VERSION ""

NS_ :

BS_:

BU_: TestTool_HS BCP_HS ECM_HS TCM_HS CGM_HS BCM_HS EBCM_OBD_HS ACCM_HS EBCM_HS TCCM_HS SAS_HS ICCM_OBD_HS ICCM_HS EPS_HS EPB_HS HMIM_HS ONSTAR_HS

BO_ 565 Performan_Mode_Cust_Setings_1_HS: 5 EBCM_HS
 SG_ PerfMdMainMenuType : 2|3@0+ (1,0) [0|7] ""  BCM_HS
 SG_ PSPMCA_PsngStPrfMd6Avl : 24|1@0+ (1,0) [0|1] ""  BCM_HS
 SG_ PSPMCA_PsngStPrfMd5Avl : 25|1@0+ (1,0) [0|1] ""  BCM_HS
 SG_ PSPMCA_PsngStPrfMd4Avl : 26|1@0+ (1,0) [0|1] ""  BCM_HS
 SG_ PSPMCA_PsngStPrfMd3Avl : 27|1@0+ (1,0) [0|1] ""  BCM_HS
 SG_ PSPMCA_PsngStPrfMd2Avl : 28|1@0+ (1,0) [0|1] ""  BCM_HS
 SG_ PSPMCA_PsngStPrfMd1Avl : 29|1@0+ (1,0) [0|1] ""  BCM_HS
 SG_ DSPMCA_DrvStyPrfMd7Avl : 32|1@0+ (1,0) [0|1] ""  BCM_HS
 SG_ DSPMCA_DrvStyPrfMd6Avl : 33|1@0+ (1,0) [0|1] ""  BCM_HS
 SG_ DSPMCA_DrvStyPrfMd5Avl : 34|1@0+ (1,0) [0|1] ""  BCM_HS
 SG_ DSPMCA_DrvStyPrfMd4Avl : 35|1@0+ (1,0) [0|1] ""  BCM_HS
 SG_ DSPMCA_DrvStyPrfMd3Avl : 36|1@0+ (1,0) [0|1] ""  BCM_HS
 SG_ DSPMCA_DrvStyPrfMd2Avl : 37|1@0+ (1,0) [0|1] ""  BCM_HS
 SG_ DSPMCA_DrvStyPrfMd1Avl : 38|1@0+ (1,0) [0|1] ""  BCM_HS
 SG_ DSPMCA_DrvrStPrfMd6Avl : 16|1@0+ (1,0) [0|1] ""  BCM_HS
 SG_ DSPMCA_DrvrStPrfMd5Avl : 17|1@0+ (1,0) [0|1] ""  BCM_HS
 SG_ DSPMCA_DrvrStPrfMd4Avl : 18|1@0+ (1,0) [0|1] ""  BCM_HS
 SG_ DSPMCA_DrvrStPrfMd3Avl : 19|1@0+ (1,0) [0|1] ""  BCM_HS
 SG_ DSPMCA_DrvrStPrfMd2Avl : 20|1@0+ (1,0) [0|1] ""  BCM_HS
 SG_ DSPMCA_DrvrStPrfMd1Avl : 21|1@0+ (1,0) [0|1] ""  BCM_HS
 SG_ ACCPMCA_ACCPrfMd6Avl : 8|1@0+ (1,0) [0|1] ""  BCM_HS
 SG_ ACCPMCA_ACCPrfMd5Avl : 9|1@0+ (1,0) [0|1] ""  BCM_HS
 SG_ ACCPMCA_ACCPrfMd4Avl : 10|1@0+ (1,0) [0|1] ""  BCM_HS
 SG_ ACCPMCA_ACCPrfMd3Avl : 11|1@0+ (1,0) [0|1] ""  BCM_HS
 SG_ ACCPMCA_ACCPrfMd2Avl : 12|1@0+ (1,0) [0|1] ""  BCM_HS
 SG_ ACCPMCA_ACCPrfMd1Avl : 13|1@0+ (1,0) [0|1] ""  BCM_HS

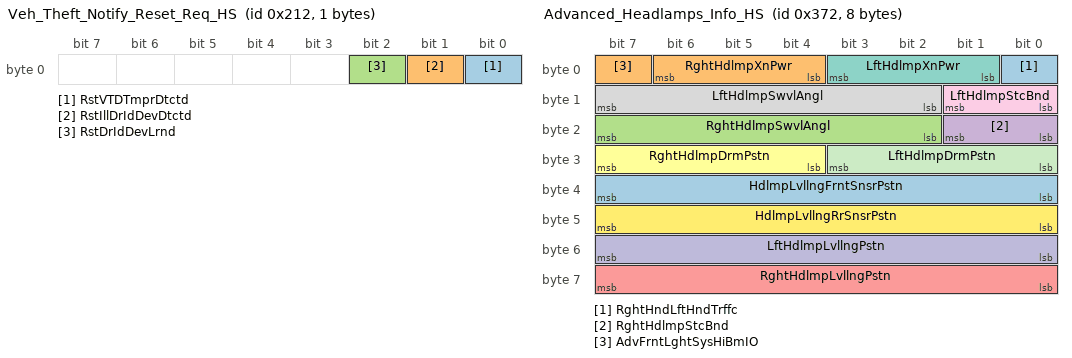
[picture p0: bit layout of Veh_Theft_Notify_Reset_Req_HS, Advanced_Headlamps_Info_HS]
BO_ 530 Veh_Theft_Notify_Reset_Req_HS: 1 CGM_HS
 SG_ RstVTDTmprDtctd : 0|1@0+ (1,0) [0|1] ""  BCM_HS
 SG_ RstIllDrIdDevDtctd : 1|1@0+ (1,0) [0|1] ""  BCM_HS
 SG_ RstDrIdDevLrnd : 2|1@0+ (1,0) [0|1] ""  BCM_HS

BO_ 368 Environment_Id_Resp_5_HS: 3 ONSTAR_HS
 SG_ EnvIdRspSt5 : 17|2@0+ (1,0) [0|3] ""  BCM_HS
 SG_ EnvIdRsp5 : 7|16@0+ (1,0) [0|65535] ""  BCM_HS

BO_ 882 Advanced_Headlamps_Info_HS: 8 CGM_HS
 SG_ RghtHndLftHndTrffc : 0|1@0+ (1,0) [0|1] "" Vector__XXX
 SG_ RghtHdlmpXnPwr : 6|3@0+ (1,32) [32|39] "Watt" Vector__XXX
 SG_ RghtHdlmpSwvlAngl : 23|6@0- (0.5,0) [-16|15.5] "deg" Vector__XXX
 SG_ RghtHdlmpStcBnd : 17|2@0+ (25,25) [25|100] "%" Vector__XXX
 SG_ RghtHdlmpLvllngPstn : 63|8@0- (0.05,0) [-6.4|6.35] "%" Vector__XXX
 SG_ RghtHdlmpDrmPstn : 31|4@0+ (1,1) [1|16] "" Vector__XXX
 SG_ LftHdlmpXnPwr : 3|3@0+ (1,32) [32|39] "Watt" Vector__XXX
 SG_ LftHdlmpSwvlAngl : 15|6@0- (0.5,0) [-16|15.5] "deg" Vector__XXX
 SG_ LftHdlmpStcBnd : 9|2@0+ (25,25) [25|100] "%" Vector__XXX
 SG_ LftHdlmpLvllngPstn : 55|8@0- (0.05,0) [-6.4|6.35] "%" Vector__XXX
 SG_ LftHdlmpDrmPstn : 27|4@0+ (1,1) [1|16] "" Vector__XXX
 SG_ HdlmpLvllngRrSnsrPstn : 47|8@0- (1,0) [-128|127] "mm" Vector__XXX
 SG_ HdlmpLvllngFrntSnsrPstn : 39|8@0- (1,0) [-128|127] "mm" Vector__XXX
 SG_ AdvFrntLghtSysHiBmIO : 7|1@0+ (1,0) [0|1] ""  BCM_HS

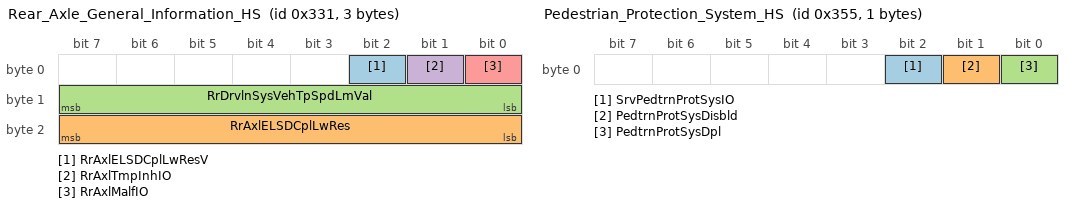
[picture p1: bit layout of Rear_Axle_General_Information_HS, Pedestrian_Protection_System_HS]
BO_ 817 Rear_Axle_General_Information_HS: 3 ICCM_HS
 SG_ RrAxlELSDCplLwResV : 2|1@0+ (1,0) [0|1] ""  BCM_HS
 SG_ RrAxlELSDCplLwRes : 23|8@0+ (10,0) [0|2550] "Nm"  BCM_HS
 SG_ RrDrvlnSysVehTpSpdLmVal : 15|8@0+ (2,0) [0|510] "km/h"  BCM_HS
 SG_ RrAxlTmpInhIO : 1|1@0+ (1,0) [0|1] ""  BCM_HS
 SG_ RrAxlMalfIO : 0|1@0+ (1,0) [0|1] ""  EBCM_OBD_HS,EBCM_HS,BCM_HS

BO_ 853 Pedestrian_Protection_System_HS: 1 CGM_HS
 SG_ SrvPedtrnProtSysIO : 2|1@0+ (1,0) [0|1] ""  BCM_HS
 SG_ PedtrnProtSysDisbld : 1|1@0+ (1,0) [0|1] ""  BCM_HS
 SG_ PedtrnProtSysDpl : 0|1@0+ (1,0) [0|1] ""  BCM_HS

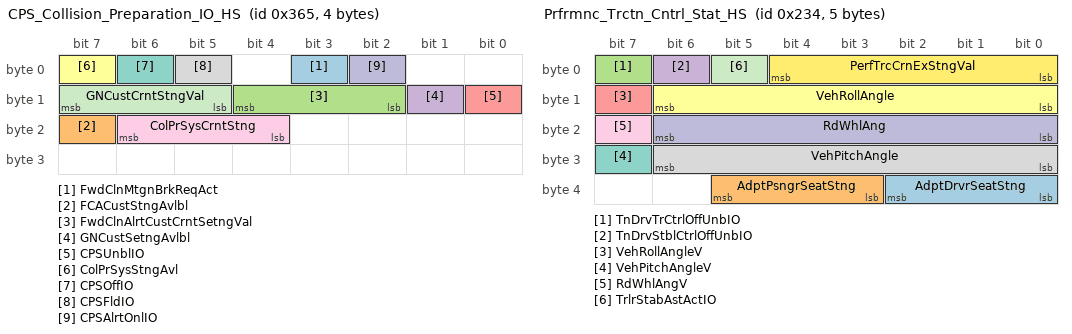
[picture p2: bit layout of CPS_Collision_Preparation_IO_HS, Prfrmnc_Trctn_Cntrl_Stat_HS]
BO_ 869 CPS_Collision_Preparation_IO_HS: 4 CGM_HS
 SG_ FwdClnMtgnBrkReqAct : 3|1@0+ (1,0) [0|1] ""  BCM_HS
 SG_ FCACustStngAvlbl : 23|1@0+ (1,0) [0|1] ""  BCM_HS
 SG_ FwdClnAlrtCustCrntSetngVal : 12|3@0+ (1,0) [0|7] ""  BCM_HS
 SG_ GNCustSetngAvlbl : 9|1@0+ (1,0) [0|1] ""  BCM_HS
 SG_ CPSUnblIO : 8|1@0+ (1,0) [0|1] ""  BCM_HS
 SG_ ColPrSysStngAvl : 7|1@0+ (1,0) [0|1] ""  BCM_HS
 SG_ CPSOffIO : 6|1@0+ (1,0) [0|1] ""  BCM_HS
 SG_ CPSFldIO : 5|1@0+ (1,0) [0|1] ""  BCM_HS
 SG_ ColPrSysCrntStng : 22|3@0+ (1,0) [0|7] ""  BCM_HS
 SG_ CPSAlrtOnlIO : 2|1@0+ (1,0) [0|1] ""  BCM_HS
 SG_ GNCustCrntStngVal : 15|3@0+ (1,0) [0|7] ""  BCM_HS

BO_ 564 Prfrmnc_Trctn_Cntrl_Stat_HS: 5 EBCM_HS
 SG_ AdptDrvrSeatStng : 34|3@0+ (1,0) [0|7] ""  CGM_HS,BCM_HS
 SG_ AdptPsngrSeatStng : 37|3@0+ (1,0) [0|7] ""  CGM_HS,BCM_HS
 SG_ TnDrvTrCtrlOffUnbIO : 7|1@0+ (1,0) [0|1] ""  CGM_HS,BCM_HS
 SG_ TnDrvStblCtrlOffUnbIO : 6|1@0+ (1,0) [0|1] ""  CGM_HS,BCM_HS
 SG_ VehRollAngleV : 15|1@0+ (1,0) [0|1] ""  CGM_HS,BCM_HS
 SG_ VehRollAngle : 14|7@0+ (0.703125,-45) [-45|44.296875] "deg"  CGM_HS,BCM_HS
 SG_ VehPitchAngleV : 31|1@0+ (1,0) [0|1] ""  CGM_HS,BCM_HS
 SG_ VehPitchAngle : 30|7@0+ (0.703125,-45) [-45|44.296875] "deg"  CGM_HS,BCM_HS
 SG_ RdWhlAngV : 23|1@0+ (1,0) [0|1] ""  CGM_HS,BCM_HS
 SG_ RdWhlAng : 22|7@0+ (0.703125,-45) [-45|44.296875] "deg"  CGM_HS,BCM_HS
 SG_ TrlrStabAstActIO : 5|1@0+ (1,0) [0|1] ""  CGM_HS,BCM_HS
 SG_ PerfTrcCrnExStngVal : 4|5@0+ (1,0) [0|31] ""  CGM_HS,BCM_HS

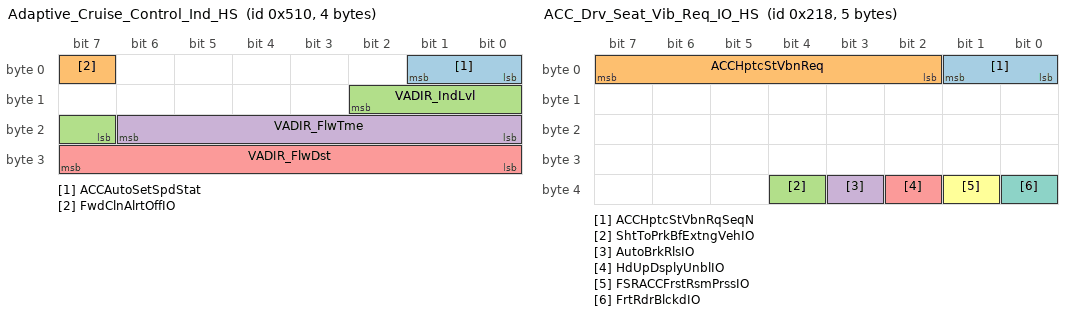
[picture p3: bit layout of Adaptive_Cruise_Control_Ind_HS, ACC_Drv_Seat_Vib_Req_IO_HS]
BO_ 1296 Adaptive_Cruise_Control_Ind_HS: 4 CGM_HS
 SG_ ACCAutoSetSpdStat : 1|2@0+ (1,0) [0|3] ""  BCM_HS
 SG_ FwdClnAlrtOffIO : 7|1@0+ (1,0) [0|1] ""  BCM_HS
 SG_ VADIR_IndLvl : 10|4@0+ (1,0) [0|15] ""  BCM_HS
 SG_ VADIR_FlwTme : 22|7@0+ (0.1,0) [0|12.7] "s"  BCM_HS
 SG_ VADIR_FlwDst : 31|8@0+ (1,0) [0|255] "m"  BCM_HS

BO_ 536 ACC_Drv_Seat_Vib_Req_IO_HS: 5 CGM_HS
 SG_ ACCHptcStVbnRqSeqN : 1|2@0+ (1,0) [0|3] ""  BCM_HS
 SG_ ACCHptcStVbnReq : 7|6@0+ (1,0) [0|63] ""  BCM_HS
 SG_ ShtToPrkBfExtngVehIO : 36|1@0+ (1,0) [0|1] ""  BCM_HS
 SG_ AutoBrkRlsIO : 35|1@0+ (1,0) [0|1] ""  BCM_HS
 SG_ HdUpDsplyUnblIO : 34|1@0+ (1,0) [0|1] ""  BCM_HS
 SG_ FSRACCFrstRsmPrssIO : 33|1@0+ (1,0) [0|1] ""  BCM_HS
 SG_ FrtRdrBlckdIO : 32|1@0+ (1,0) [0|1] ""  BCM_HS

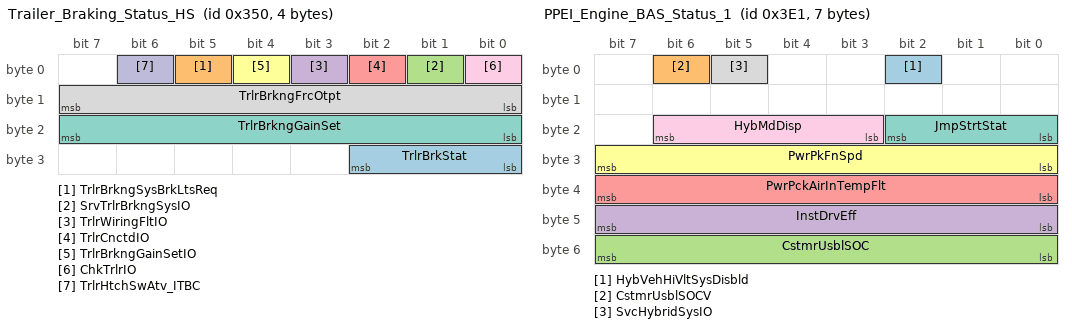
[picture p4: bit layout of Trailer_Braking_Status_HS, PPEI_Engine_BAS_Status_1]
BO_ 848 Trailer_Braking_Status_HS: 4 ICCM_HS
 SG_ TrlrBrkStat : 26|3@0+ (1,0) [0|7] ""  CGM_HS,EBCM_OBD_HS,EBCM_HS
 SG_ TrlrBrkngSysBrkLtsReq : 5|1@0+ (1,0) [0|1] ""  CGM_HS,BCM_HS
 SG_ SrvTrlrBrkngSysIO : 1|1@0+ (1,0) [0|1] ""  CGM_HS,BCM_HS
 SG_ TrlrWiringFltIO : 3|1@0+ (1,0) [0|1] ""  CGM_HS,BCM_HS
 SG_ TrlrCnctdIO : 2|1@0+ (1,0) [0|1] ""  CGM_HS,BCM_HS
 SG_ TrlrBrkngGainSetIO : 4|1@0+ (1,0) [0|1] ""  CGM_HS,BCM_HS
 SG_ TrlrBrkngGainSet : 23|8@0+ (0.392157,0) [0|100.000035] "%"  CGM_HS,EBCM_OBD_HS,EBCM_HS,BCM_HS
 SG_ TrlrBrkngFrcOtpt : 15|8@0+ (0.392157,0) [0|100.000035] "%"  CGM_HS,EBCM_OBD_HS,EBCM_HS,BCM_HS
 SG_ ChkTrlrIO : 0|1@0+ (1,0) [0|1] ""  CGM_HS,BCM_HS
 SG_ TrlrHtchSwAtv_ITBC : 6|1@0+ (1,0) [0|1] ""  CGM_HS,BCM_HS

BO_ 993 PPEI_Engine_BAS_Status_1: 7 BCP_HS
 SG_ HybVehHiVltSysDisbld : 2|1@0+ (1,0) [0|1] ""  CGM_HS,ONSTAR_HS
 SG_ CstmrUsblSOCV : 6|1@0+ (1,0) [0|1] ""  CGM_HS,BCM_HS
 SG_ CstmrUsblSOC : 55|8@0+ (0.39216,0) [0|100.0008] "%"  CGM_HS,BCM_HS
 SG_ InstDrvEff : 47|8@0- (0.78125,0) [-100|99.21875] "%"  CGM_HS,BCM_HS
 SG_ PwrPckAirInTempFlt : 39|8@0+ (1,-40) [-40|215] "deg C"  CGM_HS,BCM_HS
 SG_ PwrPkFnSpd : 31|8@0+ (0.392157,0) [0|100.000035] "%"  CGM_HS,BCM_HS
 SG_ JmpStrtStat : 18|3@0+ (1,0) [0|7] ""  CGM_HS,BCM_HS
 SG_ SvcHybridSysIO : 5|1@0+ (1,0) [0|1] ""  CGM_HS,BCM_HS
 SG_ HybMdDisp : 22|4@0+ (1,0) [0|15] ""  CGM_HS,BCM_HS

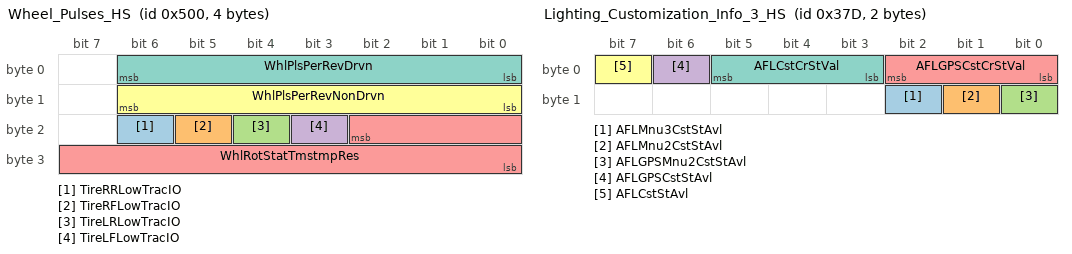
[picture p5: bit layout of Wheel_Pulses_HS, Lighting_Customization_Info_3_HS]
BO_ 1280 Wheel_Pulses_HS: 4 EBCM_HS
 SG_ TireRRLowTracIO : 22|1@0+ (1,0) [0|1] ""  CGM_HS,BCM_HS
 SG_ TireRFLowTracIO : 21|1@0+ (1,0) [0|1] ""  CGM_HS,BCM_HS
 SG_ TireLRLowTracIO : 20|1@0+ (1,0) [0|1] ""  CGM_HS,BCM_HS
 SG_ TireLFLowTracIO : 19|1@0+ (1,0) [0|1] ""  CGM_HS,BCM_HS
 SG_ WhlRotStatTmstmpRes : 18|11@0+ (0.002,0) [0|4.094] "uSec"  CGM_HS,ICCM_OBD_HS,HMIM_HS,EPS_HS,ICCM_HS,EPB_HS,TCCM_HS,BCM_HS
 SG_ WhlPlsPerRevNonDrvn : 14|7@0+ (1,0) [0|127] ""  CGM_HS,ICCM_OBD_HS,HMIM_HS,ONSTAR_HS,EPS_HS,ICCM_HS,EPB_HS,TCCM_HS,BCM_HS
 SG_ WhlPlsPerRevDrvn : 6|7@0+ (1,0) [0|127] ""  CGM_HS,ICCM_OBD_HS,HMIM_HS,ONSTAR_HS,EPS_HS,ICCM_HS,EPB_HS,TCCM_HS,BCM_HS

BO_ 562 Driving_Mode_Control_HS: 8 EBCM_HS
 SG_ DrvlneMntsPerfMdRq : 50|3@0+ (1,0) [0|7] ""  CGM_HS,ICCM_OBD_HS,ICCM_HS
 SG_ RideCntrlPerfMdRq : 18|3@0+ (1,0) [0|7] ""  CGM_HS
 SG_ StgSysPerfMdRq : 29|3@0+ (1,0) [0|7] ""  CGM_HS,EPS_HS
 SG_ DiffPerfMdRq : 26|3@0+ (1,0) [0|7] ""  CGM_HS,ICCM_OBD_HS,ICCM_HS
 SG_ ExhstPerfMdRq : 5|3@0+ (1,0) [0|7] ""  CGM_HS,ICCM_OBD_HS,ICCM_HS
 SG_ DrvMdCntrlState : 39|8@0+ (1,0) [0|255] ""  CGM_HS,EPS_HS
 SG_ AWDPerfMdRq : 2|3@0+ (1,0) [0|7] ""  CGM_HS,TCCM_HS
 SG_ DispPerfMdCsCrStVal : 58|3@0+ (1,0) [0|7] ""  CGM_HS,BCM_HS
 SG_ SndEnhcmtPerfMdRq : 13|3@0+ (1,0) [0|7] ""  CGM_HS,BCM_HS
 SG_ DsplyPerfMdRq : 10|3@0+ (1,0) [0|7] ""  CGM_HS,BCM_HS
 SG_ HillDscntCntlSysStat : 55|3@0+ (1,0) [0|7] ""  CGM_HS,BCM_HS
 SG_ SusCustStngAvlbl : 23|1@0+ (1,0) [0|1] ""  CGM_HS,ONSTAR_HS,BCM_HS
 SG_ SusCustCurrStngVal : 45|3@0+ (1,0) [0|7] ""  CGM_HS,ONSTAR_HS,BCM_HS
 SG_ StrCustStngAvlbl : 7|1@0+ (1,0) [0|1] ""  CGM_HS,ONSTAR_HS,BCM_HS
 SG_ StrCustCurrStngVal : 42|3@0+ (1,0) [0|7] ""  CGM_HS,ONSTAR_HS,BCM_HS
 SG_ DrvlnCustStngAvlbl : 6|1@0+ (1,0) [0|1] ""  CGM_HS,ONSTAR_HS,BCM_HS
 SG_ DrvlnCustCurrStngVal : 22|3@0+ (1,0) [0|7] ""  CGM_HS,ONSTAR_HS,BCM_HS
 SG_ SndPerfMdCsStAvl : 63|1@0+ (1,0) [0|1] ""  CGM_HS,BCM_HS
 SG_ SndPerfMdCsCrStVal : 62|3@0+ (1,0) [0|7] ""  CGM_HS,BCM_HS
 SG_ DispPerfMdCsStAvl : 59|1@0+ (1,0) [0|1] ""  CGM_HS,BCM_HS

BO_ 893 Lighting_Customization_Info_3_HS: 2 CGM_HS
 SG_ AFLMnu3CstStAvl : 10|1@0+ (1,0) [0|1] ""  BCM_HS
 SG_ AFLMnu2CstStAvl : 9|1@0+ (1,0) [0|1] ""  BCM_HS
 SG_ AFLGPSMnu2CstStAvl : 8|1@0+ (1,0) [0|1] ""  BCM_HS
 SG_ AFLGPSCstStAvl : 6|1@0+ (1,0) [0|1] ""  BCM_HS
 SG_ AFLGPSCstCrStVal : 2|3@0+ (1,0) [0|7] ""  BCM_HS
 SG_ AFLCstStAvl : 7|1@0+ (1,0) [0|1] ""  BCM_HS
 SG_ AFLCstCrStVal : 5|3@0+ (1,0) [0|7] ""  BCM_HS

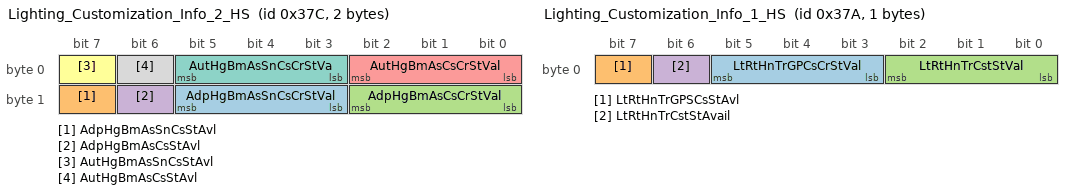
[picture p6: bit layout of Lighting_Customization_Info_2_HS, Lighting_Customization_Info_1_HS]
BO_ 892 Lighting_Customization_Info_2_HS: 2 CGM_HS
 SG_ AdpHgBmAsSnCsCrStVal : 13|3@0+ (1,0) [0|7] ""  BCM_HS
 SG_ AdpHgBmAsSnCsStAvl : 15|1@0+ (1,0) [0|1] ""  BCM_HS
 SG_ AdpHgBmAsCsCrStVal : 10|3@0+ (1,0) [0|7] ""  BCM_HS
 SG_ AdpHgBmAsCsStAvl : 14|1@0+ (1,0) [0|1] ""  BCM_HS
 SG_ AutHgBmAsCsCrStVal : 2|3@0+ (1,0) [0|7] ""  BCM_HS
 SG_ AutHgBmAsSnCsStAvl : 7|1@0+ (1,0) [0|1] ""  BCM_HS
 SG_ AutHgBmAsSnCsCrStVa : 5|3@0+ (1,0) [0|7] ""  BCM_HS
 SG_ AutHgBmAsCsStAvl : 6|1@0+ (1,0) [0|1] ""  BCM_HS

BO_ 386 Environment_Id_Resp_4_HS: 8 EBCM_HS
 SG_ AHAct : 31|1@0+ (1,0) [0|1] ""  CGM_HS,BCM_HS
 SG_ AHEnbld : 30|1@0+ (1,0) [0|1] ""  CGM_HS,BCM_HS
 SG_ ShfToPrkBfExtngIO : 29|1@0+ (1,0) [0|1] ""  CGM_HS,BCM_HS
 SG_ AHServcIO : 28|1@0+ (1,0) [0|1] ""  CGM_HS,BCM_HS
 SG_ AHAppBrkPedlIO : 27|1@0+ (1,0) [0|1] ""  CGM_HS,BCM_HS
 SG_ AHDisbldStbltIO : 26|1@0+ (1,0) [0|1] ""  CGM_HS,BCM_HS
 SG_ AHDisbldDrOpnIO : 25|1@0+ (1,0) [0|1] ""  CGM_HS,BCM_HS
 SG_ PMVSS_Disps : 58|3@0+ (1,0) [0|7] ""  CGM_HS,BCM_HS
 SG_ PMVSS_Exhst : 61|3@0+ (1,0) [0|7] ""  CGM_HS,BCM_HS
 SG_ PMVSS_PsngrSeat : 48|3@0+ (1,0) [0|7] ""  CGM_HS,BCM_HS
 SG_ PMVSS_DrvrSeat : 51|3@0+ (1,0) [0|7] ""  CGM_HS,BCM_HS
 SG_ PMVSS_AdptCrsCnt : 54|3@0+ (1,0) [0|7] ""  CGM_HS,BCM_HS
 SG_ PMVSS_Drvln : 41|3@0+ (1,0) [0|7] ""  CGM_HS,BCM_HS
 SG_ PMVSS_Susp : 44|3@0+ (1,0) [0|7] ""  CGM_HS,BCM_HS
 SG_ PMVSS_Strng : 47|3@0+ (1,0) [0|7] ""  CGM_HS,BCM_HS
 SG_ PMVSS_Trans : 34|3@0+ (1,0) [0|7] ""  CGM_HS,BCM_HS
 SG_ PMVSS_Eng : 37|3@0+ (1,0) [0|7] ""  CGM_HS,BCM_HS
 SG_ PMVSS_Snd : 24|3@0+ (1,0) [0|7] ""  CGM_HS,BCM_HS
 SG_ EnvIdRsp4 : 7|16@0+ (1,0) [0|65535] ""  CGM_HS,BCM_HS
 SG_ EnvIdRspSt4 : 17|2@0+ (1,0) [0|3] ""  CGM_HS,BCM_HS
 SG_ AdptCruzCtrlStg : 20|3@0+ (1,0) [0|7] ""  CGM_HS

BO_ 532 Brake_Pedal_Driver_Status_HS: 6 EBCM_HS
 SG_ RedntVSEActARC : 38|2@0+ (1,0) [0|3] ""  CGM_HS,ICCM_OBD_HS,EPS_HS,ICCM_HS
 SG_ RedntVSEAct : 39|1@0+ (1,0) [0|1] ""  CGM_HS,ICCM_OBD_HS,EPS_HS,ICCM_HS
 SG_ AutoBrkngActARC : 22|2@0+ (1,0) [0|3] ""  CGM_HS,ICCM_OBD_HS,ICCM_HS
 SG_ VehHldDrvrDsblActvFlg : 36|1@0+ (1,0) [0|1] ""  CGM_HS,EPB_HS
 SG_ ABSAutnmsBrkReqPVal : 41|2@0+ (1,0) [0|3] ""  CGM_HS,EPB_HS
 SG_ AutoBrkngAvlbl : 17|1@0+ (1,0) [0|1] ""  CGM_HS,EPS_HS,EPB_HS
 SG_ ABSAutnmsBrkReqARC : 35|2@0+ (1,0) [0|3] ""  CGM_HS,EPB_HS
 SG_ ABSAutnmsBrkReq : 33|1@0+ (1,0) [0|1] ""  CGM_HS,EPB_HS
 SG_ ABSActvProtPVal : 43|2@0+ (1,0) [0|3] ""  CGM_HS,ICCM_OBD_HS,EPS_HS,ICCM_HS
 SG_ ABSActvProtARC : 45|2@0+ (1,0) [0|3] ""  CGM_HS,ICCM_OBD_HS,EPS_HS,ICCM_HS
 SG_ ABSActvProt : 46|1@0+ (1,0) [0|1] ""  CGM_HS,ICCM_OBD_HS,EPS_HS,ICCM_HS
 SG_ HilRlbkCtrlActIO : 19|1@0+ (1,0) [0|1] ""  CGM_HS,BCM_HS
 SG_ HlStrAssActIO : 20|1@0+ (1,0) [0|1] ""  CGM_HS,BCM_HS
 SG_ BrkSysAutBrkFld : 5|1@0+ (1,0) [0|1] ""  CGM_HS,EPB_HS,BCM_HS
 SG_ IntBrkAssPreFilReq : 4|1@0+ (1,0) [0|1] "N/A"  CGM_HS,BCM_HS
 SG_ BrkSysMalFuncIndOn : 3|1@0+ (1,0) [0|1] ""  CGM_HS,BCM_HS
 SG_ BPDAPS_BkPDrvApPV : 8|1@0+ (1,0) [0|1] ""  CGM_HS,ICCM_OBD_HS,ICCM_HS,EPB_HS,BCM_HS
 SG_ BPDAPS_BkPDrvApP : 0|8@0+ (75,0) [0|19125] "kPa"  CGM_HS,ICCM_OBD_HS,ICCM_HS,EPB_HS,BCM_HS
 SG_ BrkFldLvlLwV : 7|1@0+ (1,0) [0|1] ""  CGM_HS,BCM_HS
 SG_ BrkFldLvlLw : 6|1@0+ (1,0) [0|1] ""  CGM_HS,BCM_HS
 SG_ BrkPdDrvAPrsStaPVal : 16|9@0+ (1,0) [0|511] ""  CGM_HS,ICCM_OBD_HS,ICCM_HS,EPB_HS
 SG_ BrkPdDrvAppPrsAlRC : 2|2@0+ (1,0) [0|3] ""  CGM_HS,ICCM_OBD_HS,ICCM_HS,EPB_HS
 SG_ AutoBrkngAct : 18|1@0+ (1,0) [0|1] ""  CGM_HS,ICCM_OBD_HS,ICCM_HS,EPB_HS

BO_ 890 Lighting_Customization_Info_1_HS: 1 CGM_HS
 SG_ LtRtHnTrGPCsCrStVal : 5|3@0+ (1,0) [0|7] ""  BCM_HS
 SG_ LtRtHnTrGPSCsStAvl : 7|1@0+ (1,0) [0|1] ""  BCM_HS
 SG_ LtRtHnTrCstStVal : 2|3@0+ (1,0) [0|7] ""  BCM_HS
 SG_ LtRtHnTrCstStAvail : 6|1@0+ (1,0) [0|1] ""  BCM_HS

BO_ 328 Power_Steering_Information_HS: 1 EBCM_HS
 SG_ StrngAsstRdcdIO : 1|1@0+ (1,0) [0|1] ""  BCM_HS
 SG_ PwrStrIO : 0|1@0+ (1,0) [0|1] ""  EPB_HS,BCM_HS

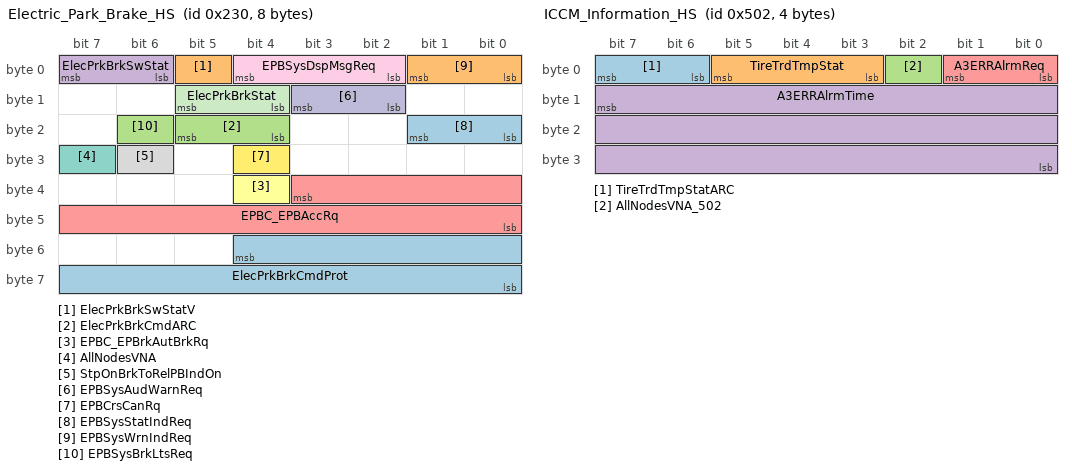
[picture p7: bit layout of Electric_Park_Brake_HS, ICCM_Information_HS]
BO_ 560 Electric_Park_Brake_HS: 8 EBCM_HS
 SG_ ElecPrkBrkCmdProt : 52|13@0+ (1,0) [0|8191] ""  CGM_HS,EBCM_OBD_HS,EBCM_HS
 SG_ ElecPrkBrkSwStatV : 5|1@0+ (1,0) [0|1] ""  CGM_HS,EBCM_OBD_HS,EBCM_HS
 SG_ ElecPrkBrkCmdARC : 21|2@0+ (1,0) [0|3] ""  CGM_HS,EBCM_OBD_HS,EBCM_HS
 SG_ ElecPrkBrkSwStat : 7|2@0+ (1,0) [0|3] ""  CGM_HS,EBCM_OBD_HS,EBCM_HS
 SG_ EPBC_EPBAccRq : 35|12@0- (0.01,0) [-20.48|20.47] "m/s^2"  CGM_HS,EBCM_OBD_HS,EBCM_HS
 SG_ EPBC_EPBrkAutBrkRq : 36|1@0+ (1,0) [0|1] ""  CGM_HS,EBCM_OBD_HS,EBCM_HS
 SG_ AllNodesVNA : 31|1@0+ (1,0) [0|1] ""  CGM_HS,BCM_HS
 SG_ StpOnBrkToRelPBIndOn : 30|1@0+ (1,0) [0|1] ""  CGM_HS,BCM_HS
 SG_ EPBSysDspMsgReq : 4|3@0+ (1,0) [0|7] ""  CGM_HS,BCM_HS
 SG_ EPBSysAudWarnReq : 11|2@0+ (1,0) [0|3] ""  CGM_HS,BCM_HS
 SG_ ElecPrkBrkStat : 13|2@0+ (1,0) [0|3] ""  CGM_HS,ICCM_OBD_HS,EBCM_OBD_HS,ICCM_HS,EBCM_HS,BCM_HS
 SG_ EPBCrsCanRq : 28|1@0+ (1,0) [0|1] ""  CGM_HS,EBCM_OBD_HS,EBCM_HS,BCM_HS
 SG_ EPBSysStatIndReq : 17|2@0+ (1,0) [0|3] ""  CGM_HS,BCM_HS
 SG_ EPBSysWrnIndReq : 1|2@0+ (1,0) [0|3] ""  CGM_HS,BCM_HS
 SG_ EPBSysBrkLtsReq : 22|1@0+ (1,0) [0|1] ""  CGM_HS,BCM_HS

BO_ 1282 ICCM_Information_HS: 4 ICCM_HS
 SG_ TireTrdTmpStatARC : 7|2@0+ (1,0) [0|3] ""  EBCM_OBD_HS,EBCM_HS
 SG_ TireTrdTmpStat : 5|3@0+ (1,0) [0|7] ""  EBCM_OBD_HS,EBCM_HS,BCM_HS
 SG_ AllNodesVNA_502 : 2|1@0+ (1,0) [0|1] ""  BCM_HS
 SG_ A3ERRAlrmTime : 15|24@0+ (1,0) [0|16777215] "min"  BCM_HS
 SG_ A3ERRAlrmReq : 1|2@0+ (1,0) [0|3] ""  BCM_HS

BO_ 2033 PCU_Req_to_SDM_HS: 8 TestTool_HS
 SG_ PCUInfo : 7|64@0+ (1,0) [0|1.84467440737096E+019] ""  BCM_HS

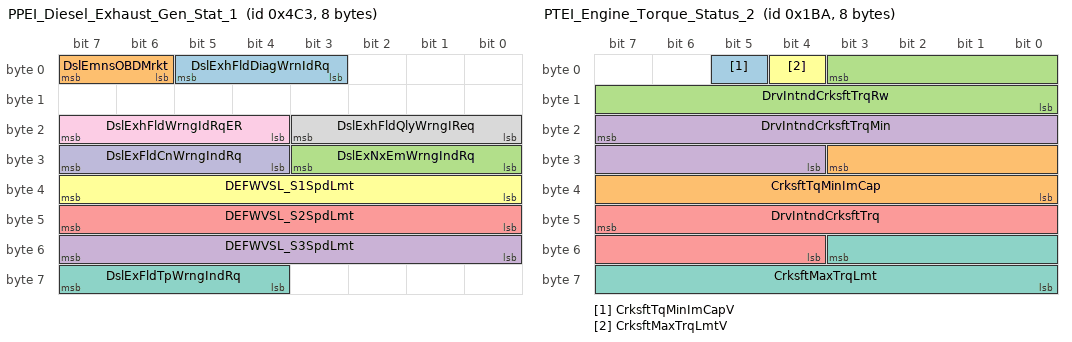
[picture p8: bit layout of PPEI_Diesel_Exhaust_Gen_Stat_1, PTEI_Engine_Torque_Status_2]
BO_ 1219 PPEI_Diesel_Exhaust_Gen_Stat_1: 8 ECM_HS
 SG_ DslExhFldDiagWrnIdRq : 5|3@0+ (1,0) [0|7] ""  CGM_HS,BCM_HS
 SG_ DslEmnsOBDMrkt : 7|2@0+ (1,0) [0|3] ""  CGM_HS,BCM_HS
 SG_ DslExNxEmWrngIndRq : 27|4@0+ (1,0) [0|15] ""  CGM_HS,BCM_HS
 SG_ DEFWVSL_S3SpdLmt : 55|8@0+ (1,0) [0|255] "km / h"  CGM_HS,BCM_HS
 SG_ DEFWVSL_S2SpdLmt : 47|8@0+ (1,0) [0|255] "km / h"  CGM_HS,BCM_HS
 SG_ DEFWVSL_S1SpdLmt : 39|8@0+ (1,0) [0|255] "km / h"  CGM_HS,BCM_HS
 SG_ DslExFldTpWrngIndRq : 63|4@0+ (1,0) [0|15] ""  CGM_HS,BCM_HS
 SG_ DslExhFldQlyWrngIReq : 19|4@0+ (1,0) [0|15] ""  CGM_HS,BCM_HS
 SG_ DslExhFldWrngIdRqER : 23|4@0+ (1,0) [0|15] ""  CGM_HS,ONSTAR_HS,BCM_HS
 SG_ DslExFldCnWrngIndRq : 31|4@0+ (1,0) [0|15] ""  CGM_HS,BCM_HS

BO_ 442 PTEI_Engine_Torque_Status_2: 8 ECM_HS
 SG_ CrksftTqMinImCapV : 5|1@0+ (1,0) [0|1] ""  TCM_HS
 SG_ CrksftTqMinImCap : 27|12@0+ (0.5,-848) [-848|1199.5] "Nm"  TCM_HS
 SG_ DrvIntndCrksftTrqRw : 3|12@0+ (0.5,-848) [-848|1199.5] "Nm"  TCM_HS
 SG_ DrvIntndCrksftTrqMin : 23|12@0+ (0.5,-848) [-848|1199.5] "Nm"  TCM_HS
 SG_ DrvIntndCrksftTrq : 47|12@0+ (0.5,-848) [-848|1199.5] "Nm"  TCM_HS
 SG_ CrksftMaxTrqLmtV : 4|1@0+ (1,0) [0|1] ""  TCM_HS
 SG_ CrksftMaxTrqLmt : 51|12@0+ (0.5,-848) [-848|1199.5] "Nm"  TCM_HS

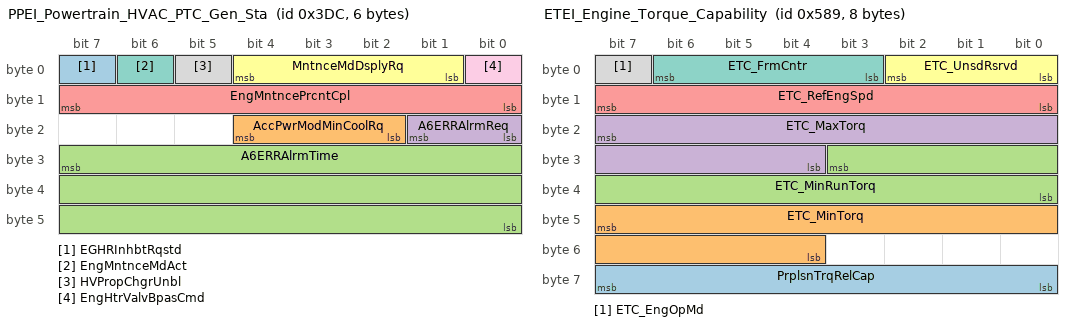
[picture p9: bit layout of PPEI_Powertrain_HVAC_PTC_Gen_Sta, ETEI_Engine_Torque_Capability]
BO_ 988 PPEI_Powertrain_HVAC_PTC_Gen_Sta: 6 ECM_HS
 SG_ EGHRInhbtRqstd : 7|1@0+ (1,0) [0|1] "" Vector__XXX
 SG_ AccPwrModMinCoolRq : 20|3@0+ (1,0) [0|7] "" Vector__XXX
 SG_ A6ERRAlrmTime : 31|24@0+ (1,0) [0|16777215] "min" Vector__XXX
 SG_ A6ERRAlrmReq : 17|2@0+ (1,0) [0|3] "" Vector__XXX
 SG_ EngMntncePrcntCpl : 15|8@0+ (0.392157,0) [0|100.000035] "%" Vector__XXX
 SG_ MntnceMdDsplyRq : 4|4@0+ (1,0) [0|15] "" Vector__XXX
 SG_ EngMntnceMdAct : 6|1@0+ (1,0) [0|1] "" Vector__XXX
 SG_ HVPropChgrUnbl : 5|1@0+ (1,0) [0|1] "" Vector__XXX
 SG_ EngHtrValvBpasCmd : 0|1@0+ (1,0) [0|1] "" Vector__XXX

BO_ 500 PPEI_Drv_Pref_Mode_Switch_Status: 6 ECM_HS
 SG_ EnhDrvMdSwChUseAct : 40|1@0+ (1,0) [0|1] ""  CGM_HS,EBCM_OBD_HS,EBCM_HS
 SG_ EnhDrvSelMdSwStat : 42|2@0+ (1,0) [0|3] ""  CGM_HS,EBCM_OBD_HS,EBCM_HS
 SG_ DrvSelMd8Stat : 17|1@0+ (1,0) [0|1] ""  CGM_HS,EBCM_OBD_HS,EBCM_HS,BCM_HS
 SG_ DrvSelMd8ReqDnd : 16|1@0+ (1,0) [0|1] ""  CGM_HS,BCM_HS
 SG_ DrvSelMd7Stat : 19|1@0+ (1,0) [0|1] ""  CGM_HS,EBCM_OBD_HS,EBCM_HS,BCM_HS
 SG_ DrvSelMd7ReqDnd : 18|1@0+ (1,0) [0|1] ""  CGM_HS,BCM_HS
 SG_ DrvSelMd6Stat : 21|1@0+ (1,0) [0|1] ""  CGM_HS,EBCM_OBD_HS,EBCM_HS,BCM_HS
 SG_ DrvSelMd6ReqDnd : 20|1@0+ (1,0) [0|1] ""  CGM_HS,BCM_HS
 SG_ DrvSelMd5Stat : 23|1@0+ (1,0) [0|1] ""  CGM_HS,EBCM_OBD_HS,EBCM_HS,BCM_HS
 SG_ DrvSelMd5ReqDnd : 22|1@0+ (1,0) [0|1] ""  CGM_HS,BCM_HS
 SG_ DrvSelMd4Stat : 9|1@0+ (1,0) [0|1] ""  CGM_HS,EBCM_OBD_HS,EBCM_HS,BCM_HS
 SG_ DrvSelMd4ReqDnd : 8|1@0+ (1,0) [0|1] ""  CGM_HS,BCM_HS
 SG_ DrvSelMd3Stat : 11|1@0+ (1,0) [0|1] ""  CGM_HS,EBCM_OBD_HS,EBCM_HS,BCM_HS
 SG_ DrvSelMd3ReqDnd : 10|1@0+ (1,0) [0|1] ""  CGM_HS,BCM_HS
 SG_ DrvSelMd2Stat : 13|1@0+ (1,0) [0|1] ""  CGM_HS,EBCM_OBD_HS,EBCM_HS,BCM_HS
 SG_ DrvSelMd2ReqDnd : 12|1@0+ (1,0) [0|1] ""  CGM_HS,BCM_HS
 SG_ DSMSS_DrvSelMd0Pn : 47|1@0+ (1,0) [0|1] ""  CGM_HS,EBCM_OBD_HS,EBCM_HS,BCM_HS
 SG_ DSMSS_DrvSelMd8Pn : 32|1@0+ (1,0) [0|1] ""  CGM_HS,EBCM_OBD_HS,EBCM_HS,BCM_HS
 SG_ DSMSS_DrvSelMd7Pn : 33|1@0+ (1,0) [0|1] ""  CGM_HS,EBCM_OBD_HS,EBCM_HS,BCM_HS
 SG_ DSMSS_DrvSelMd6Pn : 34|1@0+ (1,0) [0|1] ""  CGM_HS,EBCM_OBD_HS,EBCM_HS,BCM_HS
 SG_ DSMSS_DrvSelMd5Pn : 35|1@0+ (1,0) [0|1] ""  CGM_HS,EBCM_OBD_HS,EBCM_HS,BCM_HS
 SG_ DSMSS_DrvSelMd4Pn : 36|1@0+ (1,0) [0|1] ""  CGM_HS,EBCM_OBD_HS,EBCM_HS,BCM_HS
 SG_ DSMSS_DrvSelMd3Pn : 37|1@0+ (1,0) [0|1] ""  CGM_HS,EBCM_OBD_HS,EBCM_HS,BCM_HS
 SG_ DSMSS_DrvSelMd2Pn : 38|1@0+ (1,0) [0|1] ""  CGM_HS,EBCM_OBD_HS,EBCM_HS,BCM_HS
 SG_ DSMSS_DrvSelMd1Pn : 39|1@0+ (1,0) [0|1] ""  CGM_HS,EBCM_OBD_HS,EBCM_HS,BCM_HS
 SG_ DSMSS_DrvSelMd8Un : 24|1@0+ (1,0) [0|1] ""  CGM_HS,EBCM_OBD_HS,EBCM_HS,BCM_HS
 SG_ DSMSS_DrvSelMd7Un : 25|1@0+ (1,0) [0|1] ""  CGM_HS,EBCM_OBD_HS,EBCM_HS,BCM_HS
 SG_ DSMSS_DrvSelMd6Un : 26|1@0+ (1,0) [0|1] ""  CGM_HS,EBCM_OBD_HS,EBCM_HS,BCM_HS
 SG_ DSMSS_DrvSelMd5Un : 27|1@0+ (1,0) [0|1] ""  CGM_HS,EBCM_OBD_HS,EBCM_HS,BCM_HS
 SG_ DSMSS_DrvSelMd4Un : 28|1@0+ (1,0) [0|1] ""  CGM_HS,EBCM_OBD_HS,EBCM_HS,BCM_HS
 SG_ DSMSS_DrvSelMd3Un : 29|1@0+ (1,0) [0|1] ""  CGM_HS,EBCM_OBD_HS,EBCM_HS,BCM_HS
 SG_ DSMSS_DrvSelMd2Un : 30|1@0+ (1,0) [0|1] ""  CGM_HS,EBCM_OBD_HS,EBCM_HS,BCM_HS
 SG_ DSMSS_DrvSelMd1Un : 31|1@0+ (1,0) [0|1] ""  CGM_HS,EBCM_OBD_HS,EBCM_HS,BCM_HS
 SG_ DrvSelMd1ReqDnd : 14|1@0+ (1,0) [0|1] ""  CGM_HS,BCM_HS
 SG_ DrvSelMd1Stat : 15|1@0+ (1,0) [0|1] ""  CGM_HS,EBCM_OBD_HS,EBCM_HS,BCM_HS

BO_ 1417 ETEI_Engine_Torque_Capability: 8 ECM_HS
 SG_ PrplsnTrqRelCap : 63|8@0+ (0.5,0) [0|127.5] "%"  TCM_HS
 SG_ ETC_MinTorq : 47|12@0+ (0.5,-848) [-848|1199.5] "Nm"  BCP_HS,TCM_HS
 SG_ ETC_MinRunTorq : 27|12@0+ (0.5,-848) [-848|1199.5] "Nm"  BCP_HS,TCM_HS
 SG_ ETC_MaxTorq : 23|12@0+ (0.5,-848) [-848|1199.5] "Nm"  BCP_HS,TCM_HS
 SG_ ETC_RefEngSpd : 15|8@0+ (32,0) [0|8160] "rpm"  BCP_HS,TCM_HS
 SG_ ETC_UnsdRsrvd : 2|3@0+ (1,0) [0|7] ""  BCP_HS,TCM_HS
 SG_ ETC_FrmCntr : 6|4@0+ (1,0) [0|15] ""  BCP_HS,TCM_HS
 SG_ ETC_EngOpMd : 7|1@0+ (1,0) [0|1] ""  BCP_HS,TCM_HS

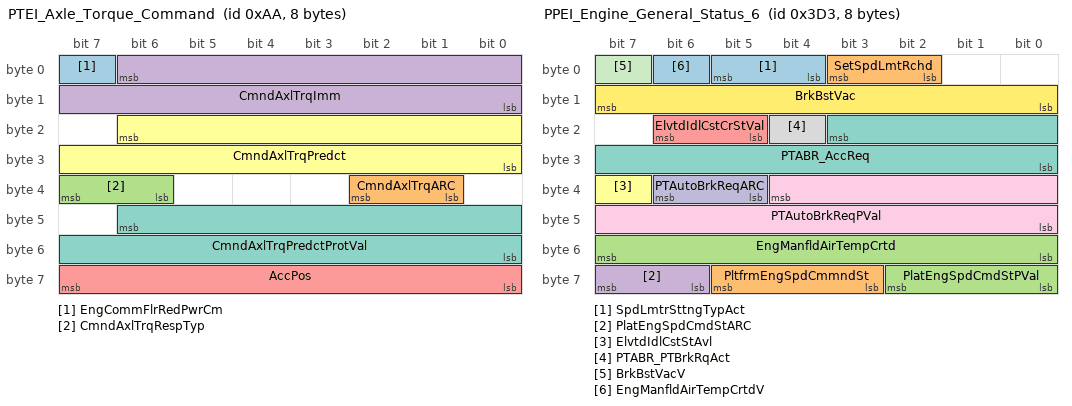
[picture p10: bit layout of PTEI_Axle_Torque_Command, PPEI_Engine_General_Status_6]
BO_ 170 PTEI_Axle_Torque_Command: 8 ECM_HS
 SG_ EngCommFlrRedPwrCm : 7|1@0+ (1,0) [0|1] "" Vector__XXX
 SG_ CmndAxlTrqARC : 34|2@0+ (1,0) [0|3] ""  EBCM_OBD_HS,EBCM_HS
 SG_ CmndAxlTrqRespTyp : 39|2@0+ (1,0) [0|3] "" Vector__XXX
 SG_ CmndAxlTrqImm : 6|15@0+ (2,-22534) [-22534|43000] "Nm" Vector__XXX
 SG_ AccPos : 63|8@0+ (0.392157,0) [0|100.000035] "%"  TCM_HS
 SG_ CmndAxlTrqPredct : 22|15@0+ (2,-22534) [-22534|43000] "Nm"  EBCM_OBD_HS,EBCM_HS
 SG_ CmndAxlTrqPredctProtVal : 46|15@0+ (1,0) [0|32767] ""  EBCM_OBD_HS,EBCM_HS

BO_ 979 PPEI_Engine_General_Status_6: 8 ECM_HS
 SG_ SpdLmtrSttngTypAct : 5|2@0+ (1,0) [0|3] ""  BCM_HS
 SG_ SetSpdLmtRchd : 3|2@0+ (1,0) [0|3] ""  BCM_HS
 SG_ PlatEngSpdCmdStPVal : 58|3@0+ (1,0) [0|7] "" Vector__XXX
 SG_ PlatEngSpdCmdStARC : 63|2@0+ (1,0) [0|3] "" Vector__XXX
 SG_ ElvtdIdlCstCrStVal : 22|2@0+ (1,0) [0|3] ""  BCM_HS
 SG_ ElvtdIdlCstStAvl : 39|1@0+ (1,0) [0|1] ""  BCM_HS
 SG_ PTABR_AccReq : 19|12@0- (0.01,0) [-20.48|20.47] "m/s^2"  EBCM_OBD_HS,EBCM_HS
 SG_ PTABR_PTBrkRqAct : 20|1@0+ (1,0) [0|1] ""  EBCM_OBD_HS,EBCM_HS
 SG_ PTAutoBrkReqPVal : 36|13@0+ (1,0) [0|8191] ""  EBCM_OBD_HS,EBCM_HS
 SG_ PTAutoBrkReqARC : 38|2@0+ (1,0) [0|3] ""  EBCM_OBD_HS,EBCM_HS
 SG_ BrkBstVacV : 7|1@0+ (1,0) [0|1] ""  EBCM_OBD_HS,EBCM_HS
 SG_ BrkBstVac : 15|8@0+ (0.5,0) [0|127.5] "kPa"  EBCM_OBD_HS,EBCM_HS
 SG_ EngManfldAirTempCrtdV : 6|1@0+ (1,0) [0|1] ""  BCM_HS
 SG_ PltfrmEngSpdCmmndSt : 61|3@0+ (1,0) [0|7] "" Vector__XXX
 SG_ EngManfldAirTempCrtd : 55|8@0+ (1,-40) [-40|215] "deg C"  BCM_HS

BO_ 647 PTEI_Transfer_Case_Supplemental: 5 ECM_HS
 SG_ CrnksftTqModRspMxCapV : 28|1@0+ (1,0) [0|1] ""  TCM_HS
 SG_ CrnksftTqModRspMxCap : 27|12@0+ (0.5,-848) [-848|1199.5] "Nm"  TCM_HS
 SG_ EngDetPndTrnCsRngShfV : 21|1@0+ (1,0) [0|1] ""  TCM_HS
 SG_ EngDetPndTrnCsRngShf : 20|2@0+ (1,0) [0|3] ""  TCM_HS
 SG_ CrpCstCrvCmd : 18|3@0+ (1,0) [0|7] ""  TCM_HS
 SG_ DrvMntnMdCmnd : 11|1@0+ (1,0) [0|1] "" Vector__XXX
 SG_ DrvHldMdCmnd : 12|1@0+ (1,0) [0|1] "" Vector__XXX
 SG_ DrPTGrdBrkDsbMdCmd : 22|1@0+ (1,0) [0|1] ""  TCM_HS
 SG_ DrvWntrMdCmd : 13|1@0+ (1,0) [0|1] ""  TCM_HS
 SG_ DrvTwHaulMdCmd : 14|1@0+ (1,0) [0|1] ""  TCM_HS
 SG_ DrvSprtMdCmd : 15|1@0+ (1,0) [0|1] ""  TCM_HS
 SG_ DrvEconMdCmd : 5|1@0+ (1,0) [0|1] ""  TCM_HS
 SG_ EngCntrlDtrmdTrfCRngV : 10|1@0+ (1,0) [0|1] ""  ICCM_OBD_HS,ICCM_HS,TCM_HS
 SG_ EngCntrlDtrmdTrfCRng : 9|2@0+ (1,0) [0|3] ""  ICCM_OBD_HS,ICCM_HS,TCM_HS
 SG_ EngCtrlUtldTrnCRgPVal : 1|2@0+ (1,0) [0|3] ""  EBCM_OBD_HS,EBCM_HS
 SG_ EngCntrlUtldTrnCsRng : 3|2@0+ (1,0) [0|3] ""  EBCM_OBD_HS,BCP_HS,EBCM_HS
 SG_ EngCntrlUtldTrnCsRgIn : 4|1@0+ (1,0) [0|1] ""  EBCM_OBD_HS,EBCM_HS
 SG_ EngCtrlUtldTrnCRgARC : 7|2@0+ (1,0) [0|3] ""  EBCM_OBD_HS,EBCM_HS

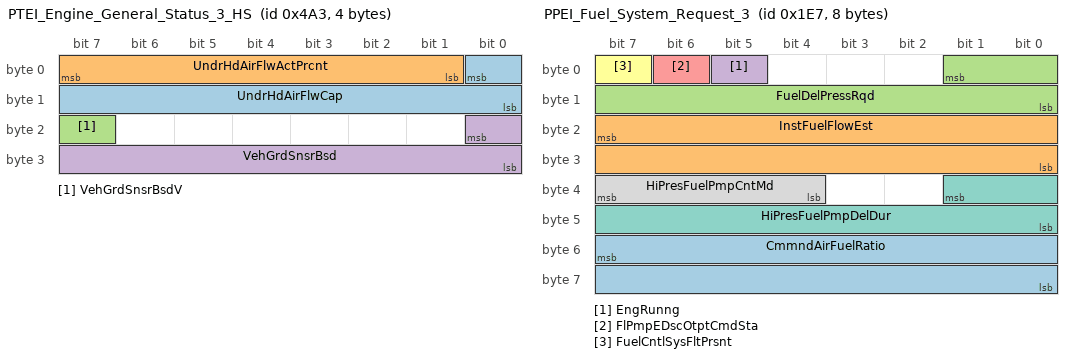
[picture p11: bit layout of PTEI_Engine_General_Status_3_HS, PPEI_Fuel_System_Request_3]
BO_ 1187 PTEI_Engine_General_Status_3_HS: 4 ECM_HS
 SG_ UndrHdAirFlwCap : 0|9@0+ (2,0) [0|1022] "m^3/min"  TCM_HS
 SG_ UndrHdAirFlwActPrcnt : 7|7@0+ (0.787402,0) [0|100.000054] "%"  TCM_HS
 SG_ VehGrdSnsrBsdV : 23|1@0+ (1,0) [0|1] ""  TCM_HS
 SG_ VehGrdSnsrBsd : 16|9@0- (0.1945,0) [-49.792|49.5975] "%"  TCM_HS

BO_ 487 PPEI_Fuel_System_Request_3: 8 ECM_HS
 SG_ CmmndAirFuelRatio : 55|16@0+ (0.000488281,0) [0|31.999495335] ""  ICCM_OBD_HS,ICCM_HS
 SG_ InstFuelFlowEst : 23|16@0+ (0.000976562,0) [0|63.99899067] "grams/s"  ICCM_OBD_HS,ICCM_HS
 SG_ FuelDelPressRqd : 1|10@0+ (1,0) [0|1023] "kPa"  ICCM_OBD_HS,ICCM_HS
 SG_ EngRunng : 5|1@0+ (1,0) [0|1] ""  ICCM_OBD_HS,ICCM_HS
 SG_ FlPmpEDscOtptCmdSta : 6|1@0+ (1,0) [0|1] ""  ICCM_OBD_HS,ICCM_HS
 SG_ FuelCntlSysFltPrsnt : 7|1@0+ (1,0) [0|1] ""  ICCM_OBD_HS,ICCM_HS
 SG_ HiPresFuelPmpDelDur : 33|10@0+ (1,0) [0|1023] "deg"  ICCM_OBD_HS,ICCM_HS
 SG_ HiPresFuelPmpCntMd : 39|4@0+ (1,0) [0|15] ""  ICCM_OBD_HS,ICCM_HS

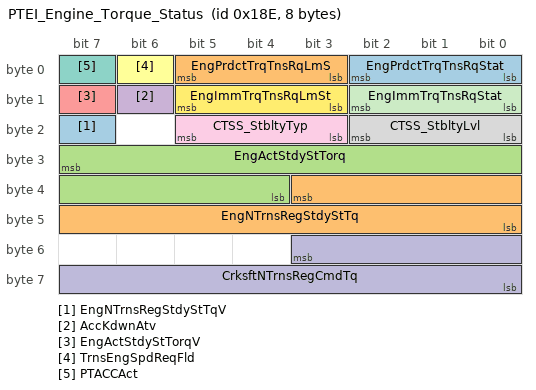
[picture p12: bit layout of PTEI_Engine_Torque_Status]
BO_ 398 PTEI_Engine_Torque_Status: 8 ECM_HS
 SG_ EngNTrnsRegStdyStTqV : 23|1@0+ (1,0) [0|1] ""  TCM_HS
 SG_ EngNTrnsRegStdyStTq : 35|12@0+ (0.5,-848) [-848|1199.5] "Nm"  TCM_HS
 SG_ EngActStdyStTorq : 31|12@0+ (0.5,-848) [-848|1199.5] "Nm"  TCCM_HS,TCM_HS
 SG_ AccKdwnAtv : 14|1@0+ (1,0) [0|1] ""  TCCM_HS,TCM_HS
 SG_ EngActStdyStTorqV : 15|1@0+ (1,0) [0|1] ""  TCCM_HS,TCM_HS
 SG_ TrnsEngSpdReqFld : 6|1@0+ (1,0) [0|1] ""  TCCM_HS,TCM_HS
 SG_ PTACCAct : 7|1@0+ (1,0) [0|1] ""  TCM_HS
 SG_ CTSS_StbltyLvl : 18|3@0+ (1,0) [0|7] ""  TCM_HS
 SG_ CTSS_StbltyTyp : 21|3@0+ (1,0) [0|7] ""  TCM_HS
 SG_ CrksftNTrnsRegCmdTq : 51|12@0+ (0.5,-848) [-848|1199.5] "Nm"  TCM_HS
 SG_ EngImmTrqTnsRqStat : 10|3@0+ (1,0) [0|7] ""  TCM_HS
 SG_ EngImmTrqTnsRqLmSt : 13|3@0+ (1,0) [0|7] ""  TCM_HS
 SG_ EngPrdctTrqTnsRqStat : 2|3@0+ (1,0) [0|7] ""  TCM_HS
 SG_ EngPrdctTrqTnsRqLmS : 5|3@0+ (1,0) [0|7] ""  TCM_HS

BO_TX_BU_ 565 : EBCM_OBD_HS,EBCM_HS;
BO_TX_BU_ 368 : CGM_HS,ONSTAR_HS;
BO_TX_BU_ 817 : ICCM_OBD_HS,ICCM_HS;
BO_TX_BU_ 564 : EBCM_OBD_HS,EBCM_HS;
BO_TX_BU_ 848 : ICCM_OBD_HS,ICCM_HS;
BO_TX_BU_ 1280 : EBCM_OBD_HS,EBCM_HS;
BO_TX_BU_ 562 : EBCM_OBD_HS,EBCM_HS;
BO_TX_BU_ 386 : EBCM_OBD_HS,EBCM_HS;
BO_TX_BU_ 532 : EBCM_OBD_HS,EBCM_HS;
BO_TX_BU_ 328 : EBCM_OBD_HS,EPS_HS,EBCM_HS;
BO_TX_BU_ 560 : EBCM_OBD_HS,EPB_HS,EBCM_HS;
BO_TX_BU_ 1282 : ICCM_OBD_HS,ICCM_HS;
CM_ BO_ 869 "Note that the ACC and EBCM algorithm will transmit this message at a 50 ms periodic rate and the ECU033 algorithm will transmit this message at a 40 ms periodic rate";
CM_ SG_ 532 BrkSysAutBrkFld "BrakeSystemAutomaticBrakingFailed";
CM_ SG_ 532 IntBrkAssPreFilReq "IntelligentBrakeAssistPreFillRequest";
CM_ BO_ 1282 "ALC will not (and cannot) be present on vehicles where the ICCM will transmit HS $502. Currently, this is only envisioned for high-performance vehicles.";
CM_ SG_ 979 BrkBstVac "0 kPA represents the sensor reading atmospheric pressure";
CM_ SG_ 398 EngNTrnsRegStdyStTqV "ETEI 3.1";
CM_ SG_ 398 EngNTrnsRegStdyStTq "ETEI 3.1";
CM_ SG_ 398 EngActStdyStTorq "ETEI 3.1";
CM_ SG_ 398 EngActStdyStTorqV "ETEI 3.1";
BA_DEF_ SG_  "VNSigSLHSSharedDiagnostic" ENUM  "No","Yes";
BA_DEF_ SG_  "VNSigSLHS_VNReq" ENUM  "No","Yes";
BA_DEF_ SG_  "GenSigSendOnInit" ENUM  "Not Initialized","Application","Handler";
BA_DEF_ SG_  "GenSigSendType" ENUM  "not used","not used","not used","not used","not used","not used","not used","NoSigSendType","not used","not used","OnAnyChange","OnChangeIfActive","OnDelta";
BA_DEF_ SG_  "GenSigDeltaValue" INT 0 0;
BA_DEF_ SG_  "VNSigAllNodes" ENUM  "No","Yes";
BA_DEF_ SG_  "SignalType" STRING ;
BA_DEF_ SG_  "PacketOrder" INT 0 65535;
BA_DEF_ SG_  "SignalLongName" STRING ;
BA_DEF_ SG_  "GenSigStartValue" INT 0 65535;
BA_DEF_ SG_  "TxSignalSendOnInit" ENUM  "Not Initialized","Application","Handler";
BA_DEF_ BO_  "GenMsgILSupport" ENUM  "No","Yes";
BA_DEF_ BO_  "AppGenMsgCycleTime" INT 0 0;
BA_DEF_ BO_  "TpApplType" STRING ;
BA_DEF_ BO_  "Prio" INT 0 7;
BA_DEF_ BO_  "MessageSubnet" ENUM  "LS","MS","HS","CE","PE","HV","FO","S1","HE","LE","HE2","vector_leerstring";
BA_DEF_ BO_  "DiagState" ENUM  "No","Yes";
BA_DEF_ BO_  "GenMsgIlSupport" ENUM  "No","Yes";
BA_DEF_ BO_  "GenMsgStartDelayTime" INT 0 100000;
BA_DEF_ BO_  "GenMsgDelayTime" INT 0 100000;
BA_DEF_ BO_  "GenMsgCycleTime" INT 0 100000;
BA_DEF_ BO_  "GenMsgSendType" ENUM  "cyclicX","spontanX","cyclicIfActiveX","spontanWithDelay","cyclicAndSpontanX","cyclicAndSpontanWithDelay","spontanWithRepitition","cyclicIfActiveAndSpontanWD";
BA_DEF_ BO_  "DiagResponse" ENUM  "No","Yes";
BA_DEF_ BO_  "DiagRequest" ENUM  "No","Yes";
BA_DEF_ BO_  "NmMessage" ENUM  "No","Yes";
BA_DEF_REL_ BU_SG_REL_  "GenSigSuprvResp" ENUM  "None","Notify App","Substitute Default";
BA_DEF_REL_ BU_SG_REL_  "GenSigSuprvRespSubValue" INT 0 65535;
BA_DEF_REL_ BU_SG_REL_  "GenSigRxStartValue" STRING ;
BA_DEF_REL_ BU_SG_REL_  "GenSigVDAFailResp" ENUM  "No","Yes";
BA_DEF_REL_ BU_SG_REL_  "GenSigVDAFailComment" STRING ;
BA_DEF_REL_ BU_SG_REL_  "GenSigVBitRespComment" STRING ;
BA_DEF_REL_ BU_SG_REL_  "GenSigVBitResp" ENUM  "No","Yes";
BA_DEF_REL_ BU_SG_REL_  "GenSigSuprvRespComment" STRING ;
BA_DEF_REL_ BU_SG_REL_  "GenSigTimeoutMsg" HEX 0 268435455;
BA_DEF_REL_ BU_SG_REL_  "GenSigTimeoutTime" INT 0 5000;
BA_DEF_DEF_  "VNSigSLHSSharedDiagnostic" "No";
BA_DEF_DEF_  "VNSigSLHS_VNReq" "No";
BA_DEF_DEF_  "GenSigSendOnInit" "Not Initialized";
BA_DEF_DEF_  "GenSigSendType" "NoSigSendType";
BA_DEF_DEF_  "GenSigDeltaValue" 0;
BA_DEF_DEF_  "VNSigAllNodes" "No";
BA_DEF_DEF_  "SignalType" "";
BA_DEF_DEF_  "PacketOrder" 0;
BA_DEF_DEF_  "SignalLongName" "";
BA_DEF_DEF_  "GenSigStartValue" 0;
BA_DEF_DEF_  "TxSignalSendOnInit" "Not Initialized";
BA_DEF_DEF_  "GenMsgILSupport" "Yes";
BA_DEF_DEF_  "AppGenMsgCycleTime" 0;
BA_DEF_DEF_  "TpApplType" "";
BA_DEF_DEF_  "Prio" 0;
BA_DEF_DEF_  "MessageSubnet" "LS";
BA_DEF_DEF_  "DiagState" "No";
BA_DEF_DEF_  "GenMsgIlSupport" "Yes";
BA_DEF_DEF_  "GenMsgStartDelayTime" 0;
BA_DEF_DEF_  "GenMsgDelayTime" 0;
BA_DEF_DEF_  "GenMsgCycleTime" 0;
BA_DEF_DEF_  "GenMsgSendType" "spontanX";
BA_DEF_DEF_  "DiagResponse" "No";
BA_DEF_DEF_  "DiagRequest" "No";
BA_DEF_DEF_  "NmMessage" "No";
BA_DEF_DEF_REL_ "GenSigSuprvResp" "None";
BA_DEF_DEF_REL_ "GenSigSuprvRespSubValue" 0;
BA_DEF_DEF_REL_ "GenSigRxStartValue" "";
BA_DEF_DEF_REL_ "GenSigVDAFailResp" "No";
BA_DEF_DEF_REL_ "GenSigVDAFailComment" "";
BA_DEF_DEF_REL_ "GenSigVBitRespComment" "";
BA_DEF_DEF_REL_ "GenSigVBitResp" "No";
BA_DEF_DEF_REL_ "GenSigSuprvRespComment" "";
BA_DEF_DEF_REL_ "GenSigTimeoutMsg" 0;
BA_DEF_DEF_REL_ "GenSigTimeoutTime" 0;
BA_ "MessageSubnet" BO_ 565 2;
BA_ "GenMsgCycleTime" BO_ 565 2000;
BA_ "GenMsgSendType" BO_ 565 0;
BA_ "MessageSubnet" BO_ 530 2;
BA_ "GenMsgCycleTime" BO_ 530 1000;
BA_ "GenMsgSendType" BO_ 530 0;
BA_ "MessageSubnet" BO_ 368 2;
BA_ "GenMsgCycleTime" BO_ 368 100;
BA_ "GenMsgSendType" BO_ 368 0;
BA_ "MessageSubnet" BO_ 882 2;
BA_ "GenMsgCycleTime" BO_ 882 40;
BA_ "GenMsgSendType" BO_ 882 0;
BA_ "MessageSubnet" BO_ 817 2;
BA_ "GenMsgCycleTime" BO_ 817 100;
BA_ "GenMsgSendType" BO_ 817 0;
BA_ "MessageSubnet" BO_ 853 2;
BA_ "GenMsgCycleTime" BO_ 853 100;
BA_ "GenMsgSendType" BO_ 853 0;
BA_ "AppGenMsgCycleTime" BO_ 869 40;
BA_ "MessageSubnet" BO_ 869 2;
BA_ "MessageSubnet" BO_ 564 2;
BA_ "GenMsgCycleTime" BO_ 564 100;
BA_ "GenMsgSendType" BO_ 564 0;
BA_ "MessageSubnet" BO_ 1296 2;
BA_ "GenMsgCycleTime" BO_ 1296 100;
BA_ "GenMsgSendType" BO_ 1296 0;
BA_ "MessageSubnet" BO_ 536 2;
BA_ "GenMsgCycleTime" BO_ 536 200;
BA_ "GenMsgSendType" BO_ 536 0;
BA_ "MessageSubnet" BO_ 848 2;
BA_ "GenMsgCycleTime" BO_ 848 50;
BA_ "GenMsgSendType" BO_ 848 0;
BA_ "MessageSubnet" BO_ 993 2;
BA_ "GenMsgCycleTime" BO_ 993 100;
BA_ "GenMsgSendType" BO_ 993 0;
BA_ "MessageSubnet" BO_ 1280 2;
BA_ "GenMsgCycleTime" BO_ 1280 1000;
BA_ "GenMsgSendType" BO_ 1280 0;
BA_ "MessageSubnet" BO_ 562 2;
BA_ "GenMsgCycleTime" BO_ 562 50;
BA_ "GenMsgSendType" BO_ 562 0;
BA_ "MessageSubnet" BO_ 893 2;
BA_ "GenMsgCycleTime" BO_ 893 100;
BA_ "GenMsgSendType" BO_ 893 0;
BA_ "MessageSubnet" BO_ 892 2;
BA_ "GenMsgCycleTime" BO_ 892 100;
BA_ "GenMsgSendType" BO_ 892 0;
BA_ "MessageSubnet" BO_ 386 2;
BA_ "GenMsgCycleTime" BO_ 386 100;
BA_ "GenMsgSendType" BO_ 386 0;
BA_ "MessageSubnet" BO_ 532 2;
BA_ "GenMsgCycleTime" BO_ 532 50;
BA_ "GenMsgSendType" BO_ 532 0;
BA_ "MessageSubnet" BO_ 890 2;
BA_ "GenMsgCycleTime" BO_ 890 100;
BA_ "GenMsgSendType" BO_ 890 0;
BA_ "MessageSubnet" BO_ 328 2;
BA_ "GenMsgDelayTime" BO_ 328 100;
BA_ "GenMsgCycleTime" BO_ 328 1000;
BA_ "GenMsgSendType" BO_ 328 0;
BA_ "MessageSubnet" BO_ 560 2;
BA_ "GenMsgCycleTime" BO_ 560 50;
BA_ "GenMsgSendType" BO_ 560 0;
BA_ "MessageSubnet" BO_ 1282 2;
BA_ "GenMsgCycleTime" BO_ 1282 500;
BA_ "GenMsgSendType" BO_ 1282 0;
BA_ "MessageSubnet" BO_ 2033 2;
BA_ "MessageSubnet" BO_ 1219 2;
BA_ "GenMsgCycleTime" BO_ 1219 1000;
BA_ "GenMsgSendType" BO_ 1219 0;
BA_ "MessageSubnet" BO_ 442 2;
BA_ "GenMsgCycleTime" BO_ 442 25;
BA_ "GenMsgSendType" BO_ 442 0;
BA_ "MessageSubnet" BO_ 988 2;
BA_ "GenMsgCycleTime" BO_ 988 100;
BA_ "GenMsgSendType" BO_ 988 0;
BA_ "MessageSubnet" BO_ 500 2;
BA_ "GenMsgCycleTime" BO_ 500 25;
BA_ "GenMsgSendType" BO_ 500 0;
BA_ "MessageSubnet" BO_ 1417 2;
BA_ "GenMsgCycleTime" BO_ 1417 500;
BA_ "GenMsgSendType" BO_ 1417 0;
BA_ "MessageSubnet" BO_ 170 2;
BA_ "GenMsgCycleTime" BO_ 170 12;
BA_ "GenMsgSendType" BO_ 170 0;
BA_ "MessageSubnet" BO_ 979 2;
BA_ "GenMsgCycleTime" BO_ 979 100;
BA_ "GenMsgSendType" BO_ 979 0;
BA_ "MessageSubnet" BO_ 647 2;
BA_ "GenMsgCycleTime" BO_ 647 25;
BA_ "GenMsgSendType" BO_ 647 0;
BA_ "MessageSubnet" BO_ 1187 2;
BA_ "GenMsgCycleTime" BO_ 1187 1000;
BA_ "GenMsgSendType" BO_ 1187 0;
BA_ "MessageSubnet" BO_ 487 2;
BA_ "GenMsgCycleTime" BO_ 487 12;
BA_ "GenMsgSendType" BO_ 487 0;
BA_ "MessageSubnet" BO_ 398 2;
BA_ "GenMsgCycleTime" BO_ 398 12;
BA_ "GenMsgSendType" BO_ 398 0;
BA_ "GenSigSendOnInit" SG_ 565 PerfMdMainMenuType 2;
BA_ "GenSigSendType" SG_ 565 PerfMdMainMenuType 10;
BA_ "VNSigAllNodes" SG_ 565 PerfMdMainMenuType 1;
BA_ "SignalType" SG_ 565 PerfMdMainMenuType "ENM";
BA_ "SignalLongName" SG_ 565 PerfMdMainMenuType "Performance Mode Main Menu Type";
BA_ "VNSigAllNodes" SG_ 565 PSPMCA_PsngStPrfMd6Avl 1;
BA_ "SignalType" SG_ 565 PSPMCA_PsngStPrfMd6Avl "BLN";
BA_ "PacketOrder" SG_ 565 PSPMCA_PsngStPrfMd6Avl 6;
BA_ "SignalLongName" SG_ 565 PSPMCA_PsngStPrfMd6Avl "Passenger Seat Performance Mode Customization Available : Passenger Seat Performance Mode 6 Available";
BA_ "VNSigAllNodes" SG_ 565 PSPMCA_PsngStPrfMd5Avl 1;
BA_ "SignalType" SG_ 565 PSPMCA_PsngStPrfMd5Avl "BLN";
BA_ "PacketOrder" SG_ 565 PSPMCA_PsngStPrfMd5Avl 5;
BA_ "SignalLongName" SG_ 565 PSPMCA_PsngStPrfMd5Avl "Passenger Seat Performance Mode Customization Available : Passenger Seat Performance Mode 5 Available";
BA_ "VNSigAllNodes" SG_ 565 PSPMCA_PsngStPrfMd4Avl 1;
BA_ "SignalType" SG_ 565 PSPMCA_PsngStPrfMd4Avl "BLN";
BA_ "PacketOrder" SG_ 565 PSPMCA_PsngStPrfMd4Avl 4;
BA_ "SignalLongName" SG_ 565 PSPMCA_PsngStPrfMd4Avl "Passenger Seat Performance Mode Customization Available : Passenger Seat Performance Mode 4 Available";
BA_ "VNSigAllNodes" SG_ 565 PSPMCA_PsngStPrfMd3Avl 1;
BA_ "SignalType" SG_ 565 PSPMCA_PsngStPrfMd3Avl "BLN";
BA_ "PacketOrder" SG_ 565 PSPMCA_PsngStPrfMd3Avl 3;
BA_ "SignalLongName" SG_ 565 PSPMCA_PsngStPrfMd3Avl "Passenger Seat Performance Mode Customization Available : Passenger Seat Performance Mode 3 Available";
BA_ "VNSigAllNodes" SG_ 565 PSPMCA_PsngStPrfMd2Avl 1;
BA_ "SignalType" SG_ 565 PSPMCA_PsngStPrfMd2Avl "BLN";
BA_ "PacketOrder" SG_ 565 PSPMCA_PsngStPrfMd2Avl 2;
BA_ "SignalLongName" SG_ 565 PSPMCA_PsngStPrfMd2Avl "Passenger Seat Performance Mode Customization Available : Passenger Seat Performance Mode 2 Available";
BA_ "VNSigAllNodes" SG_ 565 PSPMCA_PsngStPrfMd1Avl 1;
BA_ "SignalType" SG_ 565 PSPMCA_PsngStPrfMd1Avl "BLN";
BA_ "PacketOrder" SG_ 565 PSPMCA_PsngStPrfMd1Avl 1;
BA_ "SignalLongName" SG_ 565 PSPMCA_PsngStPrfMd1Avl "Passenger Seat Performance Mode Customization Available : Passenger Seat Performance Mode 1 Available";
BA_ "VNSigAllNodes" SG_ 565 DSPMCA_DrvStyPrfMd7Avl 1;
BA_ "SignalType" SG_ 565 DSPMCA_DrvStyPrfMd7Avl "BLN";
BA_ "PacketOrder" SG_ 565 DSPMCA_DrvStyPrfMd7Avl 7;
BA_ "SignalLongName" SG_ 565 DSPMCA_DrvStyPrfMd7Avl "Driving Style Performance Mode Customization Available : Driving Style Performance Mode 7 Available";
BA_ "VNSigAllNodes" SG_ 565 DSPMCA_DrvStyPrfMd6Avl 1;
BA_ "SignalType" SG_ 565 DSPMCA_DrvStyPrfMd6Avl "BLN";
BA_ "PacketOrder" SG_ 565 DSPMCA_DrvStyPrfMd6Avl 6;
BA_ "SignalLongName" SG_ 565 DSPMCA_DrvStyPrfMd6Avl "Driving Style Performance Mode Customization Available : Driving Style Performance Mode 6 Available";
BA_ "VNSigAllNodes" SG_ 565 DSPMCA_DrvStyPrfMd5Avl 1;
BA_ "SignalType" SG_ 565 DSPMCA_DrvStyPrfMd5Avl "BLN";
BA_ "PacketOrder" SG_ 565 DSPMCA_DrvStyPrfMd5Avl 5;
BA_ "SignalLongName" SG_ 565 DSPMCA_DrvStyPrfMd5Avl "Driving Style Performance Mode Customization Available : Driving Style Performance Mode 5 Available";
BA_ "VNSigAllNodes" SG_ 565 DSPMCA_DrvStyPrfMd4Avl 1;
BA_ "SignalType" SG_ 565 DSPMCA_DrvStyPrfMd4Avl "BLN";
BA_ "PacketOrder" SG_ 565 DSPMCA_DrvStyPrfMd4Avl 4;
BA_ "SignalLongName" SG_ 565 DSPMCA_DrvStyPrfMd4Avl "Driving Style Performance Mode Customization Available : Driving Style Performance Mode 4 Available";
BA_ "VNSigAllNodes" SG_ 565 DSPMCA_DrvStyPrfMd3Avl 1;
BA_ "SignalType" SG_ 565 DSPMCA_DrvStyPrfMd3Avl "BLN";
BA_ "PacketOrder" SG_ 565 DSPMCA_DrvStyPrfMd3Avl 3;
BA_ "SignalLongName" SG_ 565 DSPMCA_DrvStyPrfMd3Avl "Driving Style Performance Mode Customization Available : Driving Style Performance Mode 3 Available";
BA_ "VNSigAllNodes" SG_ 565 DSPMCA_DrvStyPrfMd2Avl 1;
BA_ "SignalType" SG_ 565 DSPMCA_DrvStyPrfMd2Avl "BLN";
BA_ "PacketOrder" SG_ 565 DSPMCA_DrvStyPrfMd2Avl 2;
BA_ "SignalLongName" SG_ 565 DSPMCA_DrvStyPrfMd2Avl "Driving Style Performance Mode Customization Available : Driving Style Performance Mode 2 Available";
BA_ "VNSigAllNodes" SG_ 565 DSPMCA_DrvStyPrfMd1Avl 1;
BA_ "SignalType" SG_ 565 DSPMCA_DrvStyPrfMd1Avl "BLN";
BA_ "PacketOrder" SG_ 565 DSPMCA_DrvStyPrfMd1Avl 1;
BA_ "SignalLongName" SG_ 565 DSPMCA_DrvStyPrfMd1Avl "Driving Style Performance Mode Customization Available : Driving Style Performance Mode 1 Available";
BA_ "VNSigAllNodes" SG_ 565 DSPMCA_DrvrStPrfMd6Avl 1;
BA_ "SignalType" SG_ 565 DSPMCA_DrvrStPrfMd6Avl "BLN";
BA_ "PacketOrder" SG_ 565 DSPMCA_DrvrStPrfMd6Avl 6;
BA_ "SignalLongName" SG_ 565 DSPMCA_DrvrStPrfMd6Avl "Driver Seat Performance Mode Customization Available : Driver Seat Performance Mode 6 Available";
BA_ "VNSigAllNodes" SG_ 565 DSPMCA_DrvrStPrfMd5Avl 1;
BA_ "SignalType" SG_ 565 DSPMCA_DrvrStPrfMd5Avl "BLN";
BA_ "PacketOrder" SG_ 565 DSPMCA_DrvrStPrfMd5Avl 5;
BA_ "SignalLongName" SG_ 565 DSPMCA_DrvrStPrfMd5Avl "Driver Seat Performance Mode Customization Available : Driver Seat Performance Mode 5 Available";
BA_ "VNSigAllNodes" SG_ 565 DSPMCA_DrvrStPrfMd4Avl 1;
BA_ "SignalType" SG_ 565 DSPMCA_DrvrStPrfMd4Avl "BLN";
BA_ "PacketOrder" SG_ 565 DSPMCA_DrvrStPrfMd4Avl 4;
BA_ "SignalLongName" SG_ 565 DSPMCA_DrvrStPrfMd4Avl "Driver Seat Performance Mode Customization Available : Driver Seat Performance Mode 4 Available";
BA_ "VNSigAllNodes" SG_ 565 DSPMCA_DrvrStPrfMd3Avl 1;
BA_ "SignalType" SG_ 565 DSPMCA_DrvrStPrfMd3Avl "BLN";
BA_ "PacketOrder" SG_ 565 DSPMCA_DrvrStPrfMd3Avl 3;
BA_ "SignalLongName" SG_ 565 DSPMCA_DrvrStPrfMd3Avl "Driver Seat Performance Mode Customization Available : Driver Seat Performance Mode 3 Available";
BA_ "VNSigAllNodes" SG_ 565 DSPMCA_DrvrStPrfMd2Avl 1;
BA_ "SignalType" SG_ 565 DSPMCA_DrvrStPrfMd2Avl "BLN";
BA_ "PacketOrder" SG_ 565 DSPMCA_DrvrStPrfMd2Avl 2;
BA_ "SignalLongName" SG_ 565 DSPMCA_DrvrStPrfMd2Avl "Driver Seat Performance Mode Customization Available : Driver Seat Performance Mode 2 Available";
BA_ "VNSigAllNodes" SG_ 565 DSPMCA_DrvrStPrfMd1Avl 1;
BA_ "SignalType" SG_ 565 DSPMCA_DrvrStPrfMd1Avl "BLN";
BA_ "PacketOrder" SG_ 565 DSPMCA_DrvrStPrfMd1Avl 1;
BA_ "SignalLongName" SG_ 565 DSPMCA_DrvrStPrfMd1Avl "Driver Seat Performance Mode Customization Available : Driver Seat Performance Mode 1 Available";
BA_ "VNSigAllNodes" SG_ 565 ACCPMCA_ACCPrfMd6Avl 1;
BA_ "SignalType" SG_ 565 ACCPMCA_ACCPrfMd6Avl "BLN";
BA_ "PacketOrder" SG_ 565 ACCPMCA_ACCPrfMd6Avl 6;
BA_ "SignalLongName" SG_ 565 ACCPMCA_ACCPrfMd6Avl "Adaptive Cruise Control Performance Mode Customization Available : Adaptive Cruise Control Performance Mode 6 Available";
BA_ "VNSigAllNodes" SG_ 565 ACCPMCA_ACCPrfMd5Avl 1;
BA_ "SignalType" SG_ 565 ACCPMCA_ACCPrfMd5Avl "BLN";
BA_ "PacketOrder" SG_ 565 ACCPMCA_ACCPrfMd5Avl 5;
BA_ "SignalLongName" SG_ 565 ACCPMCA_ACCPrfMd5Avl "Adaptive Cruise Control Performance Mode Customization Available : Adaptive Cruise Control Performance Mode 5 Available";
BA_ "VNSigAllNodes" SG_ 565 ACCPMCA_ACCPrfMd4Avl 1;
BA_ "SignalType" SG_ 565 ACCPMCA_ACCPrfMd4Avl "BLN";
BA_ "PacketOrder" SG_ 565 ACCPMCA_ACCPrfMd4Avl 4;
BA_ "SignalLongName" SG_ 565 ACCPMCA_ACCPrfMd4Avl "Adaptive Cruise Control Performance Mode Customization Available : Adaptive Cruise Control Performance Mode 4 Available";
BA_ "VNSigAllNodes" SG_ 565 ACCPMCA_ACCPrfMd3Avl 1;
BA_ "SignalType" SG_ 565 ACCPMCA_ACCPrfMd3Avl "BLN";
BA_ "PacketOrder" SG_ 565 ACCPMCA_ACCPrfMd3Avl 3;
BA_ "SignalLongName" SG_ 565 ACCPMCA_ACCPrfMd3Avl "Adaptive Cruise Control Performance Mode Customization Available : Adaptive Cruise Control Performance Mode 3 Available";
BA_ "VNSigAllNodes" SG_ 565 ACCPMCA_ACCPrfMd2Avl 1;
BA_ "SignalType" SG_ 565 ACCPMCA_ACCPrfMd2Avl "BLN";
BA_ "PacketOrder" SG_ 565 ACCPMCA_ACCPrfMd2Avl 2;
BA_ "SignalLongName" SG_ 565 ACCPMCA_ACCPrfMd2Avl "Adaptive Cruise Control Performance Mode Customization Available : Adaptive Cruise Control Performance Mode 2 Available";
BA_ "VNSigAllNodes" SG_ 565 ACCPMCA_ACCPrfMd1Avl 1;
BA_ "SignalType" SG_ 565 ACCPMCA_ACCPrfMd1Avl "BLN";
BA_ "PacketOrder" SG_ 565 ACCPMCA_ACCPrfMd1Avl 1;
BA_ "SignalLongName" SG_ 565 ACCPMCA_ACCPrfMd1Avl "Adaptive Cruise Control Performance Mode Customization Available : Adaptive Cruise Control Performance Mode 1 Available";
BA_ "GenSigSendType" SG_ 530 RstVTDTmprDtctd 10;
BA_ "VNSigAllNodes" SG_ 530 RstVTDTmprDtctd 1;
BA_ "SignalType" SG_ 530 RstVTDTmprDtctd "ENM";
BA_ "SignalLongName" SG_ 530 RstVTDTmprDtctd "Reset Vehicle Theft Deterrent Tamper Detected";
BA_ "GenSigSendType" SG_ 530 RstIllDrIdDevDtctd 10;
BA_ "VNSigAllNodes" SG_ 530 RstIllDrIdDevDtctd 1;
BA_ "SignalType" SG_ 530 RstIllDrIdDevDtctd "ENM";
BA_ "SignalLongName" SG_ 530 RstIllDrIdDevDtctd "Reset Illegitimate Driver Identification Device Detected";
BA_ "GenSigSendType" SG_ 530 RstDrIdDevLrnd 10;
BA_ "VNSigAllNodes" SG_ 530 RstDrIdDevLrnd 1;
BA_ "SignalType" SG_ 530 RstDrIdDevLrnd "ENM";
BA_ "SignalLongName" SG_ 530 RstDrIdDevLrnd "Reset Driver Identification Device Learned";
BA_ "VNSigAllNodes" SG_ 368 EnvIdRspSt5 1;
BA_ "SignalType" SG_ 368 EnvIdRspSt5 "ENM";
BA_ "SignalLongName" SG_ 368 EnvIdRspSt5 "Environment Identification Response Status 5";
BA_ "VNSigAllNodes" SG_ 368 EnvIdRsp5 1;
BA_ "SignalType" SG_ 368 EnvIdRsp5 "UNM";
BA_ "SignalLongName" SG_ 368 EnvIdRsp5 "Environment Identification Response 5";
BA_ "VNSigAllNodes" SG_ 882 RghtHndLftHndTrffc 1;
BA_ "SignalType" SG_ 882 RghtHndLftHndTrffc "ENM";
BA_ "SignalLongName" SG_ 882 RghtHndLftHndTrffc "Righthand Lefthand Traffic";
BA_ "VNSigAllNodes" SG_ 882 RghtHdlmpXnPwr 1;
BA_ "SignalType" SG_ 882 RghtHdlmpXnPwr "UNM";
BA_ "SignalLongName" SG_ 882 RghtHdlmpXnPwr "Right Headlamp Xenon Power";
BA_ "VNSigAllNodes" SG_ 882 RghtHdlmpSwvlAngl 1;
BA_ "SignalType" SG_ 882 RghtHdlmpSwvlAngl "SNM";
BA_ "SignalLongName" SG_ 882 RghtHdlmpSwvlAngl "Right Headlamp Swivel Angle";
BA_ "VNSigAllNodes" SG_ 882 RghtHdlmpStcBnd 1;
BA_ "SignalType" SG_ 882 RghtHdlmpStcBnd "UNM";
BA_ "SignalLongName" SG_ 882 RghtHdlmpStcBnd "Right Headlamp Static Bend";
BA_ "VNSigAllNodes" SG_ 882 RghtHdlmpLvllngPstn 1;
BA_ "SignalType" SG_ 882 RghtHdlmpLvllngPstn "SNM";
BA_ "SignalLongName" SG_ 882 RghtHdlmpLvllngPstn "Right Headlamp Levelling Position";
BA_ "VNSigAllNodes" SG_ 882 RghtHdlmpDrmPstn 1;
BA_ "SignalType" SG_ 882 RghtHdlmpDrmPstn "UNM";
BA_ "SignalLongName" SG_ 882 RghtHdlmpDrmPstn "Right Headlamp Drum Position";
BA_ "VNSigAllNodes" SG_ 882 LftHdlmpXnPwr 1;
BA_ "SignalType" SG_ 882 LftHdlmpXnPwr "UNM";
BA_ "SignalLongName" SG_ 882 LftHdlmpXnPwr "Left Headlamp Xenon Power";
BA_ "VNSigAllNodes" SG_ 882 LftHdlmpSwvlAngl 1;
BA_ "SignalType" SG_ 882 LftHdlmpSwvlAngl "SNM";
BA_ "SignalLongName" SG_ 882 LftHdlmpSwvlAngl "Left Headlamp Swivel Angle";
BA_ "VNSigAllNodes" SG_ 882 LftHdlmpStcBnd 1;
BA_ "SignalType" SG_ 882 LftHdlmpStcBnd "UNM";
BA_ "SignalLongName" SG_ 882 LftHdlmpStcBnd "Left Headlamp Static Bend";
BA_ "VNSigAllNodes" SG_ 882 LftHdlmpLvllngPstn 1;
BA_ "SignalType" SG_ 882 LftHdlmpLvllngPstn "SNM";
BA_ "SignalLongName" SG_ 882 LftHdlmpLvllngPstn "Left Headlamp Levelling Position";
BA_ "VNSigAllNodes" SG_ 882 LftHdlmpDrmPstn 1;
BA_ "SignalType" SG_ 882 LftHdlmpDrmPstn "UNM";
BA_ "SignalLongName" SG_ 882 LftHdlmpDrmPstn "Left Headlamp Drum Position";
BA_ "VNSigAllNodes" SG_ 882 HdlmpLvllngRrSnsrPstn 1;
BA_ "SignalType" SG_ 882 HdlmpLvllngRrSnsrPstn "SNM";
BA_ "SignalLongName" SG_ 882 HdlmpLvllngRrSnsrPstn "Headlamp Levelling Rear Sensor Position";
BA_ "VNSigAllNodes" SG_ 882 HdlmpLvllngFrntSnsrPstn 1;
BA_ "SignalType" SG_ 882 HdlmpLvllngFrntSnsrPstn "SNM";
BA_ "SignalLongName" SG_ 882 HdlmpLvllngFrntSnsrPstn "Headlamp Levelling Front Sensor Position";
BA_ "VNSigAllNodes" SG_ 882 AdvFrntLghtSysHiBmIO 1;
BA_ "SignalType" SG_ 882 AdvFrntLghtSysHiBmIO "BLN";
BA_ "SignalLongName" SG_ 882 AdvFrntLghtSysHiBmIO "Advanced Front Lighting System High Beam Indication On";
BA_ "VNSigAllNodes" SG_ 817 RrAxlELSDCplLwResV 1;
BA_ "SignalType" SG_ 817 RrAxlELSDCplLwResV "ENM";
BA_ "SignalLongName" SG_ 817 RrAxlELSDCplLwResV "Rear Axle Electronic Limited Slip Differential Coupling Low Resolution Validity";
BA_ "VNSigAllNodes" SG_ 817 RrAxlELSDCplLwRes 1;
BA_ "SignalType" SG_ 817 RrAxlELSDCplLwRes "UNM";
BA_ "SignalLongName" SG_ 817 RrAxlELSDCplLwRes "Rear Axle Electronic Limited Slip Differential Coupling Low Resolution";
BA_ "VNSigAllNodes" SG_ 817 RrDrvlnSysVehTpSpdLmVal 1;
BA_ "SignalType" SG_ 817 RrDrvlnSysVehTpSpdLmVal "UNM";
BA_ "SignalLongName" SG_ 817 RrDrvlnSysVehTpSpdLmVal "Rear Driveline System Vehicle Top Speed Limit Value";
BA_ "VNSigAllNodes" SG_ 817 RrAxlTmpInhIO 1;
BA_ "SignalType" SG_ 817 RrAxlTmpInhIO "BLN";
BA_ "SignalLongName" SG_ 817 RrAxlTmpInhIO "Rear Axle Temporary Inhibit Indication On";
BA_ "VNSigAllNodes" SG_ 817 RrAxlMalfIO 1;
BA_ "SignalType" SG_ 817 RrAxlMalfIO "BLN";
BA_ "SignalLongName" SG_ 817 RrAxlMalfIO "Rear Axle Malfunction Indication On";
BA_ "VNSigAllNodes" SG_ 853 SrvPedtrnProtSysIO 1;
BA_ "SignalType" SG_ 853 SrvPedtrnProtSysIO "BLN";
BA_ "SignalLongName" SG_ 853 SrvPedtrnProtSysIO "Service Pedestrian Protection System Indication On";
BA_ "VNSigAllNodes" SG_ 853 PedtrnProtSysDisbld 1;
BA_ "SignalType" SG_ 853 PedtrnProtSysDisbld "BLN";
BA_ "SignalLongName" SG_ 853 PedtrnProtSysDisbld "Pedestrian Protection System Disabled";
BA_ "VNSigAllNodes" SG_ 853 PedtrnProtSysDpl 1;
BA_ "SignalType" SG_ 853 PedtrnProtSysDpl "BLN";
BA_ "SignalLongName" SG_ 853 PedtrnProtSysDpl "Pedestrian Protection System Deployed";
BA_ "GenSigSendType" SG_ 869 FwdClnMtgnBrkReqAct 10;
BA_ "VNSigAllNodes" SG_ 869 FwdClnMtgnBrkReqAct 1;
BA_ "SignalType" SG_ 869 FwdClnMtgnBrkReqAct "BLN";
BA_ "SignalLongName" SG_ 869 FwdClnMtgnBrkReqAct "Forward Collision Mitigation Braking Request Active";
BA_ "GenSigSendOnInit" SG_ 869 FCACustStngAvlbl 2;
BA_ "GenSigSendType" SG_ 869 FCACustStngAvlbl 10;
BA_ "VNSigAllNodes" SG_ 869 FCACustStngAvlbl 1;
BA_ "SignalType" SG_ 869 FCACustStngAvlbl "BLN";
BA_ "SignalLongName" SG_ 869 FCACustStngAvlbl "Forward Collision Alert Customization Setting Available";
BA_ "GenSigSendOnInit" SG_ 869 FwdClnAlrtCustCrntSetngVal 2;
BA_ "GenSigSendType" SG_ 869 FwdClnAlrtCustCrntSetngVal 10;
BA_ "VNSigAllNodes" SG_ 869 FwdClnAlrtCustCrntSetngVal 1;
BA_ "SignalType" SG_ 869 FwdClnAlrtCustCrntSetngVal "ENM";
BA_ "SignalLongName" SG_ 869 FwdClnAlrtCustCrntSetngVal "Forward Collision Alert Customization Current Setting Value";
BA_ "VNSigAllNodes" SG_ 869 GNCustSetngAvlbl 1;
BA_ "SignalType" SG_ 869 GNCustSetngAvlbl "BLN";
BA_ "SignalLongName" SG_ 869 GNCustSetngAvlbl "Go Notifier Customization Setting Available";
BA_ "VNSigAllNodes" SG_ 869 CPSUnblIO 1;
BA_ "SignalType" SG_ 869 CPSUnblIO "BLN";
BA_ "SignalLongName" SG_ 869 CPSUnblIO "Collision Preparation System Unavailable Indication On";
BA_ "VNSigAllNodes" SG_ 869 ColPrSysStngAvl 1;
BA_ "SignalType" SG_ 869 ColPrSysStngAvl "BLN";
BA_ "SignalLongName" SG_ 869 ColPrSysStngAvl "Collision Preparation System Setting Available";
BA_ "VNSigAllNodes" SG_ 869 CPSOffIO 1;
BA_ "SignalType" SG_ 869 CPSOffIO "BLN";
BA_ "SignalLongName" SG_ 869 CPSOffIO "Collision Preparation System Off Indication On";
BA_ "VNSigAllNodes" SG_ 869 CPSFldIO 1;
BA_ "SignalType" SG_ 869 CPSFldIO "BLN";
BA_ "SignalLongName" SG_ 869 CPSFldIO "Collision Preparation System Failed Indication On";
BA_ "VNSigAllNodes" SG_ 869 ColPrSysCrntStng 1;
BA_ "SignalType" SG_ 869 ColPrSysCrntStng "ENM";
BA_ "SignalLongName" SG_ 869 ColPrSysCrntStng "Collision Preparation System Current Setting Value";
BA_ "VNSigAllNodes" SG_ 869 CPSAlrtOnlIO 1;
BA_ "SignalType" SG_ 869 CPSAlrtOnlIO "BLN";
BA_ "SignalLongName" SG_ 869 CPSAlrtOnlIO "Collision Preparation System Alert Only Indication On";
BA_ "VNSigAllNodes" SG_ 869 GNCustCrntStngVal 1;
BA_ "SignalType" SG_ 869 GNCustCrntStngVal "ENM";
BA_ "SignalLongName" SG_ 869 GNCustCrntStngVal "Go Notifier Customization Current Setting Value";
BA_ "VNSigAllNodes" SG_ 564 AdptDrvrSeatStng 1;
BA_ "SignalType" SG_ 564 AdptDrvrSeatStng "ENM";
BA_ "SignalLongName" SG_ 564 AdptDrvrSeatStng "Adaptive Driver Seat Setting";
BA_ "VNSigAllNodes" SG_ 564 AdptPsngrSeatStng 1;
BA_ "SignalType" SG_ 564 AdptPsngrSeatStng "ENM";
BA_ "SignalLongName" SG_ 564 AdptPsngrSeatStng "Adaptive Passenger Seat Setting";
BA_ "GenSigSendType" SG_ 564 TnDrvTrCtrlOffUnbIO 10;
BA_ "VNSigAllNodes" SG_ 564 TnDrvTrCtrlOffUnbIO 1;
BA_ "SignalType" SG_ 564 TnDrvTrCtrlOffUnbIO "BLN";
BA_ "SignalLongName" SG_ 564 TnDrvTrCtrlOffUnbIO "Teen Driver Traction Control Off Unavailable Indication On";
BA_ "GenSigSendType" SG_ 564 TnDrvStblCtrlOffUnbIO 10;
BA_ "VNSigAllNodes" SG_ 564 TnDrvStblCtrlOffUnbIO 1;
BA_ "SignalType" SG_ 564 TnDrvStblCtrlOffUnbIO "BLN";
BA_ "SignalLongName" SG_ 564 TnDrvStblCtrlOffUnbIO "Teen Driver Stability Control Off Unavailable Indication On";
BA_ "VNSigAllNodes" SG_ 564 VehRollAngleV 1;
BA_ "SignalType" SG_ 564 VehRollAngleV "ENM";
BA_ "SignalLongName" SG_ 564 VehRollAngleV "Vehicle Roll Angle Validity";
BA_ "VNSigAllNodes" SG_ 564 VehRollAngle 1;
BA_ "SignalType" SG_ 564 VehRollAngle "UNM";
BA_ "SignalLongName" SG_ 564 VehRollAngle "Vehicle Roll Angle";
BA_ "VNSigAllNodes" SG_ 564 VehPitchAngleV 1;
BA_ "SignalType" SG_ 564 VehPitchAngleV "ENM";
BA_ "SignalLongName" SG_ 564 VehPitchAngleV "Vehicle Pitch Angle Validity";
BA_ "VNSigAllNodes" SG_ 564 VehPitchAngle 1;
BA_ "SignalType" SG_ 564 VehPitchAngle "UNM";
BA_ "SignalLongName" SG_ 564 VehPitchAngle "Vehicle Pitch Angle";
BA_ "VNSigAllNodes" SG_ 564 RdWhlAngV 1;
BA_ "SignalType" SG_ 564 RdWhlAngV "ENM";
BA_ "SignalLongName" SG_ 564 RdWhlAngV "Road Wheel Angle Validity";
BA_ "VNSigAllNodes" SG_ 564 RdWhlAng 1;
BA_ "SignalType" SG_ 564 RdWhlAng "UNM";
BA_ "SignalLongName" SG_ 564 RdWhlAng "Road Wheel Angle";
BA_ "VNSigAllNodes" SG_ 564 TrlrStabAstActIO 1;
BA_ "SignalType" SG_ 564 TrlrStabAstActIO "BLN";
BA_ "SignalLongName" SG_ 564 TrlrStabAstActIO "Trailer Stability Assist Active Indication On";
BA_ "VNSigAllNodes" SG_ 564 PerfTrcCrnExStngVal 1;
BA_ "SignalType" SG_ 564 PerfTrcCrnExStngVal "ENM";
BA_ "SignalLongName" SG_ 564 PerfTrcCrnExStngVal "Performance Traction Corner Exit Setting Value";
BA_ "VNSigAllNodes" SG_ 1296 ACCAutoSetSpdStat 1;
BA_ "SignalType" SG_ 1296 ACCAutoSetSpdStat "ENM";
BA_ "SignalLongName" SG_ 1296 ACCAutoSetSpdStat "Adaptive Cruise Control Auto Set Speed Status";
BA_ "VNSigAllNodes" SG_ 1296 FwdClnAlrtOffIO 1;
BA_ "SignalType" SG_ 1296 FwdClnAlrtOffIO "BLN";
BA_ "SignalLongName" SG_ 1296 FwdClnAlrtOffIO "Forward Collision Alert Off Indication On";
BA_ "GenSigSendOnInit" SG_ 1296 VADIR_IndLvl 1;
BA_ "GenSigSendType" SG_ 1296 VADIR_IndLvl 10;
BA_ "VNSigAllNodes" SG_ 1296 VADIR_IndLvl 1;
BA_ "SignalType" SG_ 1296 VADIR_IndLvl "ENM";
BA_ "PacketOrder" SG_ 1296 VADIR_IndLvl 1;
BA_ "SignalLongName" SG_ 1296 VADIR_IndLvl "Vehicle Ahead Distance Indication Request : Indication Level";
BA_ "GenSigSendOnInit" SG_ 1296 VADIR_FlwTme 1;
BA_ "GenSigSendType" SG_ 1296 VADIR_FlwTme 12;
BA_ "GenSigDeltaValue" SG_ 1296 VADIR_FlwTme 1;
BA_ "VNSigAllNodes" SG_ 1296 VADIR_FlwTme 1;
BA_ "SignalType" SG_ 1296 VADIR_FlwTme "UNM";
BA_ "PacketOrder" SG_ 1296 VADIR_FlwTme 2;
BA_ "SignalLongName" SG_ 1296 VADIR_FlwTme "Vehicle Ahead Distance Indication Request : Following Time";
BA_ "GenSigSendOnInit" SG_ 1296 VADIR_FlwDst 1;
BA_ "GenSigSendType" SG_ 1296 VADIR_FlwDst 12;
BA_ "GenSigDeltaValue" SG_ 1296 VADIR_FlwDst 1;
BA_ "VNSigAllNodes" SG_ 1296 VADIR_FlwDst 1;
BA_ "SignalType" SG_ 1296 VADIR_FlwDst "UNM";
BA_ "PacketOrder" SG_ 1296 VADIR_FlwDst 3;
BA_ "SignalLongName" SG_ 1296 VADIR_FlwDst "Vehicle Ahead Distance Indication Request : Following Distance";
BA_ "VNSigAllNodes" SG_ 536 ACCHptcStVbnRqSeqN 1;
BA_ "SignalType" SG_ 536 ACCHptcStVbnRqSeqN "UNM";
BA_ "SignalLongName" SG_ 536 ACCHptcStVbnRqSeqN "Adaptive Cruise Control Haptic Seat Vibration Request Sequence Number";
BA_ "VNSigAllNodes" SG_ 536 ACCHptcStVbnReq 1;
BA_ "SignalType" SG_ 536 ACCHptcStVbnReq "UNM";
BA_ "SignalLongName" SG_ 536 ACCHptcStVbnReq "Adaptive Cruise Control Haptic Seat Vibration Request";
BA_ "GenSigSendType" SG_ 536 ShtToPrkBfExtngVehIO 10;
BA_ "VNSigAllNodes" SG_ 536 ShtToPrkBfExtngVehIO 1;
BA_ "SignalType" SG_ 536 ShtToPrkBfExtngVehIO "BLN";
BA_ "SignalLongName" SG_ 536 ShtToPrkBfExtngVehIO "Shift to Park Before Exiting Vehicle Indication On";
BA_ "GenSigSendType" SG_ 536 AutoBrkRlsIO 10;
BA_ "VNSigAllNodes" SG_ 536 AutoBrkRlsIO 1;
BA_ "SignalType" SG_ 536 AutoBrkRlsIO "BLN";
BA_ "SignalLongName" SG_ 536 AutoBrkRlsIO "Autonomous Brake state0800 Indication On";
BA_ "GenSigSendType" SG_ 536 HdUpDsplyUnblIO 10;
BA_ "VNSigAllNodes" SG_ 536 HdUpDsplyUnblIO 1;
BA_ "SignalType" SG_ 536 HdUpDsplyUnblIO "BLN";
BA_ "SignalLongName" SG_ 536 HdUpDsplyUnblIO "Head Up Display Unavailable Indication On";
BA_ "GenSigSendType" SG_ 536 FSRACCFrstRsmPrssIO 10;
BA_ "VNSigAllNodes" SG_ 536 FSRACCFrstRsmPrssIO 1;
BA_ "SignalType" SG_ 536 FSRACCFrstRsmPrssIO "BLN";
BA_ "SignalLongName" SG_ 536 FSRACCFrstRsmPrssIO "Full Speed Range Adaptive Cruise Control First Resume Press Indication On";
BA_ "GenSigSendType" SG_ 536 FrtRdrBlckdIO 10;
BA_ "VNSigAllNodes" SG_ 536 FrtRdrBlckdIO 1;
BA_ "SignalType" SG_ 536 FrtRdrBlckdIO "BLN";
BA_ "SignalLongName" SG_ 536 FrtRdrBlckdIO "Front Radar Blocked Indication On";
BA_ "VNSigAllNodes" SG_ 848 TrlrBrkStat 1;
BA_ "SignalType" SG_ 848 TrlrBrkStat "ENM";
BA_ "SignalLongName" SG_ 848 TrlrBrkStat "Trailer Brake Status";
BA_ "VNSigAllNodes" SG_ 848 TrlrBrkngSysBrkLtsReq 1;
BA_ "SignalType" SG_ 848 TrlrBrkngSysBrkLtsReq "BLN";
BA_ "SignalLongName" SG_ 848 TrlrBrkngSysBrkLtsReq "Trailer Braking System Brake Lights Requested";
BA_ "VNSigAllNodes" SG_ 848 SrvTrlrBrkngSysIO 1;
BA_ "SignalType" SG_ 848 SrvTrlrBrkngSysIO "BLN";
BA_ "SignalLongName" SG_ 848 SrvTrlrBrkngSysIO "ServiceTrailer Braking System Indication On";
BA_ "VNSigAllNodes" SG_ 848 TrlrWiringFltIO 1;
BA_ "SignalType" SG_ 848 TrlrWiringFltIO "BLN";
BA_ "SignalLongName" SG_ 848 TrlrWiringFltIO "Trailer Wiring Fault Indication On";
BA_ "VNSigAllNodes" SG_ 848 TrlrCnctdIO 1;
BA_ "SignalType" SG_ 848 TrlrCnctdIO "BLN";
BA_ "SignalLongName" SG_ 848 TrlrCnctdIO "Trailer Connected Indication On";
BA_ "VNSigAllNodes" SG_ 848 TrlrBrkngGainSetIO 1;
BA_ "SignalType" SG_ 848 TrlrBrkngGainSetIO "BLN";
BA_ "SignalLongName" SG_ 848 TrlrBrkngGainSetIO "Trailer Braking Gain Setting Indication On";
BA_ "VNSigAllNodes" SG_ 848 TrlrBrkngGainSet 1;
BA_ "SignalType" SG_ 848 TrlrBrkngGainSet "UNM";
BA_ "SignalLongName" SG_ 848 TrlrBrkngGainSet "Trailer Braking Gain Setting";
BA_ "VNSigAllNodes" SG_ 848 TrlrBrkngFrcOtpt 1;
BA_ "SignalType" SG_ 848 TrlrBrkngFrcOtpt "UNM";
BA_ "SignalLongName" SG_ 848 TrlrBrkngFrcOtpt "Trailer Braking Force Output";
BA_ "VNSigAllNodes" SG_ 848 ChkTrlrIO 1;
BA_ "SignalType" SG_ 848 ChkTrlrIO "BLN";
BA_ "SignalLongName" SG_ 848 ChkTrlrIO "Check Trailer Indication On";
BA_ "VNSigAllNodes" SG_ 848 TrlrHtchSwAtv_ITBC 1;
BA_ "SignalType" SG_ 848 TrlrHtchSwAtv_ITBC "BLN";
BA_ "SignalLongName" SG_ 848 TrlrHtchSwAtv_ITBC "Trailer Hitch Switch Active ITBC";
BA_ "VNSigAllNodes" SG_ 993 HybVehHiVltSysDisbld 1;
BA_ "SignalType" SG_ 993 HybVehHiVltSysDisbld "BLN";
BA_ "SignalLongName" SG_ 993 HybVehHiVltSysDisbld "Hybrid Vehicle High Voltage System Disabled";
BA_ "GenSigSendOnInit" SG_ 993 CstmrUsblSOCV 1;
BA_ "GenSigSendType" SG_ 993 CstmrUsblSOCV 10;
BA_ "VNSigAllNodes" SG_ 993 CstmrUsblSOCV 1;
BA_ "SignalType" SG_ 993 CstmrUsblSOCV "ENM";
BA_ "SignalLongName" SG_ 993 CstmrUsblSOCV "Customer Usable State of Charge Validity";
BA_ "GenSigSendOnInit" SG_ 993 CstmrUsblSOC 1;
BA_ "GenSigSendType" SG_ 993 CstmrUsblSOC 12;
BA_ "GenSigDeltaValue" SG_ 993 CstmrUsblSOC 1;
BA_ "VNSigAllNodes" SG_ 993 CstmrUsblSOC 1;
BA_ "SignalType" SG_ 993 CstmrUsblSOC "UNM";
BA_ "SignalLongName" SG_ 993 CstmrUsblSOC "Customer Usable State of Charge";
BA_ "GenSigSendOnInit" SG_ 993 InstDrvEff 1;
BA_ "GenSigSendType" SG_ 993 InstDrvEff 12;
BA_ "GenSigDeltaValue" SG_ 993 InstDrvEff 1;
BA_ "VNSigAllNodes" SG_ 993 InstDrvEff 1;
BA_ "SignalType" SG_ 993 InstDrvEff "SNM";
BA_ "SignalLongName" SG_ 993 InstDrvEff "Instantaneous Drive Efficiency";
BA_ "VNSigAllNodes" SG_ 993 PwrPckAirInTempFlt 1;
BA_ "SignalType" SG_ 993 PwrPckAirInTempFlt "UNM";
BA_ "SignalLongName" SG_ 993 PwrPckAirInTempFlt "Power Pack Air Inlet Temperature Filtered";
BA_ "VNSigAllNodes" SG_ 993 PwrPkFnSpd 1;
BA_ "SignalType" SG_ 993 PwrPkFnSpd "UNM";
BA_ "SignalLongName" SG_ 993 PwrPkFnSpd "Power Pack Fan Speed";
BA_ "GenSigSendOnInit" SG_ 993 JmpStrtStat 1;
BA_ "GenSigSendType" SG_ 993 JmpStrtStat 10;
BA_ "VNSigAllNodes" SG_ 993 JmpStrtStat 1;
BA_ "SignalType" SG_ 993 JmpStrtStat "ENM";
BA_ "SignalLongName" SG_ 993 JmpStrtStat "Jump Start Status";
BA_ "GenSigSendOnInit" SG_ 993 SvcHybridSysIO 1;
BA_ "GenSigSendType" SG_ 993 SvcHybridSysIO 10;
BA_ "VNSigAllNodes" SG_ 993 SvcHybridSysIO 1;
BA_ "SignalType" SG_ 993 SvcHybridSysIO "BLN";
BA_ "SignalLongName" SG_ 993 SvcHybridSysIO "Service Hybrid System Indication On";
BA_ "GenSigSendOnInit" SG_ 993 HybMdDisp 1;
BA_ "GenSigSendType" SG_ 993 HybMdDisp 10;
BA_ "VNSigAllNodes" SG_ 993 HybMdDisp 1;
BA_ "SignalType" SG_ 993 HybMdDisp "ENM";
BA_ "SignalLongName" SG_ 993 HybMdDisp "Hybrid Mode Display";
BA_ "GenSigSendType" SG_ 1280 TireRRLowTracIO 10;
BA_ "VNSigAllNodes" SG_ 1280 TireRRLowTracIO 1;
BA_ "SignalType" SG_ 1280 TireRRLowTracIO "BLN";
BA_ "SignalLongName" SG_ 1280 TireRRLowTracIO "Tire Right Rear Low Traction Indication On";
BA_ "GenSigSendType" SG_ 1280 TireRFLowTracIO 10;
BA_ "VNSigAllNodes" SG_ 1280 TireRFLowTracIO 1;
BA_ "SignalType" SG_ 1280 TireRFLowTracIO "BLN";
BA_ "SignalLongName" SG_ 1280 TireRFLowTracIO "Tire Right Front Low Traction Indication On";
BA_ "GenSigSendType" SG_ 1280 TireLRLowTracIO 10;
BA_ "VNSigAllNodes" SG_ 1280 TireLRLowTracIO 1;
BA_ "SignalType" SG_ 1280 TireLRLowTracIO "BLN";
BA_ "SignalLongName" SG_ 1280 TireLRLowTracIO "Tire Left Rear Low Traction Indication On";
BA_ "GenSigSendType" SG_ 1280 TireLFLowTracIO 10;
BA_ "VNSigAllNodes" SG_ 1280 TireLFLowTracIO 1;
BA_ "SignalType" SG_ 1280 TireLFLowTracIO "BLN";
BA_ "SignalLongName" SG_ 1280 TireLFLowTracIO "Tire Left Front Low Traction Indication On";
BA_ "VNSigAllNodes" SG_ 1280 WhlRotStatTmstmpRes 1;
BA_ "SignalType" SG_ 1280 WhlRotStatTmstmpRes "UNM";
BA_ "SignalLongName" SG_ 1280 WhlRotStatTmstmpRes "Wheel Rotational Status Timestamp Resolution";
BA_ "VNSigAllNodes" SG_ 1280 WhlPlsPerRevNonDrvn 1;
BA_ "SignalType" SG_ 1280 WhlPlsPerRevNonDrvn "UNM";
BA_ "SignalLongName" SG_ 1280 WhlPlsPerRevNonDrvn "Wheel Pulses Per Revolution Non Driven";
BA_ "VNSigAllNodes" SG_ 1280 WhlPlsPerRevDrvn 1;
BA_ "SignalType" SG_ 1280 WhlPlsPerRevDrvn "UNM";
BA_ "SignalLongName" SG_ 1280 WhlPlsPerRevDrvn "Wheel Pulses Per Revolution Driven";
BA_ "VNSigAllNodes" SG_ 562 DrvlneMntsPerfMdRq 1;
BA_ "SignalType" SG_ 562 DrvlneMntsPerfMdRq "ENM";
BA_ "SignalLongName" SG_ 562 DrvlneMntsPerfMdRq "Driveline Mounts Performance Mode Request";
BA_ "VNSigAllNodes" SG_ 562 RideCntrlPerfMdRq 1;
BA_ "SignalType" SG_ 562 RideCntrlPerfMdRq "ENM";
BA_ "SignalLongName" SG_ 562 RideCntrlPerfMdRq "Ride Control Performance Mode Request";
BA_ "VNSigAllNodes" SG_ 562 StgSysPerfMdRq 1;
BA_ "SignalType" SG_ 562 StgSysPerfMdRq "ENM";
BA_ "SignalLongName" SG_ 562 StgSysPerfMdRq "Steering System Performance Mode Request";
BA_ "VNSigAllNodes" SG_ 562 DiffPerfMdRq 1;
BA_ "SignalType" SG_ 562 DiffPerfMdRq "ENM";
BA_ "SignalLongName" SG_ 562 DiffPerfMdRq "Differential Performance Mode Request";
BA_ "VNSigAllNodes" SG_ 562 ExhstPerfMdRq 1;
BA_ "SignalType" SG_ 562 ExhstPerfMdRq "ENM";
BA_ "SignalLongName" SG_ 562 ExhstPerfMdRq "Exhaust Performance Mode Request";
BA_ "VNSigAllNodes" SG_ 562 DrvMdCntrlState 1;
BA_ "SignalType" SG_ 562 DrvMdCntrlState "UNM";
BA_ "SignalLongName" SG_ 562 DrvMdCntrlState "Driving Mode Control State";
BA_ "VNSigAllNodes" SG_ 562 AWDPerfMdRq 1;
BA_ "SignalType" SG_ 562 AWDPerfMdRq "ENM";
BA_ "SignalLongName" SG_ 562 AWDPerfMdRq "AWD Performance Mode Request";
BA_ "VNSigAllNodes" SG_ 562 DispPerfMdCsCrStVal 1;
BA_ "SignalType" SG_ 562 DispPerfMdCsCrStVal "ENM";
BA_ "SignalLongName" SG_ 562 DispPerfMdCsCrStVal "Display Performance Mode Customization Current Setting Value";
BA_ "VNSigAllNodes" SG_ 562 SndEnhcmtPerfMdRq 1;
BA_ "SignalType" SG_ 562 SndEnhcmtPerfMdRq "ENM";
BA_ "SignalLongName" SG_ 562 SndEnhcmtPerfMdRq "Sound Enhancement Performance Mode Request";
BA_ "GenSigSendType" SG_ 562 DsplyPerfMdRq 10;
BA_ "VNSigAllNodes" SG_ 562 DsplyPerfMdRq 1;
BA_ "SignalType" SG_ 562 DsplyPerfMdRq "ENM";
BA_ "SignalLongName" SG_ 562 DsplyPerfMdRq "Display Performance Mode Request";
BA_ "VNSigAllNodes" SG_ 562 HillDscntCntlSysStat 1;
BA_ "SignalType" SG_ 562 HillDscntCntlSysStat "ENM";
BA_ "SignalLongName" SG_ 562 HillDscntCntlSysStat "Hill Descent Control System Status";
BA_ "VNSigAllNodes" SG_ 562 SusCustStngAvlbl 1;
BA_ "SignalType" SG_ 562 SusCustStngAvlbl "BLN";
BA_ "SignalLongName" SG_ 562 SusCustStngAvlbl "Suspension Customization Setting Available";
BA_ "VNSigAllNodes" SG_ 562 SusCustCurrStngVal 1;
BA_ "SignalType" SG_ 562 SusCustCurrStngVal "ENM";
BA_ "SignalLongName" SG_ 562 SusCustCurrStngVal "Suspension Customization Current Setting Value";
BA_ "VNSigAllNodes" SG_ 562 StrCustStngAvlbl 1;
BA_ "SignalType" SG_ 562 StrCustStngAvlbl "BLN";
BA_ "SignalLongName" SG_ 562 StrCustStngAvlbl "Steering Customization Setting Available";
BA_ "VNSigAllNodes" SG_ 562 StrCustCurrStngVal 1;
BA_ "SignalType" SG_ 562 StrCustCurrStngVal "ENM";
BA_ "SignalLongName" SG_ 562 StrCustCurrStngVal "Steering Customization Current Setting Value";
BA_ "VNSigAllNodes" SG_ 562 DrvlnCustStngAvlbl 1;
BA_ "SignalType" SG_ 562 DrvlnCustStngAvlbl "BLN";
BA_ "SignalLongName" SG_ 562 DrvlnCustStngAvlbl "Driveline Customization Setting Available";
BA_ "VNSigAllNodes" SG_ 562 DrvlnCustCurrStngVal 1;
BA_ "SignalType" SG_ 562 DrvlnCustCurrStngVal "ENM";
BA_ "SignalLongName" SG_ 562 DrvlnCustCurrStngVal "Driveline Customization Current Setting Value";
BA_ "VNSigAllNodes" SG_ 562 SndPerfMdCsStAvl 1;
BA_ "SignalType" SG_ 562 SndPerfMdCsStAvl "BLN";
BA_ "SignalLongName" SG_ 562 SndPerfMdCsStAvl "Sound Performance Mode Customization Setting Available";
BA_ "VNSigAllNodes" SG_ 562 SndPerfMdCsCrStVal 1;
BA_ "SignalType" SG_ 562 SndPerfMdCsCrStVal "ENM";
BA_ "SignalLongName" SG_ 562 SndPerfMdCsCrStVal "Sound Performance Mode Customization Current Setting Value";
BA_ "VNSigAllNodes" SG_ 562 DispPerfMdCsStAvl 1;
BA_ "SignalType" SG_ 562 DispPerfMdCsStAvl "BLN";
BA_ "SignalLongName" SG_ 562 DispPerfMdCsStAvl "Display Performance Mode Customization Setting Available";
BA_ "GenSigSendOnInit" SG_ 893 AFLMnu3CstStAvl 2;
BA_ "GenSigSendType" SG_ 893 AFLMnu3CstStAvl 10;
BA_ "VNSigAllNodes" SG_ 893 AFLMnu3CstStAvl 1;
BA_ "SignalType" SG_ 893 AFLMnu3CstStAvl "BLN";
BA_ "SignalLongName" SG_ 893 AFLMnu3CstStAvl "Adaptive Forward Lighting Menu 3 Customization Setting Available";
BA_ "GenSigSendOnInit" SG_ 893 AFLMnu2CstStAvl 2;
BA_ "GenSigSendType" SG_ 893 AFLMnu2CstStAvl 10;
BA_ "VNSigAllNodes" SG_ 893 AFLMnu2CstStAvl 1;
BA_ "SignalType" SG_ 893 AFLMnu2CstStAvl "BLN";
BA_ "SignalLongName" SG_ 893 AFLMnu2CstStAvl "Adaptive Forward Lighting Menu 2 Customization Setting Available";
BA_ "GenSigSendOnInit" SG_ 893 AFLGPSMnu2CstStAvl 2;
BA_ "GenSigSendType" SG_ 893 AFLGPSMnu2CstStAvl 10;
BA_ "VNSigAllNodes" SG_ 893 AFLGPSMnu2CstStAvl 1;
BA_ "SignalType" SG_ 893 AFLGPSMnu2CstStAvl "BLN";
BA_ "SignalLongName" SG_ 893 AFLGPSMnu2CstStAvl "Adaptive Forward Lighting With GPS Menu 2 Customization Setting Avail";
BA_ "GenSigSendOnInit" SG_ 893 AFLGPSCstStAvl 2;
BA_ "GenSigSendType" SG_ 893 AFLGPSCstStAvl 10;
BA_ "VNSigAllNodes" SG_ 893 AFLGPSCstStAvl 1;
BA_ "SignalType" SG_ 893 AFLGPSCstStAvl "BLN";
BA_ "SignalLongName" SG_ 893 AFLGPSCstStAvl "Adaptive Forward Lighting With GPS Customization Setting Available";
BA_ "GenSigSendOnInit" SG_ 893 AFLGPSCstCrStVal 2;
BA_ "GenSigSendType" SG_ 893 AFLGPSCstCrStVal 10;
BA_ "VNSigAllNodes" SG_ 893 AFLGPSCstCrStVal 1;
BA_ "SignalType" SG_ 893 AFLGPSCstCrStVal "ENM";
BA_ "SignalLongName" SG_ 893 AFLGPSCstCrStVal "Adaptive Forward Lighting With GPS Customization Current Setting Value";
BA_ "GenSigSendOnInit" SG_ 893 AFLCstStAvl 2;
BA_ "GenSigSendType" SG_ 893 AFLCstStAvl 10;
BA_ "VNSigAllNodes" SG_ 893 AFLCstStAvl 1;
BA_ "SignalType" SG_ 893 AFLCstStAvl "BLN";
BA_ "SignalLongName" SG_ 893 AFLCstStAvl "Adaptive Forward Lighting Customization Setting Available";
BA_ "GenSigSendOnInit" SG_ 893 AFLCstCrStVal 2;
BA_ "GenSigSendType" SG_ 893 AFLCstCrStVal 10;
BA_ "VNSigAllNodes" SG_ 893 AFLCstCrStVal 1;
BA_ "SignalType" SG_ 893 AFLCstCrStVal "ENM";
BA_ "SignalLongName" SG_ 893 AFLCstCrStVal "Adaptive Forward Lighting Customization Current Setting Value";
BA_ "GenSigSendOnInit" SG_ 892 AdpHgBmAsSnCsCrStVal 2;
BA_ "GenSigSendType" SG_ 892 AdpHgBmAsSnCsCrStVal 10;
BA_ "VNSigAllNodes" SG_ 892 AdpHgBmAsSnCsCrStVal 1;
BA_ "SignalType" SG_ 892 AdpHgBmAsSnCsCrStVal "ENM";
BA_ "SignalLongName" SG_ 892 AdpHgBmAsSnCsCrStVal "Adaptive High Beam Assist With Sensitivity Customization Current Setting Value";
BA_ "GenSigSendOnInit" SG_ 892 AdpHgBmAsSnCsStAvl 2;
BA_ "GenSigSendType" SG_ 892 AdpHgBmAsSnCsStAvl 10;
BA_ "VNSigAllNodes" SG_ 892 AdpHgBmAsSnCsStAvl 1;
BA_ "SignalType" SG_ 892 AdpHgBmAsSnCsStAvl "BLN";
BA_ "SignalLongName" SG_ 892 AdpHgBmAsSnCsStAvl "Adaptive High Beam Assist With Sensitivity Customization Setting Available";
BA_ "GenSigSendOnInit" SG_ 892 AdpHgBmAsCsCrStVal 2;
BA_ "GenSigSendType" SG_ 892 AdpHgBmAsCsCrStVal 10;
BA_ "VNSigAllNodes" SG_ 892 AdpHgBmAsCsCrStVal 1;
BA_ "SignalType" SG_ 892 AdpHgBmAsCsCrStVal "ENM";
BA_ "SignalLongName" SG_ 892 AdpHgBmAsCsCrStVal "Adaptive High Beam Assist Customization Current Setting Value";
BA_ "GenSigSendOnInit" SG_ 892 AdpHgBmAsCsStAvl 2;
BA_ "GenSigSendType" SG_ 892 AdpHgBmAsCsStAvl 10;
BA_ "VNSigAllNodes" SG_ 892 AdpHgBmAsCsStAvl 1;
BA_ "SignalType" SG_ 892 AdpHgBmAsCsStAvl "BLN";
BA_ "SignalLongName" SG_ 892 AdpHgBmAsCsStAvl "Adaptive High Beam Assist Customization Setting Available";
BA_ "GenSigSendOnInit" SG_ 892 AutHgBmAsCsCrStVal 2;
BA_ "GenSigSendType" SG_ 892 AutHgBmAsCsCrStVal 10;
BA_ "VNSigAllNodes" SG_ 892 AutHgBmAsCsCrStVal 1;
BA_ "SignalType" SG_ 892 AutHgBmAsCsCrStVal "ENM";
BA_ "SignalLongName" SG_ 892 AutHgBmAsCsCrStVal "Auto High Beam Assist Customization Current Setting Value";
BA_ "GenSigSendOnInit" SG_ 892 AutHgBmAsSnCsStAvl 2;
BA_ "GenSigSendType" SG_ 892 AutHgBmAsSnCsStAvl 10;
BA_ "VNSigAllNodes" SG_ 892 AutHgBmAsSnCsStAvl 1;
BA_ "SignalType" SG_ 892 AutHgBmAsSnCsStAvl "BLN";
BA_ "SignalLongName" SG_ 892 AutHgBmAsSnCsStAvl "Auto High Beam Assist With Sensitivity Customization Setting Available";
BA_ "GenSigSendOnInit" SG_ 892 AutHgBmAsSnCsCrStVa 2;
BA_ "GenSigSendType" SG_ 892 AutHgBmAsSnCsCrStVa 10;
BA_ "VNSigAllNodes" SG_ 892 AutHgBmAsSnCsCrStVa 1;
BA_ "SignalType" SG_ 892 AutHgBmAsSnCsCrStVa "ENM";
BA_ "SignalLongName" SG_ 892 AutHgBmAsSnCsCrStVa "Auto High Beam Assist With Sensitivity Customization Current Setting Value";
BA_ "GenSigSendOnInit" SG_ 892 AutHgBmAsCsStAvl 2;
BA_ "GenSigSendType" SG_ 892 AutHgBmAsCsStAvl 10;
BA_ "VNSigAllNodes" SG_ 892 AutHgBmAsCsStAvl 1;
BA_ "SignalType" SG_ 892 AutHgBmAsCsStAvl "BLN";
BA_ "SignalLongName" SG_ 892 AutHgBmAsCsStAvl "Auto High Beam Assist Customization Setting Available";
BA_ "VNSigAllNodes" SG_ 386 AHAct 1;
BA_ "SignalType" SG_ 386 AHAct "BLN";
BA_ "SignalLongName" SG_ 386 AHAct "Auto Hold Active";
BA_ "VNSigAllNodes" SG_ 386 AHEnbld 1;
BA_ "SignalType" SG_ 386 AHEnbld "BLN";
BA_ "SignalLongName" SG_ 386 AHEnbld "Auto Hold Enabled";
BA_ "VNSigAllNodes" SG_ 386 ShfToPrkBfExtngIO 1;
BA_ "SignalType" SG_ 386 ShfToPrkBfExtngIO "BLN";
BA_ "SignalLongName" SG_ 386 ShfToPrkBfExtngIO "Shift To Park Before Exiting Indication On";
BA_ "VNSigAllNodes" SG_ 386 AHServcIO 1;
BA_ "SignalType" SG_ 386 AHServcIO "BLN";
BA_ "SignalLongName" SG_ 386 AHServcIO "Auto Hold Service Indication On";
BA_ "VNSigAllNodes" SG_ 386 AHAppBrkPedlIO 1;
BA_ "SignalType" SG_ 386 AHAppBrkPedlIO "BLN";
BA_ "SignalLongName" SG_ 386 AHAppBrkPedlIO "Auto Hold Apply Brake Pedal Indication On";
BA_ "VNSigAllNodes" SG_ 386 AHDisbldStbltIO 1;
BA_ "SignalType" SG_ 386 AHDisbldStbltIO "BLN";
BA_ "SignalLongName" SG_ 386 AHDisbldStbltIO "Auto Hold Disabled Seatbelt Indication On";
BA_ "VNSigAllNodes" SG_ 386 AHDisbldDrOpnIO 1;
BA_ "SignalType" SG_ 386 AHDisbldDrOpnIO "BLN";
BA_ "SignalLongName" SG_ 386 AHDisbldDrOpnIO "Auto Hold Disabled Door Open Indication On";
BA_ "GenSigSendOnInit" SG_ 386 PMVSS_Disps 2;
BA_ "GenSigSendType" SG_ 386 PMVSS_Disps 10;
BA_ "VNSigAllNodes" SG_ 386 PMVSS_Disps 1;
BA_ "SignalType" SG_ 386 PMVSS_Disps "ENM";
BA_ "PacketOrder" SG_ 386 PMVSS_Disps 11;
BA_ "SignalLongName" SG_ 386 PMVSS_Disps "Performance Mode Visualization Screen Status : Displays";
BA_ "GenSigSendOnInit" SG_ 386 PMVSS_Exhst 2;
BA_ "GenSigSendType" SG_ 386 PMVSS_Exhst 10;
BA_ "VNSigAllNodes" SG_ 386 PMVSS_Exhst 1;
BA_ "SignalType" SG_ 386 PMVSS_Exhst "ENM";
BA_ "PacketOrder" SG_ 386 PMVSS_Exhst 10;
BA_ "SignalLongName" SG_ 386 PMVSS_Exhst "Performance Mode Visualization Screen Status : Exhaust";
BA_ "GenSigSendOnInit" SG_ 386 PMVSS_PsngrSeat 2;
BA_ "GenSigSendType" SG_ 386 PMVSS_PsngrSeat 10;
BA_ "VNSigAllNodes" SG_ 386 PMVSS_PsngrSeat 1;
BA_ "SignalType" SG_ 386 PMVSS_PsngrSeat "ENM";
BA_ "PacketOrder" SG_ 386 PMVSS_PsngrSeat 9;
BA_ "SignalLongName" SG_ 386 PMVSS_PsngrSeat "Performance Mode Visualization Screen Status : Passenger Seat";
BA_ "GenSigSendOnInit" SG_ 386 PMVSS_DrvrSeat 2;
BA_ "GenSigSendType" SG_ 386 PMVSS_DrvrSeat 10;
BA_ "VNSigAllNodes" SG_ 386 PMVSS_DrvrSeat 1;
BA_ "SignalType" SG_ 386 PMVSS_DrvrSeat "ENM";
BA_ "PacketOrder" SG_ 386 PMVSS_DrvrSeat 8;
BA_ "SignalLongName" SG_ 386 PMVSS_DrvrSeat "Performance Mode Visualization Screen Status : Driver Seat";
BA_ "GenSigSendOnInit" SG_ 386 PMVSS_AdptCrsCnt 2;
BA_ "GenSigSendType" SG_ 386 PMVSS_AdptCrsCnt 10;
BA_ "VNSigAllNodes" SG_ 386 PMVSS_AdptCrsCnt 1;
BA_ "SignalType" SG_ 386 PMVSS_AdptCrsCnt "ENM";
BA_ "PacketOrder" SG_ 386 PMVSS_AdptCrsCnt 7;
BA_ "SignalLongName" SG_ 386 PMVSS_AdptCrsCnt "Performance Mode Visualization Screen Status : Adaptive Cruise Control";
BA_ "GenSigSendOnInit" SG_ 386 PMVSS_Drvln 2;
BA_ "GenSigSendType" SG_ 386 PMVSS_Drvln 10;
BA_ "VNSigAllNodes" SG_ 386 PMVSS_Drvln 1;
BA_ "SignalType" SG_ 386 PMVSS_Drvln "ENM";
BA_ "PacketOrder" SG_ 386 PMVSS_Drvln 6;
BA_ "SignalLongName" SG_ 386 PMVSS_Drvln "Performance Mode Visualization Screen Status : Driveline";
BA_ "GenSigSendOnInit" SG_ 386 PMVSS_Susp 2;
BA_ "GenSigSendType" SG_ 386 PMVSS_Susp 10;
BA_ "VNSigAllNodes" SG_ 386 PMVSS_Susp 1;
BA_ "SignalType" SG_ 386 PMVSS_Susp "ENM";
BA_ "PacketOrder" SG_ 386 PMVSS_Susp 5;
BA_ "SignalLongName" SG_ 386 PMVSS_Susp "Performance Mode Visualization Screen Status : Suspension";
BA_ "GenSigSendOnInit" SG_ 386 PMVSS_Strng 2;
BA_ "GenSigSendType" SG_ 386 PMVSS_Strng 10;
BA_ "VNSigAllNodes" SG_ 386 PMVSS_Strng 1;
BA_ "SignalType" SG_ 386 PMVSS_Strng "ENM";
BA_ "PacketOrder" SG_ 386 PMVSS_Strng 4;
BA_ "SignalLongName" SG_ 386 PMVSS_Strng "Performance Mode Visualization Screen Status : Steering";
BA_ "GenSigSendOnInit" SG_ 386 PMVSS_Trans 2;
BA_ "GenSigSendType" SG_ 386 PMVSS_Trans 10;
BA_ "VNSigAllNodes" SG_ 386 PMVSS_Trans 1;
BA_ "SignalType" SG_ 386 PMVSS_Trans "ENM";
BA_ "PacketOrder" SG_ 386 PMVSS_Trans 3;
BA_ "SignalLongName" SG_ 386 PMVSS_Trans "Performance Mode Visualization Screen Status : Transmission";
BA_ "GenSigSendOnInit" SG_ 386 PMVSS_Eng 2;
BA_ "GenSigSendType" SG_ 386 PMVSS_Eng 10;
BA_ "VNSigAllNodes" SG_ 386 PMVSS_Eng 1;
BA_ "SignalType" SG_ 386 PMVSS_Eng "ENM";
BA_ "PacketOrder" SG_ 386 PMVSS_Eng 2;
BA_ "SignalLongName" SG_ 386 PMVSS_Eng "Performance Mode Visualization Screen Status : Engine";
BA_ "GenSigSendOnInit" SG_ 386 PMVSS_Snd 2;
BA_ "GenSigSendType" SG_ 386 PMVSS_Snd 10;
BA_ "VNSigAllNodes" SG_ 386 PMVSS_Snd 1;
BA_ "SignalType" SG_ 386 PMVSS_Snd "ENM";
BA_ "PacketOrder" SG_ 386 PMVSS_Snd 1;
BA_ "SignalLongName" SG_ 386 PMVSS_Snd "Performance Mode Visualization Screen Status : Sound";
BA_ "VNSigAllNodes" SG_ 386 EnvIdRsp4 1;
BA_ "SignalType" SG_ 386 EnvIdRsp4 "UNM";
BA_ "SignalLongName" SG_ 386 EnvIdRsp4 "Environment Identification Response 4";
BA_ "VNSigAllNodes" SG_ 386 EnvIdRspSt4 1;
BA_ "SignalType" SG_ 386 EnvIdRspSt4 "ENM";
BA_ "SignalLongName" SG_ 386 EnvIdRspSt4 "Environment Identification Response Status 4";
BA_ "VNSigAllNodes" SG_ 386 AdptCruzCtrlStg 1;
BA_ "SignalType" SG_ 386 AdptCruzCtrlStg "ENM";
BA_ "SignalLongName" SG_ 386 AdptCruzCtrlStg "Adaptive Cruise Control Setting";
BA_ "VNSigAllNodes" SG_ 532 RedntVSEActARC 1;
BA_ "SignalType" SG_ 532 RedntVSEActARC "UNM";
BA_ "SignalLongName" SG_ 532 RedntVSEActARC "Redundant Vehicle Stability Enhancement System Active Alive Rolling Count";
BA_ "VNSigAllNodes" SG_ 532 RedntVSEAct 1;
BA_ "SignalType" SG_ 532 RedntVSEAct "BLN";
BA_ "SignalLongName" SG_ 532 RedntVSEAct "Redundant Vehicle Stability Enhancement System Active";
BA_ "VNSigAllNodes" SG_ 532 AutoBrkngActARC 1;
BA_ "SignalType" SG_ 532 AutoBrkngActARC "UNM";
BA_ "SignalLongName" SG_ 532 AutoBrkngActARC "Automatic Braking Active Alive Rolling Count";
BA_ "VNSigAllNodes" SG_ 532 VehHldDrvrDsblActvFlg 1;
BA_ "SignalType" SG_ 532 VehHldDrvrDsblActvFlg "BLN";
BA_ "SignalLongName" SG_ 532 VehHldDrvrDsblActvFlg "Vehicle Hold Driver Disable Active Flag";
BA_ "VNSigAllNodes" SG_ 532 ABSAutnmsBrkReqPVal 1;
BA_ "SignalType" SG_ 532 ABSAutnmsBrkReqPVal "UNM";
BA_ "SignalLongName" SG_ 532 ABSAutnmsBrkReqPVal "Antilock Brake System Autonomous Braking Request Protection Value";
BA_ "VNSigAllNodes" SG_ 532 AutoBrkngAvlbl 1;
BA_ "SignalType" SG_ 532 AutoBrkngAvlbl "BLN";
BA_ "SignalLongName" SG_ 532 AutoBrkngAvlbl "Automatic Braking Available";
BA_ "VNSigAllNodes" SG_ 532 ABSAutnmsBrkReqARC 1;
BA_ "SignalType" SG_ 532 ABSAutnmsBrkReqARC "UNM";
BA_ "SignalLongName" SG_ 532 ABSAutnmsBrkReqARC "Antilock Brake System Autonomous Braking Request Alive Rolling Count";
BA_ "VNSigAllNodes" SG_ 532 ABSAutnmsBrkReq 1;
BA_ "SignalType" SG_ 532 ABSAutnmsBrkReq "BLN";
BA_ "SignalLongName" SG_ 532 ABSAutnmsBrkReq "Antilock Brake System Autonomous Braking Request";
BA_ "VNSigAllNodes" SG_ 532 ABSActvProtPVal 1;
BA_ "SignalType" SG_ 532 ABSActvProtPVal "UNM";
BA_ "SignalLongName" SG_ 532 ABSActvProtPVal "Antilock Brake System Active Protected Protection Value";
BA_ "VNSigAllNodes" SG_ 532 ABSActvProtARC 1;
BA_ "SignalType" SG_ 532 ABSActvProtARC "UNM";
BA_ "SignalLongName" SG_ 532 ABSActvProtARC "Antilock Brake System Active Protected Alive Rolling Count";
BA_ "VNSigAllNodes" SG_ 532 ABSActvProt 1;
BA_ "SignalType" SG_ 532 ABSActvProt "BLN";
BA_ "SignalLongName" SG_ 532 ABSActvProt "Antilock Brake System Active Protected";
BA_ "GenSigSendType" SG_ 532 HilRlbkCtrlActIO 10;
BA_ "VNSigAllNodes" SG_ 532 HilRlbkCtrlActIO 1;
BA_ "SignalType" SG_ 532 HilRlbkCtrlActIO "BLN";
BA_ "SignalLongName" SG_ 532 HilRlbkCtrlActIO "Hill Rollback Control Active Indiction On";
BA_ "VNSigAllNodes" SG_ 532 HlStrAssActIO 1;
BA_ "SignalType" SG_ 532 HlStrAssActIO "BLN";
BA_ "SignalLongName" SG_ 532 HlStrAssActIO "Hill Start Assist Active Indication On";
BA_ "VNSigAllNodes" SG_ 532 BrkSysAutBrkFld 1;
BA_ "SignalType" SG_ 532 BrkSysAutBrkFld "BLN";
BA_ "SignalLongName" SG_ 532 BrkSysAutBrkFld "Brake System Automatic Braking Failed";
BA_ "VNSigAllNodes" SG_ 532 IntBrkAssPreFilReq 1;
BA_ "SignalType" SG_ 532 IntBrkAssPreFilReq "BLN";
BA_ "SignalLongName" SG_ 532 IntBrkAssPreFilReq "Inteligent Brake Assist Pre-Fil Request";
BA_ "VNSigAllNodes" SG_ 532 BrkSysMalFuncIndOn 1;
BA_ "SignalType" SG_ 532 BrkSysMalFuncIndOn "BLN";
BA_ "SignalLongName" SG_ 532 BrkSysMalFuncIndOn "Brake System Malfunction Indication On";
BA_ "VNSigAllNodes" SG_ 532 BPDAPS_BkPDrvApPV 1;
BA_ "SignalType" SG_ 532 BPDAPS_BkPDrvApPV "ENM";
BA_ "PacketOrder" SG_ 532 BPDAPS_BkPDrvApPV 2;
BA_ "SignalLongName" SG_ 532 BPDAPS_BkPDrvApPV "Brake Pedal Driver Applied Pressure Status : Brake Pedal Driver Applied Pressure Validity";
BA_ "VNSigAllNodes" SG_ 532 BPDAPS_BkPDrvApP 1;
BA_ "SignalType" SG_ 532 BPDAPS_BkPDrvApP "UNM";
BA_ "PacketOrder" SG_ 532 BPDAPS_BkPDrvApP 1;
BA_ "SignalLongName" SG_ 532 BPDAPS_BkPDrvApP "Brake Pedal Driver Applied Pressure Status : Brake Pedal Driver Applied Pressure";
BA_ "VNSigAllNodes" SG_ 532 BrkFldLvlLwV 1;
BA_ "SignalType" SG_ 532 BrkFldLvlLwV "ENM";
BA_ "SignalLongName" SG_ 532 BrkFldLvlLwV "Brake Fluid Level Low Validity";
BA_ "VNSigAllNodes" SG_ 532 BrkFldLvlLw 1;
BA_ "SignalType" SG_ 532 BrkFldLvlLw "BLN";
BA_ "SignalLongName" SG_ 532 BrkFldLvlLw "Brake Fluid Level Low";
BA_ "VNSigAllNodes" SG_ 532 BrkPdDrvAPrsStaPVal 1;
BA_ "SignalType" SG_ 532 BrkPdDrvAPrsStaPVal "UNM";
BA_ "SignalLongName" SG_ 532 BrkPdDrvAPrsStaPVal "Brake Pedal Driver Applied Pressure Status Protection Value";
BA_ "VNSigAllNodes" SG_ 532 BrkPdDrvAppPrsAlRC 1;
BA_ "SignalType" SG_ 532 BrkPdDrvAppPrsAlRC "UNM";
BA_ "SignalLongName" SG_ 532 BrkPdDrvAppPrsAlRC "Brake Pedal Driver Applied Pressure Alive Rolling Count";
BA_ "VNSigAllNodes" SG_ 532 AutoBrkngAct 1;
BA_ "SignalType" SG_ 532 AutoBrkngAct "BLN";
BA_ "SignalLongName" SG_ 532 AutoBrkngAct "Automatic Braking Active";
BA_ "GenSigSendOnInit" SG_ 890 LtRtHnTrGPCsCrStVal 2;
BA_ "GenSigSendType" SG_ 890 LtRtHnTrGPCsCrStVal 10;
BA_ "VNSigAllNodes" SG_ 890 LtRtHnTrGPCsCrStVal 1;
BA_ "SignalType" SG_ 890 LtRtHnTrGPCsCrStVal "ENM";
BA_ "SignalLongName" SG_ 890 LtRtHnTrGPCsCrStVal "Left Right Hand Traffic With GPS Customization Current Setting Value";
BA_ "GenSigSendOnInit" SG_ 890 LtRtHnTrGPSCsStAvl 2;
BA_ "GenSigSendType" SG_ 890 LtRtHnTrGPSCsStAvl 10;
BA_ "VNSigAllNodes" SG_ 890 LtRtHnTrGPSCsStAvl 1;
BA_ "SignalType" SG_ 890 LtRtHnTrGPSCsStAvl "BLN";
BA_ "SignalLongName" SG_ 890 LtRtHnTrGPSCsStAvl "Left Right Hand Traffic With GPS Customization Setting Available";
BA_ "GenSigSendOnInit" SG_ 890 LtRtHnTrCstStVal 2;
BA_ "GenSigSendType" SG_ 890 LtRtHnTrCstStVal 10;
BA_ "VNSigAllNodes" SG_ 890 LtRtHnTrCstStVal 1;
BA_ "SignalType" SG_ 890 LtRtHnTrCstStVal "ENM";
BA_ "SignalLongName" SG_ 890 LtRtHnTrCstStVal "Left Right Hand Traffic Customization Current Setting Value";
BA_ "GenSigSendOnInit" SG_ 890 LtRtHnTrCstStAvail 2;
BA_ "GenSigSendType" SG_ 890 LtRtHnTrCstStAvail 10;
BA_ "VNSigAllNodes" SG_ 890 LtRtHnTrCstStAvail 1;
BA_ "SignalType" SG_ 890 LtRtHnTrCstStAvail "ENM";
BA_ "SignalLongName" SG_ 890 LtRtHnTrCstStAvail "Left Right Hand Traffic Customization Setting Available";
BA_ "GenSigSendType" SG_ 328 StrngAsstRdcdIO 10;
BA_ "VNSigAllNodes" SG_ 328 StrngAsstRdcdIO 1;
BA_ "SignalType" SG_ 328 StrngAsstRdcdIO "BLN";
BA_ "SignalLongName" SG_ 328 StrngAsstRdcdIO "Steering Assist Reduced Indication On";
BA_ "GenSigSendType" SG_ 328 PwrStrIO 10;
BA_ "VNSigAllNodes" SG_ 328 PwrStrIO 1;
BA_ "SignalType" SG_ 328 PwrStrIO "BLN";
BA_ "SignalLongName" SG_ 328 PwrStrIO "Power Steering Indication On";
BA_ "VNSigAllNodes" SG_ 560 ElecPrkBrkCmdProt 1;
BA_ "SignalType" SG_ 560 ElecPrkBrkCmdProt "UNM";
BA_ "SignalLongName" SG_ 560 ElecPrkBrkCmdProt "Electric Park Brake Command Protection";
BA_ "VNSigAllNodes" SG_ 560 ElecPrkBrkSwStatV 1;
BA_ "SignalType" SG_ 560 ElecPrkBrkSwStatV "ENM";
BA_ "SignalLongName" SG_ 560 ElecPrkBrkSwStatV "Electric Park Brake Switch Status Validity";
BA_ "VNSigAllNodes" SG_ 560 ElecPrkBrkCmdARC 1;
BA_ "SignalType" SG_ 560 ElecPrkBrkCmdARC "UNM";
BA_ "SignalLongName" SG_ 560 ElecPrkBrkCmdARC "Electric Park Brake Command Alive Rolling Count";
BA_ "VNSigAllNodes" SG_ 560 ElecPrkBrkSwStat 1;
BA_ "SignalType" SG_ 560 ElecPrkBrkSwStat "ENM";
BA_ "SignalLongName" SG_ 560 ElecPrkBrkSwStat "Electric Park Brake Switch Status";
BA_ "VNSigAllNodes" SG_ 560 EPBC_EPBAccRq 1;
BA_ "SignalType" SG_ 560 EPBC_EPBAccRq "SNM";
BA_ "PacketOrder" SG_ 560 EPBC_EPBAccRq 2;
BA_ "SignalLongName" SG_ 560 EPBC_EPBAccRq "Electric Park Brake Command : Electric Park Brake Acceleration Requested";
BA_ "VNSigAllNodes" SG_ 560 EPBC_EPBrkAutBrkRq 1;
BA_ "SignalType" SG_ 560 EPBC_EPBrkAutBrkRq "BLN";
BA_ "PacketOrder" SG_ 560 EPBC_EPBrkAutBrkRq 1;
BA_ "SignalLongName" SG_ 560 EPBC_EPBrkAutBrkRq "Electric Park Brake Command : Electric Park Brake Signal1879";
BA_ "VNSigSLHS_VNReq" SG_ 560 AllNodesVNA 1;
BA_ "VNSigAllNodes" SG_ 560 AllNodesVNA 1;
BA_ "SignalType" SG_ 560 AllNodesVNA "ENM";
BA_ "SignalLongName" SG_ 560 AllNodesVNA "All Nodes Virtual Network Activation";
BA_ "VNSigAllNodes" SG_ 560 StpOnBrkToRelPBIndOn 1;
BA_ "SignalType" SG_ 560 StpOnBrkToRelPBIndOn "BLN";
BA_ "SignalLongName" SG_ 560 StpOnBrkToRelPBIndOn "Step On Brake To state0800 Park Brake Indication On";
BA_ "VNSigAllNodes" SG_ 560 EPBSysDspMsgReq 1;
BA_ "SignalType" SG_ 560 EPBSysDspMsgReq "ENM";
BA_ "SignalLongName" SG_ 560 EPBSysDspMsgReq "Electric Park Brake System Display Message Request";
BA_ "VNSigAllNodes" SG_ 560 EPBSysAudWarnReq 1;
BA_ "SignalType" SG_ 560 EPBSysAudWarnReq "ENM";
BA_ "SignalLongName" SG_ 560 EPBSysAudWarnReq "Electric Park Brake System Audible Warning Request";
BA_ "VNSigAllNodes" SG_ 560 ElecPrkBrkStat 1;
BA_ "SignalType" SG_ 560 ElecPrkBrkStat "ENM";
BA_ "SignalLongName" SG_ 560 ElecPrkBrkStat "Electric Park Brake Status";
BA_ "VNSigAllNodes" SG_ 560 EPBCrsCanRq 1;
BA_ "SignalType" SG_ 560 EPBCrsCanRq "BLN";
BA_ "SignalLongName" SG_ 560 EPBCrsCanRq "Electric Park Brake Cruise Control Cancel Requested";
BA_ "VNSigAllNodes" SG_ 560 EPBSysStatIndReq 1;
BA_ "SignalType" SG_ 560 EPBSysStatIndReq "ENM";
BA_ "SignalLongName" SG_ 560 EPBSysStatIndReq "Electric Park Brake System Status Indication Request";
BA_ "VNSigAllNodes" SG_ 560 EPBSysWrnIndReq 1;
BA_ "SignalType" SG_ 560 EPBSysWrnIndReq "ENM";
BA_ "SignalLongName" SG_ 560 EPBSysWrnIndReq "Electric Park Brake System Warning Indication Request";
BA_ "VNSigAllNodes" SG_ 560 EPBSysBrkLtsReq 1;
BA_ "SignalType" SG_ 560 EPBSysBrkLtsReq "BLN";
BA_ "SignalLongName" SG_ 560 EPBSysBrkLtsReq "Electric Park Brake System Brake Lights Requested";
BA_ "VNSigAllNodes" SG_ 1282 TireTrdTmpStatARC 1;
BA_ "SignalType" SG_ 1282 TireTrdTmpStatARC "UNM";
BA_ "SignalLongName" SG_ 1282 TireTrdTmpStatARC "Tire Tread Temperature Status Alive Rolling Count";
BA_ "GenSigSendType" SG_ 1282 TireTrdTmpStat 10;
BA_ "VNSigAllNodes" SG_ 1282 TireTrdTmpStat 1;
BA_ "SignalType" SG_ 1282 TireTrdTmpStat "ENM";
BA_ "SignalLongName" SG_ 1282 TireTrdTmpStat "Tire Tread Temperature Status";
BA_ "VNSigSLHS_VNReq" SG_ 1282 AllNodesVNA_502 1;
BA_ "VNSigAllNodes" SG_ 1282 AllNodesVNA_502 1;
BA_ "SignalType" SG_ 1282 AllNodesVNA_502 "ENM";
BA_ "SignalLongName" SG_ 1282 AllNodesVNA_502 "All Nodes Virtual Network Activation";
BA_ "VNSigAllNodes" SG_ 1282 A3ERRAlrmTime 1;
BA_ "SignalType" SG_ 1282 A3ERRAlrmTime "UNM";
BA_ "PacketOrder" SG_ 1282 A3ERRAlrmTime 2;
BA_ "SignalLongName" SG_ 1282 A3ERRAlrmTime "Alarm 3 Extended Range Request : Alarm Time";
BA_ "VNSigAllNodes" SG_ 1282 A3ERRAlrmReq 1;
BA_ "SignalType" SG_ 1282 A3ERRAlrmReq "ENM";
BA_ "PacketOrder" SG_ 1282 A3ERRAlrmReq 1;
BA_ "SignalLongName" SG_ 1282 A3ERRAlrmReq "Alarm 3 Extended Range Request : Alarm Request";
BA_ "GenSigSendType" SG_ 2033 PCUInfo 12;
BA_ "GenSigDeltaValue" SG_ 2033 PCUInfo 1;
BA_ "VNSigAllNodes" SG_ 2033 PCUInfo 1;
BA_ "SignalType" SG_ 2033 PCUInfo "UNM";
BA_ "SignalLongName" SG_ 2033 PCUInfo "Pyrotechnical Control Unit Information";
BA_ "VNSigAllNodes" SG_ 1219 DslExhFldDiagWrnIdRq 1;
BA_ "SignalType" SG_ 1219 DslExhFldDiagWrnIdRq "ENM";
BA_ "SignalLongName" SG_ 1219 DslExhFldDiagWrnIdRq "Diesel Exhaust Fluid System Diagnostic Warning Indication Request";
BA_ "VNSigAllNodes" SG_ 1219 DslEmnsOBDMrkt 1;
BA_ "SignalType" SG_ 1219 DslEmnsOBDMrkt "ENM";
BA_ "SignalLongName" SG_ 1219 DslEmnsOBDMrkt "Diesel Emissions OBD Market";
BA_ "VNSigAllNodes" SG_ 1219 DslExNxEmWrngIndRq 1;
BA_ "SignalType" SG_ 1219 DslExNxEmWrngIndRq "ENM";
BA_ "SignalLongName" SG_ 1219 DslExNxEmWrngIndRq "Diesel Exhaust NOx Emissions Too High Warning Indication Request";
BA_ "VNSigAllNodes" SG_ 1219 DEFWVSL_S3SpdLmt 1;
BA_ "SignalType" SG_ 1219 DEFWVSL_S3SpdLmt "UNM";
BA_ "PacketOrder" SG_ 1219 DEFWVSL_S3SpdLmt 3;
BA_ "SignalLongName" SG_ 1219 DEFWVSL_S3SpdLmt "Diesel Exhaust Fluid Warning Vehicle Speed Limit : Stage 3 Vehicle Speed Limit";
BA_ "VNSigAllNodes" SG_ 1219 DEFWVSL_S2SpdLmt 1;
BA_ "SignalType" SG_ 1219 DEFWVSL_S2SpdLmt "UNM";
BA_ "PacketOrder" SG_ 1219 DEFWVSL_S2SpdLmt 2;
BA_ "SignalLongName" SG_ 1219 DEFWVSL_S2SpdLmt "Diesel Exhaust Fluid Warning Vehicle Speed Limit : Stage 2 Vehicle Speed Limit";
BA_ "VNSigAllNodes" SG_ 1219 DEFWVSL_S1SpdLmt 1;
BA_ "SignalType" SG_ 1219 DEFWVSL_S1SpdLmt "UNM";
BA_ "PacketOrder" SG_ 1219 DEFWVSL_S1SpdLmt 1;
BA_ "SignalLongName" SG_ 1219 DEFWVSL_S1SpdLmt "Diesel Exhaust Fluid Warning Vehicle Speed Limit : Stage 1 Vehicle Speed Limit";
BA_ "VNSigAllNodes" SG_ 1219 DslExFldTpWrngIndRq 1;
BA_ "SignalType" SG_ 1219 DslExFldTpWrngIndRq "ENM";
BA_ "SignalLongName" SG_ 1219 DslExFldTpWrngIndRq "Diesel Exhaust Fluid Tampering Warning Indication Request";
BA_ "VNSigAllNodes" SG_ 1219 DslExhFldQlyWrngIReq 1;
BA_ "SignalType" SG_ 1219 DslExhFldQlyWrngIReq "ENM";
BA_ "SignalLongName" SG_ 1219 DslExhFldQlyWrngIReq "Diesel Exhaust Fluid Quality Warning Indication Request";
BA_ "VNSigAllNodes" SG_ 1219 DslExhFldWrngIdRqER 1;
BA_ "SignalType" SG_ 1219 DslExhFldWrngIdRqER "ENM";
BA_ "SignalLongName" SG_ 1219 DslExhFldWrngIdRqER "Diesel Exhaust Fluid Level Warning Indication Request Extended Range";
BA_ "VNSigAllNodes" SG_ 1219 DslExFldCnWrngIndRq 1;
BA_ "SignalType" SG_ 1219 DslExFldCnWrngIndRq "ENM";
BA_ "SignalLongName" SG_ 1219 DslExFldCnWrngIndRq "Diesel Exhaust Fluid Consumption Monitoring Warning Indication Request";
BA_ "VNSigAllNodes" SG_ 442 CrksftTqMinImCapV 1;
BA_ "SignalType" SG_ 442 CrksftTqMinImCapV "ENM";
BA_ "SignalLongName" SG_ 442 CrksftTqMinImCapV "Crankshaft Torque Minimum Immediate Capacity Validity";
BA_ "VNSigAllNodes" SG_ 442 CrksftTqMinImCap 1;
BA_ "SignalType" SG_ 442 CrksftTqMinImCap "UNM";
BA_ "SignalLongName" SG_ 442 CrksftTqMinImCap "Crankshaft Torque Minimum Immediate Capacity";
BA_ "VNSigAllNodes" SG_ 442 DrvIntndCrksftTrqRw 1;
BA_ "SignalType" SG_ 442 DrvIntndCrksftTrqRw "UNM";
BA_ "SignalLongName" SG_ 442 DrvIntndCrksftTrqRw "Driver Intended Crankshaft Torque Raw";
BA_ "VNSigAllNodes" SG_ 442 DrvIntndCrksftTrqMin 1;
BA_ "SignalType" SG_ 442 DrvIntndCrksftTrqMin "UNM";
BA_ "SignalLongName" SG_ 442 DrvIntndCrksftTrqMin "Driver Intended Crankshaft Torque Minimum";
BA_ "VNSigAllNodes" SG_ 442 DrvIntndCrksftTrq 1;
BA_ "SignalType" SG_ 442 DrvIntndCrksftTrq "UNM";
BA_ "SignalLongName" SG_ 442 DrvIntndCrksftTrq "Driver Intended Crankshaft Torque";
BA_ "VNSigAllNodes" SG_ 442 CrksftMaxTrqLmtV 1;
BA_ "SignalType" SG_ 442 CrksftMaxTrqLmtV "ENM";
BA_ "SignalLongName" SG_ 442 CrksftMaxTrqLmtV "Crankshaft Maximum Torque Limit Validity";
BA_ "VNSigAllNodes" SG_ 442 CrksftMaxTrqLmt 1;
BA_ "SignalType" SG_ 442 CrksftMaxTrqLmt "UNM";
BA_ "SignalLongName" SG_ 442 CrksftMaxTrqLmt "Crankshaft Maximum Torque Limit";
BA_ "VNSigAllNodes" SG_ 988 EGHRInhbtRqstd 1;
BA_ "SignalType" SG_ 988 EGHRInhbtRqstd "BLN";
BA_ "SignalLongName" SG_ 988 EGHRInhbtRqstd "Exhaust Gas Heat Recovery Inhibit Requested";
BA_ "VNSigAllNodes" SG_ 988 AccPwrModMinCoolRq 1;
BA_ "SignalType" SG_ 988 AccPwrModMinCoolRq "ENM";
BA_ "SignalLongName" SG_ 988 AccPwrModMinCoolRq "Accessory Power Module Minimum Cooling Request";
BA_ "VNSigAllNodes" SG_ 988 A6ERRAlrmTime 1;
BA_ "SignalType" SG_ 988 A6ERRAlrmTime "UNM";
BA_ "PacketOrder" SG_ 988 A6ERRAlrmTime 2;
BA_ "SignalLongName" SG_ 988 A6ERRAlrmTime "Alarm 6 Extended Range Request : Alarm Time";
BA_ "VNSigAllNodes" SG_ 988 A6ERRAlrmReq 1;
BA_ "SignalType" SG_ 988 A6ERRAlrmReq "ENM";
BA_ "PacketOrder" SG_ 988 A6ERRAlrmReq 1;
BA_ "SignalLongName" SG_ 988 A6ERRAlrmReq "Alarm 6 Extended Range Request : Alarm Request";
BA_ "GenSigSendType" SG_ 988 EngMntncePrcntCpl 12;
BA_ "GenSigDeltaValue" SG_ 988 EngMntncePrcntCpl 1;
BA_ "VNSigAllNodes" SG_ 988 EngMntncePrcntCpl 1;
BA_ "SignalType" SG_ 988 EngMntncePrcntCpl "UNM";
BA_ "SignalLongName" SG_ 988 EngMntncePrcntCpl "Engine Maintenance Percent Complete";
BA_ "GenSigSendOnInit" SG_ 988 MntnceMdDsplyRq 1;
BA_ "GenSigSendType" SG_ 988 MntnceMdDsplyRq 10;
BA_ "VNSigAllNodes" SG_ 988 MntnceMdDsplyRq 1;
BA_ "SignalType" SG_ 988 MntnceMdDsplyRq "ENM";
BA_ "SignalLongName" SG_ 988 MntnceMdDsplyRq "Maintenance Mode Display Request";
BA_ "GenSigSendType" SG_ 988 EngMntnceMdAct 10;
BA_ "VNSigAllNodes" SG_ 988 EngMntnceMdAct 1;
BA_ "SignalType" SG_ 988 EngMntnceMdAct "BLN";
BA_ "SignalLongName" SG_ 988 EngMntnceMdAct "Engine Maintenance Mode Active";
BA_ "VNSigAllNodes" SG_ 988 HVPropChgrUnbl 1;
BA_ "SignalType" SG_ 988 HVPropChgrUnbl "BLN";
BA_ "SignalLongName" SG_ 988 HVPropChgrUnbl "High Voltage Propulsion Charging Unavailable";
BA_ "VNSigAllNodes" SG_ 988 EngHtrValvBpasCmd 1;
BA_ "SignalType" SG_ 988 EngHtrValvBpasCmd "ENM";
BA_ "SignalLongName" SG_ 988 EngHtrValvBpasCmd "Engine Heater Valve Bypass Command";
BA_ "VNSigAllNodes" SG_ 500 EnhDrvMdSwChUseAct 1;
BA_ "SignalType" SG_ 500 EnhDrvMdSwChUseAct "BLN";
BA_ "SignalLongName" SG_ 500 EnhDrvMdSwChUseAct "Enhanced Driver Selected Mode Switch Chassis Use Active";
BA_ "VNSigAllNodes" SG_ 500 EnhDrvSelMdSwStat 1;
BA_ "SignalType" SG_ 500 EnhDrvSelMdSwStat "ENM";
BA_ "SignalLongName" SG_ 500 EnhDrvSelMdSwStat "Enhanced Driver Selected Mode Switch Status";
BA_ "GenSigSendType" SG_ 500 DrvSelMd8Stat 10;
BA_ "VNSigAllNodes" SG_ 500 DrvSelMd8Stat 1;
BA_ "SignalType" SG_ 500 DrvSelMd8Stat "ENM";
BA_ "SignalLongName" SG_ 500 DrvSelMd8Stat "Driver Selected Mode 8 Status";
BA_ "GenSigSendType" SG_ 500 DrvSelMd8ReqDnd 10;
BA_ "VNSigAllNodes" SG_ 500 DrvSelMd8ReqDnd 1;
BA_ "SignalType" SG_ 500 DrvSelMd8ReqDnd "BLN";
BA_ "SignalLongName" SG_ 500 DrvSelMd8ReqDnd "Driver Selected Mode 8 Request Denied";
BA_ "GenSigSendType" SG_ 500 DrvSelMd7Stat 10;
BA_ "VNSigAllNodes" SG_ 500 DrvSelMd7Stat 1;
BA_ "SignalType" SG_ 500 DrvSelMd7Stat "ENM";
BA_ "SignalLongName" SG_ 500 DrvSelMd7Stat "Driver Selected Mode 7 Status";
BA_ "GenSigSendType" SG_ 500 DrvSelMd7ReqDnd 10;
BA_ "VNSigAllNodes" SG_ 500 DrvSelMd7ReqDnd 1;
BA_ "SignalType" SG_ 500 DrvSelMd7ReqDnd "BLN";
BA_ "SignalLongName" SG_ 500 DrvSelMd7ReqDnd "Driver Selected Mode 7 Request Denied";
BA_ "GenSigSendType" SG_ 500 DrvSelMd6Stat 10;
BA_ "VNSigAllNodes" SG_ 500 DrvSelMd6Stat 1;
BA_ "SignalType" SG_ 500 DrvSelMd6Stat "ENM";
BA_ "SignalLongName" SG_ 500 DrvSelMd6Stat "Driver Selected Mode 6 Status";
BA_ "GenSigSendType" SG_ 500 DrvSelMd6ReqDnd 10;
BA_ "VNSigAllNodes" SG_ 500 DrvSelMd6ReqDnd 1;
BA_ "SignalType" SG_ 500 DrvSelMd6ReqDnd "BLN";
BA_ "SignalLongName" SG_ 500 DrvSelMd6ReqDnd "Driver Selected Mode 6 Request Denied";
BA_ "GenSigSendType" SG_ 500 DrvSelMd5Stat 10;
BA_ "VNSigAllNodes" SG_ 500 DrvSelMd5Stat 1;
BA_ "SignalType" SG_ 500 DrvSelMd5Stat "ENM";
BA_ "SignalLongName" SG_ 500 DrvSelMd5Stat "Driver Selected Mode 5 Status";
BA_ "GenSigSendType" SG_ 500 DrvSelMd5ReqDnd 10;
BA_ "VNSigAllNodes" SG_ 500 DrvSelMd5ReqDnd 1;
BA_ "SignalType" SG_ 500 DrvSelMd5ReqDnd "BLN";
BA_ "SignalLongName" SG_ 500 DrvSelMd5ReqDnd "Driver Selected Mode 5 Request Denied";
BA_ "GenSigSendType" SG_ 500 DrvSelMd4Stat 10;
BA_ "VNSigAllNodes" SG_ 500 DrvSelMd4Stat 1;
BA_ "SignalType" SG_ 500 DrvSelMd4Stat "ENM";
BA_ "SignalLongName" SG_ 500 DrvSelMd4Stat "Driver Selected Mode 4 Status";
BA_ "GenSigSendType" SG_ 500 DrvSelMd4ReqDnd 10;
BA_ "VNSigAllNodes" SG_ 500 DrvSelMd4ReqDnd 1;
BA_ "SignalType" SG_ 500 DrvSelMd4ReqDnd "BLN";
BA_ "SignalLongName" SG_ 500 DrvSelMd4ReqDnd "Driver Selected Mode 4 Request Denied";
BA_ "GenSigSendOnInit" SG_ 500 DrvSelMd3Stat 1;
BA_ "GenSigSendType" SG_ 500 DrvSelMd3Stat 10;
BA_ "VNSigAllNodes" SG_ 500 DrvSelMd3Stat 1;
BA_ "SignalType" SG_ 500 DrvSelMd3Stat "ENM";
BA_ "SignalLongName" SG_ 500 DrvSelMd3Stat "Driver Selected Mode 3 Status";
BA_ "GenSigSendType" SG_ 500 DrvSelMd3ReqDnd 10;
BA_ "VNSigAllNodes" SG_ 500 DrvSelMd3ReqDnd 1;
BA_ "SignalType" SG_ 500 DrvSelMd3ReqDnd "BLN";
BA_ "SignalLongName" SG_ 500 DrvSelMd3ReqDnd "Driver Selected Mode 3 Request Denied";
BA_ "GenSigSendOnInit" SG_ 500 DrvSelMd2Stat 1;
BA_ "GenSigSendType" SG_ 500 DrvSelMd2Stat 10;
BA_ "VNSigAllNodes" SG_ 500 DrvSelMd2Stat 1;
BA_ "SignalType" SG_ 500 DrvSelMd2Stat "ENM";
BA_ "SignalLongName" SG_ 500 DrvSelMd2Stat "Driver Selected Mode 2 Status";
BA_ "GenSigSendType" SG_ 500 DrvSelMd2ReqDnd 10;
BA_ "VNSigAllNodes" SG_ 500 DrvSelMd2ReqDnd 1;
BA_ "SignalType" SG_ 500 DrvSelMd2ReqDnd "BLN";
BA_ "SignalLongName" SG_ 500 DrvSelMd2ReqDnd "Driver Selected Mode 2 Request Denied";
BA_ "GenSigSendOnInit" SG_ 500 DSMSS_DrvSelMd0Pn 1;
BA_ "GenSigSendType" SG_ 500 DSMSS_DrvSelMd0Pn 10;
BA_ "VNSigAllNodes" SG_ 500 DSMSS_DrvSelMd0Pn 1;
BA_ "SignalType" SG_ 500 DSMSS_DrvSelMd0Pn "BLN";
BA_ "PacketOrder" SG_ 500 DSMSS_DrvSelMd0Pn 17;
BA_ "SignalLongName" SG_ 500 DSMSS_DrvSelMd0Pn "Driver Selected Mode Selection Status : Driver Selected Mode 0 Pending";
BA_ "GenSigSendOnInit" SG_ 500 DSMSS_DrvSelMd8Pn 1;
BA_ "GenSigSendType" SG_ 500 DSMSS_DrvSelMd8Pn 10;
BA_ "VNSigAllNodes" SG_ 500 DSMSS_DrvSelMd8Pn 1;
BA_ "SignalType" SG_ 500 DSMSS_DrvSelMd8Pn "BLN";
BA_ "PacketOrder" SG_ 500 DSMSS_DrvSelMd8Pn 16;
BA_ "SignalLongName" SG_ 500 DSMSS_DrvSelMd8Pn "Driver Selected Mode Selection Status : Driver Selected Mode 8 Pending";
BA_ "GenSigSendOnInit" SG_ 500 DSMSS_DrvSelMd7Pn 1;
BA_ "GenSigSendType" SG_ 500 DSMSS_DrvSelMd7Pn 10;
BA_ "VNSigAllNodes" SG_ 500 DSMSS_DrvSelMd7Pn 1;
BA_ "SignalType" SG_ 500 DSMSS_DrvSelMd7Pn "BLN";
BA_ "PacketOrder" SG_ 500 DSMSS_DrvSelMd7Pn 15;
BA_ "SignalLongName" SG_ 500 DSMSS_DrvSelMd7Pn "Driver Selected Mode Selection Status : Driver Selected Mode 7 Pending";
BA_ "GenSigSendOnInit" SG_ 500 DSMSS_DrvSelMd6Pn 1;
BA_ "GenSigSendType" SG_ 500 DSMSS_DrvSelMd6Pn 10;
BA_ "VNSigAllNodes" SG_ 500 DSMSS_DrvSelMd6Pn 1;
BA_ "SignalType" SG_ 500 DSMSS_DrvSelMd6Pn "BLN";
BA_ "PacketOrder" SG_ 500 DSMSS_DrvSelMd6Pn 14;
BA_ "SignalLongName" SG_ 500 DSMSS_DrvSelMd6Pn "Driver Selected Mode Selection Status : Driver Selected Mode 6 Pending";
BA_ "GenSigSendOnInit" SG_ 500 DSMSS_DrvSelMd5Pn 1;
BA_ "GenSigSendType" SG_ 500 DSMSS_DrvSelMd5Pn 10;
BA_ "VNSigAllNodes" SG_ 500 DSMSS_DrvSelMd5Pn 1;
BA_ "SignalType" SG_ 500 DSMSS_DrvSelMd5Pn "BLN";
BA_ "PacketOrder" SG_ 500 DSMSS_DrvSelMd5Pn 13;
BA_ "SignalLongName" SG_ 500 DSMSS_DrvSelMd5Pn "Driver Selected Mode Selection Status : Driver Selected Mode 5 Pending";
BA_ "GenSigSendOnInit" SG_ 500 DSMSS_DrvSelMd4Pn 1;
BA_ "GenSigSendType" SG_ 500 DSMSS_DrvSelMd4Pn 10;
BA_ "VNSigAllNodes" SG_ 500 DSMSS_DrvSelMd4Pn 1;
BA_ "SignalType" SG_ 500 DSMSS_DrvSelMd4Pn "BLN";
BA_ "PacketOrder" SG_ 500 DSMSS_DrvSelMd4Pn 12;
BA_ "SignalLongName" SG_ 500 DSMSS_DrvSelMd4Pn "Driver Selected Mode Selection Status : Driver Selected Mode 4 Pending";
BA_ "GenSigSendOnInit" SG_ 500 DSMSS_DrvSelMd3Pn 1;
BA_ "GenSigSendType" SG_ 500 DSMSS_DrvSelMd3Pn 10;
BA_ "VNSigAllNodes" SG_ 500 DSMSS_DrvSelMd3Pn 1;
BA_ "SignalType" SG_ 500 DSMSS_DrvSelMd3Pn "BLN";
BA_ "PacketOrder" SG_ 500 DSMSS_DrvSelMd3Pn 11;
BA_ "SignalLongName" SG_ 500 DSMSS_DrvSelMd3Pn "Driver Selected Mode Selection Status : Driver Selected Mode 3 Pending";
BA_ "GenSigSendOnInit" SG_ 500 DSMSS_DrvSelMd2Pn 1;
BA_ "GenSigSendType" SG_ 500 DSMSS_DrvSelMd2Pn 10;
BA_ "VNSigAllNodes" SG_ 500 DSMSS_DrvSelMd2Pn 1;
BA_ "SignalType" SG_ 500 DSMSS_DrvSelMd2Pn "BLN";
BA_ "PacketOrder" SG_ 500 DSMSS_DrvSelMd2Pn 10;
BA_ "SignalLongName" SG_ 500 DSMSS_DrvSelMd2Pn "Driver Selected Mode Selection Status : Driver Selected Mode 2 Pending";
BA_ "GenSigSendOnInit" SG_ 500 DSMSS_DrvSelMd1Pn 1;
BA_ "GenSigSendType" SG_ 500 DSMSS_DrvSelMd1Pn 10;
BA_ "VNSigAllNodes" SG_ 500 DSMSS_DrvSelMd1Pn 1;
BA_ "SignalType" SG_ 500 DSMSS_DrvSelMd1Pn "BLN";
BA_ "PacketOrder" SG_ 500 DSMSS_DrvSelMd1Pn 9;
BA_ "SignalLongName" SG_ 500 DSMSS_DrvSelMd1Pn "Driver Selected Mode Selection Status : Driver Selected Mode 1 Pending";
BA_ "GenSigSendOnInit" SG_ 500 DSMSS_DrvSelMd8Un 1;
BA_ "GenSigSendType" SG_ 500 DSMSS_DrvSelMd8Un 10;
BA_ "VNSigAllNodes" SG_ 500 DSMSS_DrvSelMd8Un 1;
BA_ "SignalType" SG_ 500 DSMSS_DrvSelMd8Un "BLN";
BA_ "PacketOrder" SG_ 500 DSMSS_DrvSelMd8Un 8;
BA_ "SignalLongName" SG_ 500 DSMSS_DrvSelMd8Un "Driver Selected Mode Selection Status : Driver Selected Mode 8 Unavailable";
BA_ "GenSigSendOnInit" SG_ 500 DSMSS_DrvSelMd7Un 1;
BA_ "GenSigSendType" SG_ 500 DSMSS_DrvSelMd7Un 10;
BA_ "VNSigAllNodes" SG_ 500 DSMSS_DrvSelMd7Un 1;
BA_ "SignalType" SG_ 500 DSMSS_DrvSelMd7Un "BLN";
BA_ "PacketOrder" SG_ 500 DSMSS_DrvSelMd7Un 7;
BA_ "SignalLongName" SG_ 500 DSMSS_DrvSelMd7Un "Driver Selected Mode Selection Status : Driver Selected Mode 7 Unavailable";
BA_ "GenSigSendOnInit" SG_ 500 DSMSS_DrvSelMd6Un 1;
BA_ "GenSigSendType" SG_ 500 DSMSS_DrvSelMd6Un 10;
BA_ "VNSigAllNodes" SG_ 500 DSMSS_DrvSelMd6Un 1;
BA_ "SignalType" SG_ 500 DSMSS_DrvSelMd6Un "BLN";
BA_ "PacketOrder" SG_ 500 DSMSS_DrvSelMd6Un 6;
BA_ "SignalLongName" SG_ 500 DSMSS_DrvSelMd6Un "Driver Selected Mode Selection Status : Driver Selected Mode 6 Unavailable";
BA_ "GenSigSendOnInit" SG_ 500 DSMSS_DrvSelMd5Un 1;
BA_ "GenSigSendType" SG_ 500 DSMSS_DrvSelMd5Un 10;
BA_ "VNSigAllNodes" SG_ 500 DSMSS_DrvSelMd5Un 1;
BA_ "SignalType" SG_ 500 DSMSS_DrvSelMd5Un "BLN";
BA_ "PacketOrder" SG_ 500 DSMSS_DrvSelMd5Un 5;
BA_ "SignalLongName" SG_ 500 DSMSS_DrvSelMd5Un "Driver Selected Mode Selection Status : Driver Selected Mode 5 Unavailable";
BA_ "GenSigSendOnInit" SG_ 500 DSMSS_DrvSelMd4Un 1;
BA_ "GenSigSendType" SG_ 500 DSMSS_DrvSelMd4Un 10;
BA_ "VNSigAllNodes" SG_ 500 DSMSS_DrvSelMd4Un 1;
BA_ "SignalType" SG_ 500 DSMSS_DrvSelMd4Un "BLN";
BA_ "PacketOrder" SG_ 500 DSMSS_DrvSelMd4Un 4;
BA_ "SignalLongName" SG_ 500 DSMSS_DrvSelMd4Un "Driver Selected Mode Selection Status : Driver Selected Mode 4 Unavailable";
BA_ "GenSigSendOnInit" SG_ 500 DSMSS_DrvSelMd3Un 1;
BA_ "GenSigSendType" SG_ 500 DSMSS_DrvSelMd3Un 10;
BA_ "VNSigAllNodes" SG_ 500 DSMSS_DrvSelMd3Un 1;
BA_ "SignalType" SG_ 500 DSMSS_DrvSelMd3Un "BLN";
BA_ "PacketOrder" SG_ 500 DSMSS_DrvSelMd3Un 3;
BA_ "SignalLongName" SG_ 500 DSMSS_DrvSelMd3Un "Driver Selected Mode Selection Status : Driver Selected Mode 3 Unavailable";
BA_ "GenSigSendOnInit" SG_ 500 DSMSS_DrvSelMd2Un 1;
BA_ "GenSigSendType" SG_ 500 DSMSS_DrvSelMd2Un 10;
BA_ "VNSigAllNodes" SG_ 500 DSMSS_DrvSelMd2Un 1;
BA_ "SignalType" SG_ 500 DSMSS_DrvSelMd2Un "BLN";
BA_ "PacketOrder" SG_ 500 DSMSS_DrvSelMd2Un 2;
BA_ "SignalLongName" SG_ 500 DSMSS_DrvSelMd2Un "Driver Selected Mode Selection Status : Driver Selected Mode 2 Unavailable";
BA_ "GenSigSendOnInit" SG_ 500 DSMSS_DrvSelMd1Un 1;
BA_ "GenSigSendType" SG_ 500 DSMSS_DrvSelMd1Un 10;
BA_ "VNSigAllNodes" SG_ 500 DSMSS_DrvSelMd1Un 1;
BA_ "SignalType" SG_ 500 DSMSS_DrvSelMd1Un "BLN";
BA_ "PacketOrder" SG_ 500 DSMSS_DrvSelMd1Un 1;
BA_ "SignalLongName" SG_ 500 DSMSS_DrvSelMd1Un "Driver Selected Mode Selection Status : Driver Selected Mode 1 Unavailable";
BA_ "GenSigSendType" SG_ 500 DrvSelMd1ReqDnd 10;
BA_ "VNSigAllNodes" SG_ 500 DrvSelMd1ReqDnd 1;
BA_ "SignalType" SG_ 500 DrvSelMd1ReqDnd "BLN";
BA_ "SignalLongName" SG_ 500 DrvSelMd1ReqDnd "Driver Selected Mode 1 Request Denied";
BA_ "GenSigSendOnInit" SG_ 500 DrvSelMd1Stat 1;
BA_ "GenSigSendType" SG_ 500 DrvSelMd1Stat 10;
BA_ "VNSigAllNodes" SG_ 500 DrvSelMd1Stat 1;
BA_ "SignalType" SG_ 500 DrvSelMd1Stat "ENM";
BA_ "SignalLongName" SG_ 500 DrvSelMd1Stat "Driver Selected Mode 1 Status";
BA_ "VNSigAllNodes" SG_ 1417 PrplsnTrqRelCap 1;
BA_ "SignalType" SG_ 1417 PrplsnTrqRelCap "UNM";
BA_ "SignalLongName" SG_ 1417 PrplsnTrqRelCap "Propulsion Torque Relative Capability";
BA_ "VNSigAllNodes" SG_ 1417 ETC_MinTorq 1;
BA_ "SignalType" SG_ 1417 ETC_MinTorq "UNM";
BA_ "PacketOrder" SG_ 1417 ETC_MinTorq 7;
BA_ "SignalLongName" SG_ 1417 ETC_MinTorq "Engine Torque Capability : Minimum Torque";
BA_ "VNSigAllNodes" SG_ 1417 ETC_MinRunTorq 1;
BA_ "SignalType" SG_ 1417 ETC_MinRunTorq "UNM";
BA_ "PacketOrder" SG_ 1417 ETC_MinRunTorq 6;
BA_ "SignalLongName" SG_ 1417 ETC_MinRunTorq "Engine Torque Capability : Minimum Run Torque";
BA_ "VNSigAllNodes" SG_ 1417 ETC_MaxTorq 1;
BA_ "SignalType" SG_ 1417 ETC_MaxTorq "UNM";
BA_ "PacketOrder" SG_ 1417 ETC_MaxTorq 5;
BA_ "SignalLongName" SG_ 1417 ETC_MaxTorq "Engine Torque Capability : Maximum Torque";
BA_ "VNSigAllNodes" SG_ 1417 ETC_RefEngSpd 1;
BA_ "SignalType" SG_ 1417 ETC_RefEngSpd "UNM";
BA_ "PacketOrder" SG_ 1417 ETC_RefEngSpd 4;
BA_ "SignalLongName" SG_ 1417 ETC_RefEngSpd "Engine Torque Capability : Reference Engine Speed";
BA_ "VNSigAllNodes" SG_ 1417 ETC_UnsdRsrvd 1;
BA_ "SignalType" SG_ 1417 ETC_UnsdRsrvd "UNM";
BA_ "PacketOrder" SG_ 1417 ETC_UnsdRsrvd 3;
BA_ "SignalLongName" SG_ 1417 ETC_UnsdRsrvd "Engine Torque Capability : Unused and Reserved";
BA_ "VNSigAllNodes" SG_ 1417 ETC_FrmCntr 1;
BA_ "SignalType" SG_ 1417 ETC_FrmCntr "UNM";
BA_ "PacketOrder" SG_ 1417 ETC_FrmCntr 2;
BA_ "SignalLongName" SG_ 1417 ETC_FrmCntr "Engine Torque Capability : Frame Counter";
BA_ "VNSigAllNodes" SG_ 1417 ETC_EngOpMd 1;
BA_ "SignalType" SG_ 1417 ETC_EngOpMd "ENM";
BA_ "PacketOrder" SG_ 1417 ETC_EngOpMd 1;
BA_ "SignalLongName" SG_ 1417 ETC_EngOpMd "Engine Torque Capability : Engine Operating Mode";
BA_ "VNSigAllNodes" SG_ 170 EngCommFlrRedPwrCm 1;
BA_ "SignalType" SG_ 170 EngCommFlrRedPwrCm "BLN";
BA_ "SignalLongName" SG_ 170 EngCommFlrRedPwrCm "Engine Communication Failure Reduced Power Commanded";
BA_ "VNSigAllNodes" SG_ 170 CmndAxlTrqARC 1;
BA_ "SignalType" SG_ 170 CmndAxlTrqARC "UNM";
BA_ "SignalLongName" SG_ 170 CmndAxlTrqARC "Commanded Axle Torque Alive Rolling Count";
BA_ "VNSigAllNodes" SG_ 170 CmndAxlTrqRespTyp 1;
BA_ "SignalType" SG_ 170 CmndAxlTrqRespTyp "ENM";
BA_ "SignalLongName" SG_ 170 CmndAxlTrqRespTyp "Commanded Axle Torque Response Type";
BA_ "VNSigAllNodes" SG_ 170 CmndAxlTrqImm 1;
BA_ "SignalType" SG_ 170 CmndAxlTrqImm "UNM";
BA_ "SignalLongName" SG_ 170 CmndAxlTrqImm "Commanded Axle Torque Immediate";
BA_ "VNSigAllNodes" SG_ 170 AccPos 1;
BA_ "SignalType" SG_ 170 AccPos "UNM";
BA_ "SignalLongName" SG_ 170 AccPos "Accelerator Effective Position";
BA_ "VNSigAllNodes" SG_ 170 CmndAxlTrqPredct 1;
BA_ "SignalType" SG_ 170 CmndAxlTrqPredct "UNM";
BA_ "SignalLongName" SG_ 170 CmndAxlTrqPredct "Commanded Axle Torque Predicted";
BA_ "VNSigAllNodes" SG_ 170 CmndAxlTrqPredctProtVal 1;
BA_ "SignalType" SG_ 170 CmndAxlTrqPredctProtVal "UNM";
BA_ "SignalLongName" SG_ 170 CmndAxlTrqPredctProtVal "Commanded Axle Torque Predicted Protection Value";
BA_ "GenSigSendType" SG_ 979 SpdLmtrSttngTypAct 10;
BA_ "VNSigAllNodes" SG_ 979 SpdLmtrSttngTypAct 1;
BA_ "SignalType" SG_ 979 SpdLmtrSttngTypAct "ENM";
BA_ "SignalLongName" SG_ 979 SpdLmtrSttngTypAct "Speed Limiter Setting Type Active";
BA_ "VNSigAllNodes" SG_ 979 SetSpdLmtRchd 1;
BA_ "SignalType" SG_ 979 SetSpdLmtRchd "ENM";
BA_ "SignalLongName" SG_ 979 SetSpdLmtRchd "Set Speed Limit Reached";
BA_ "VNSigAllNodes" SG_ 979 PlatEngSpdCmdStPVal 1;
BA_ "SignalType" SG_ 979 PlatEngSpdCmdStPVal "UNM";
BA_ "SignalLongName" SG_ 979 PlatEngSpdCmdStPVal "Platform Engine Speed Command Status Protection Value";
BA_ "VNSigAllNodes" SG_ 979 PlatEngSpdCmdStARC 1;
BA_ "SignalType" SG_ 979 PlatEngSpdCmdStARC "UNM";
BA_ "SignalLongName" SG_ 979 PlatEngSpdCmdStARC "Platform Engine Speed Command Status Alive Rolling Count";
BA_ "VNSigAllNodes" SG_ 979 ElvtdIdlCstCrStVal 1;
BA_ "SignalType" SG_ 979 ElvtdIdlCstCrStVal "ENM";
BA_ "SignalLongName" SG_ 979 ElvtdIdlCstCrStVal "Elevated Idle Customization Current Setting Value";
BA_ "VNSigAllNodes" SG_ 979 ElvtdIdlCstStAvl 1;
BA_ "SignalType" SG_ 979 ElvtdIdlCstStAvl "BLN";
BA_ "SignalLongName" SG_ 979 ElvtdIdlCstStAvl "Elevated Idle Customization Setting Available";
BA_ "VNSigAllNodes" SG_ 979 PTABR_AccReq 1;
BA_ "SignalType" SG_ 979 PTABR_AccReq "SNM";
BA_ "PacketOrder" SG_ 979 PTABR_AccReq 2;
BA_ "SignalLongName" SG_ 979 PTABR_AccReq "Powertrain Automatic Braking Request : Acceleration Request";
BA_ "VNSigAllNodes" SG_ 979 PTABR_PTBrkRqAct 1;
BA_ "SignalType" SG_ 979 PTABR_PTBrkRqAct "BLN";
BA_ "PacketOrder" SG_ 979 PTABR_PTBrkRqAct 1;
BA_ "SignalLongName" SG_ 979 PTABR_PTBrkRqAct "Powertrain Automatic Braking Request : Powertrain Brake Request Active";
BA_ "VNSigAllNodes" SG_ 979 PTAutoBrkReqPVal 1;
BA_ "SignalType" SG_ 979 PTAutoBrkReqPVal "UNM";
BA_ "SignalLongName" SG_ 979 PTAutoBrkReqPVal "Powertrain Automatic Braking Request Protection Value";
BA_ "VNSigAllNodes" SG_ 979 PTAutoBrkReqARC 1;
BA_ "SignalType" SG_ 979 PTAutoBrkReqARC "UNM";
BA_ "SignalLongName" SG_ 979 PTAutoBrkReqARC "Powertrain Automatic Braking Request Alive Rolling Count";
BA_ "VNSigAllNodes" SG_ 979 BrkBstVacV 1;
BA_ "SignalType" SG_ 979 BrkBstVacV "ENM";
BA_ "SignalLongName" SG_ 979 BrkBstVacV "Brake Boost Vacuum Validity";
BA_ "VNSigAllNodes" SG_ 979 BrkBstVac 1;
BA_ "SignalType" SG_ 979 BrkBstVac "UNM";
BA_ "SignalLongName" SG_ 979 BrkBstVac "Brake Boost Vacuum";
BA_ "VNSigAllNodes" SG_ 979 EngManfldAirTempCrtdV 1;
BA_ "SignalType" SG_ 979 EngManfldAirTempCrtdV "ENM";
BA_ "SignalLongName" SG_ 979 EngManfldAirTempCrtdV "Engine Manifold Air Temperature Corrected Validity";
BA_ "VNSigAllNodes" SG_ 979 PltfrmEngSpdCmmndSt 1;
BA_ "SignalType" SG_ 979 PltfrmEngSpdCmmndSt "ENM";
BA_ "SignalLongName" SG_ 979 PltfrmEngSpdCmmndSt "Platform Engine Speed Command Status";
BA_ "VNSigAllNodes" SG_ 979 EngManfldAirTempCrtd 1;
BA_ "SignalType" SG_ 979 EngManfldAirTempCrtd "UNM";
BA_ "SignalLongName" SG_ 979 EngManfldAirTempCrtd "Engine Manifold Air Temperature Corrected";
BA_ "VNSigAllNodes" SG_ 647 CrnksftTqModRspMxCapV 1;
BA_ "SignalType" SG_ 647 CrnksftTqModRspMxCapV "ENM";
BA_ "SignalLongName" SG_ 647 CrnksftTqModRspMxCapV "Crankshaft Torque Moderate Response Maximum Capacity Validity";
BA_ "VNSigAllNodes" SG_ 647 CrnksftTqModRspMxCap 1;
BA_ "SignalType" SG_ 647 CrnksftTqModRspMxCap "UNM";
BA_ "SignalLongName" SG_ 647 CrnksftTqModRspMxCap "Crankshaft Torque Moderate Response Maximum Capacity";
BA_ "VNSigAllNodes" SG_ 647 EngDetPndTrnCsRngShfV 1;
BA_ "SignalType" SG_ 647 EngDetPndTrnCsRngShfV "ENM";
BA_ "SignalLongName" SG_ 647 EngDetPndTrnCsRngShfV "Engine Determined Pending Transfer Case Range Shift Validity";
BA_ "VNSigAllNodes" SG_ 647 EngDetPndTrnCsRngShf 1;
BA_ "SignalType" SG_ 647 EngDetPndTrnCsRngShf "ENM";
BA_ "SignalLongName" SG_ 647 EngDetPndTrnCsRngShf "Engine Determined Pending Transfer Case Range Shift";
BA_ "VNSigAllNodes" SG_ 647 CrpCstCrvCmd 1;
BA_ "SignalType" SG_ 647 CrpCstCrvCmd "ENM";
BA_ "SignalLongName" SG_ 647 CrpCstCrvCmd "Creep Coast Curve Commanded";
BA_ "VNSigAllNodes" SG_ 647 DrvMntnMdCmnd 1;
BA_ "SignalType" SG_ 647 DrvMntnMdCmnd "BLN";
BA_ "SignalLongName" SG_ 647 DrvMntnMdCmnd "Driver Mountain Mode Commanded";
BA_ "VNSigAllNodes" SG_ 647 DrvHldMdCmnd 1;
BA_ "SignalType" SG_ 647 DrvHldMdCmnd "BLN";
BA_ "SignalLongName" SG_ 647 DrvHldMdCmnd "Driver Hold Mode Commanded";
BA_ "VNSigAllNodes" SG_ 647 DrPTGrdBrkDsbMdCmd 1;
BA_ "SignalType" SG_ 647 DrPTGrdBrkDsbMdCmd "BLN";
BA_ "SignalLongName" SG_ 647 DrPTGrdBrkDsbMdCmd "Driver Powertrain Grade Braking Disable Mode Commanded";
BA_ "VNSigAllNodes" SG_ 647 DrvWntrMdCmd 1;
BA_ "SignalType" SG_ 647 DrvWntrMdCmd "BLN";
BA_ "SignalLongName" SG_ 647 DrvWntrMdCmd "Driver Winter Mode Commanded";
BA_ "VNSigAllNodes" SG_ 647 DrvTwHaulMdCmd 1;
BA_ "SignalType" SG_ 647 DrvTwHaulMdCmd "BLN";
BA_ "SignalLongName" SG_ 647 DrvTwHaulMdCmd "Driver Tow Haul Mode Commanded";
BA_ "VNSigAllNodes" SG_ 647 DrvSprtMdCmd 1;
BA_ "SignalType" SG_ 647 DrvSprtMdCmd "BLN";
BA_ "SignalLongName" SG_ 647 DrvSprtMdCmd "Driver Sport Mode Commanded";
BA_ "VNSigAllNodes" SG_ 647 DrvEconMdCmd 1;
BA_ "SignalType" SG_ 647 DrvEconMdCmd "BLN";
BA_ "SignalLongName" SG_ 647 DrvEconMdCmd "Driver Economy Mode Commanded";
BA_ "VNSigAllNodes" SG_ 647 EngCntrlDtrmdTrfCRngV 1;
BA_ "SignalType" SG_ 647 EngCntrlDtrmdTrfCRngV "ENM";
BA_ "SignalLongName" SG_ 647 EngCntrlDtrmdTrfCRngV "Engine Controller Determined Transfer Case Range Validity";
BA_ "VNSigAllNodes" SG_ 647 EngCntrlDtrmdTrfCRng 1;
BA_ "SignalType" SG_ 647 EngCntrlDtrmdTrfCRng "ENM";
BA_ "SignalLongName" SG_ 647 EngCntrlDtrmdTrfCRng "Engine Controller Determined Transfer Case Range";
BA_ "VNSigAllNodes" SG_ 647 EngCtrlUtldTrnCRgPVal 1;
BA_ "SignalType" SG_ 647 EngCtrlUtldTrnCRgPVal "UNM";
BA_ "SignalLongName" SG_ 647 EngCtrlUtldTrnCRgPVal "Engine Controller Utilized Transfer Case Range Protection Value";
BA_ "VNSigAllNodes" SG_ 647 EngCntrlUtldTrnCsRng 1;
BA_ "SignalType" SG_ 647 EngCntrlUtldTrnCsRng "ENM";
BA_ "SignalLongName" SG_ 647 EngCntrlUtldTrnCsRng "Engine Controller Utilized Transfer Case Range";
BA_ "VNSigAllNodes" SG_ 647 EngCntrlUtldTrnCsRgIn 1;
BA_ "SignalType" SG_ 647 EngCntrlUtldTrnCsRgIn "BLN";
BA_ "SignalLongName" SG_ 647 EngCntrlUtldTrnCsRgIn "Engine Controller Utilized Transfer Case Range Inconsistent";
BA_ "VNSigAllNodes" SG_ 647 EngCtrlUtldTrnCRgARC 1;
BA_ "SignalType" SG_ 647 EngCtrlUtldTrnCRgARC "UNM";
BA_ "SignalLongName" SG_ 647 EngCtrlUtldTrnCRgARC "Engine Controller Utilized Transfer Case Range Alive Rolling Count";
BA_ "VNSigAllNodes" SG_ 1187 UndrHdAirFlwCap 1;
BA_ "SignalType" SG_ 1187 UndrHdAirFlwCap "UNM";
BA_ "SignalLongName" SG_ 1187 UndrHdAirFlwCap "Under Hood Air Flow Capacity";
BA_ "VNSigAllNodes" SG_ 1187 UndrHdAirFlwActPrcnt 1;
BA_ "SignalType" SG_ 1187 UndrHdAirFlwActPrcnt "UNM";
BA_ "SignalLongName" SG_ 1187 UndrHdAirFlwActPrcnt "Under Hood Air Flow Actual Percent";
BA_ "VNSigAllNodes" SG_ 1187 VehGrdSnsrBsdV 1;
BA_ "SignalType" SG_ 1187 VehGrdSnsrBsdV "ENM";
BA_ "SignalLongName" SG_ 1187 VehGrdSnsrBsdV "Vehicle Grade Sensor Based Validity";
BA_ "VNSigAllNodes" SG_ 1187 VehGrdSnsrBsd 1;
BA_ "SignalType" SG_ 1187 VehGrdSnsrBsd "SNM";
BA_ "SignalLongName" SG_ 1187 VehGrdSnsrBsd "Vehicle Grade Sensor Based";
BA_ "VNSigAllNodes" SG_ 487 CmmndAirFuelRatio 1;
BA_ "SignalType" SG_ 487 CmmndAirFuelRatio "UNM";
BA_ "SignalLongName" SG_ 487 CmmndAirFuelRatio "Commanded Air Fuel Ratio";
BA_ "VNSigAllNodes" SG_ 487 InstFuelFlowEst 1;
BA_ "SignalType" SG_ 487 InstFuelFlowEst "UNM";
BA_ "SignalLongName" SG_ 487 InstFuelFlowEst "Instantaneous Fuel Flow Estimate";
BA_ "VNSigAllNodes" SG_ 487 FuelDelPressRqd 1;
BA_ "SignalType" SG_ 487 FuelDelPressRqd "UNM";
BA_ "SignalLongName" SG_ 487 FuelDelPressRqd "Fuel Delivery Pressure Requested";
BA_ "VNSigAllNodes" SG_ 487 EngRunng 1;
BA_ "SignalType" SG_ 487 EngRunng "BLN";
BA_ "SignalLongName" SG_ 487 EngRunng "Engine Running";
BA_ "VNSigAllNodes" SG_ 487 FlPmpEDscOtptCmdSta 1;
BA_ "SignalType" SG_ 487 FlPmpEDscOtptCmdSta "ENM";
BA_ "SignalLongName" SG_ 487 FlPmpEDscOtptCmdSta "Fuel Pump Enabled Discrete Output Commanded Status";
BA_ "VNSigAllNodes" SG_ 487 FuelCntlSysFltPrsnt 1;
BA_ "SignalType" SG_ 487 FuelCntlSysFltPrsnt "BLN";
BA_ "SignalLongName" SG_ 487 FuelCntlSysFltPrsnt "Fuel Control System Fault Present";
BA_ "VNSigAllNodes" SG_ 487 HiPresFuelPmpDelDur 1;
BA_ "SignalType" SG_ 487 HiPresFuelPmpDelDur "UNM";
BA_ "SignalLongName" SG_ 487 HiPresFuelPmpDelDur "High Pressure Fuel Pump Delivery Duration";
BA_ "VNSigAllNodes" SG_ 487 HiPresFuelPmpCntMd 1;
BA_ "SignalType" SG_ 487 HiPresFuelPmpCntMd "ENM";
BA_ "SignalLongName" SG_ 487 HiPresFuelPmpCntMd "High Pressure Fuel Pump Control Mode";
BA_ "VNSigAllNodes" SG_ 398 EngNTrnsRegStdyStTqV 1;
BA_ "SignalType" SG_ 398 EngNTrnsRegStdyStTqV "ENM";
BA_ "SignalLongName" SG_ 398 EngNTrnsRegStdyStTqV "Engine Non-Transmission Regulated Steady State Torque Validity";
BA_ "VNSigAllNodes" SG_ 398 EngNTrnsRegStdyStTq 1;
BA_ "SignalType" SG_ 398 EngNTrnsRegStdyStTq "UNM";
BA_ "SignalLongName" SG_ 398 EngNTrnsRegStdyStTq "Engine Non-Transmission Regulated Steady State Torque";
BA_ "VNSigAllNodes" SG_ 398 EngActStdyStTorq 1;
BA_ "SignalType" SG_ 398 EngActStdyStTorq "UNM";
BA_ "SignalLongName" SG_ 398 EngActStdyStTorq "Engine Actual Steady State Torque";
BA_ "VNSigAllNodes" SG_ 398 AccKdwnAtv 1;
BA_ "SignalType" SG_ 398 AccKdwnAtv "BLN";
BA_ "SignalLongName" SG_ 398 AccKdwnAtv "Accelerator Kick Down Detected";
BA_ "VNSigAllNodes" SG_ 398 EngActStdyStTorqV 1;
BA_ "SignalType" SG_ 398 EngActStdyStTorqV "ENM";
BA_ "SignalLongName" SG_ 398 EngActStdyStTorqV "Engine Actual Steady State Torque Validity";
BA_ "VNSigAllNodes" SG_ 398 TrnsEngSpdReqFld 1;
BA_ "SignalType" SG_ 398 TrnsEngSpdReqFld "BLN";
BA_ "SignalLongName" SG_ 398 TrnsEngSpdReqFld "Transmission Engine Speed Request Failed";
BA_ "VNSigAllNodes" SG_ 398 PTACCAct 1;
BA_ "SignalType" SG_ 398 PTACCAct "BLN";
BA_ "SignalLongName" SG_ 398 PTACCAct "Powertrain Adaptive Cruise Control Active";
BA_ "VNSigAllNodes" SG_ 398 CTSS_StbltyLvl 1;
BA_ "SignalType" SG_ 398 CTSS_StbltyLvl "ENM";
BA_ "PacketOrder" SG_ 398 CTSS_StbltyLvl 2;
BA_ "SignalLongName" SG_ 398 CTSS_StbltyLvl "Crankshaft Torque Stability Status : Stability Level";
BA_ "VNSigAllNodes" SG_ 398 CTSS_StbltyTyp 1;
BA_ "SignalType" SG_ 398 CTSS_StbltyTyp "ENM";
BA_ "PacketOrder" SG_ 398 CTSS_StbltyTyp 1;
BA_ "SignalLongName" SG_ 398 CTSS_StbltyTyp "Crankshaft Torque Stability Status : Stability Type";
BA_ "VNSigAllNodes" SG_ 398 CrksftNTrnsRegCmdTq 1;
BA_ "SignalType" SG_ 398 CrksftNTrnsRegCmdTq "UNM";
BA_ "SignalLongName" SG_ 398 CrksftNTrnsRegCmdTq "Crankshaft Non-Transmission Regulated Commanded Torque";
BA_ "VNSigAllNodes" SG_ 398 EngImmTrqTnsRqStat 1;
BA_ "SignalType" SG_ 398 EngImmTrqTnsRqStat "ENM";
BA_ "SignalLongName" SG_ 398 EngImmTrqTnsRqStat "Engine Immediate Torque Transmission Request Status";
BA_ "VNSigAllNodes" SG_ 398 EngImmTrqTnsRqLmSt 1;
BA_ "SignalType" SG_ 398 EngImmTrqTnsRqLmSt "ENM";
BA_ "SignalLongName" SG_ 398 EngImmTrqTnsRqLmSt "Engine Immediate Torque Transmission Request Limiting Status";
BA_ "VNSigAllNodes" SG_ 398 EngPrdctTrqTnsRqStat 1;
BA_ "SignalType" SG_ 398 EngPrdctTrqTnsRqStat "ENM";
BA_ "SignalLongName" SG_ 398 EngPrdctTrqTnsRqStat "Engine Predicted Torque Transmission Request Status";
BA_ "VNSigAllNodes" SG_ 398 EngPrdctTrqTnsRqLmS 1;
BA_ "SignalType" SG_ 398 EngPrdctTrqTnsRqLmS "ENM";
BA_ "SignalLongName" SG_ 398 EngPrdctTrqTnsRqLmS "Engine Predicted Torque Transmission Request Limiting Status";
BA_REL_ "GenSigSuprvResp" BU_SG_REL_ BCM_HS SG_ 565 PerfMdMainMenuType 1;
BA_REL_ "GenSigTimeoutMsg" BU_SG_REL_ BCM_HS SG_ 565 PerfMdMainMenuType 565;
BA_REL_ "GenSigTimeoutTime" BU_SG_REL_ BCM_HS SG_ 565 PerfMdMainMenuType 5000;
BA_REL_ "GenSigSuprvResp" BU_SG_REL_ BCM_HS SG_ 565 PSPMCA_PsngStPrfMd6Avl 1;
BA_REL_ "GenSigTimeoutMsg" BU_SG_REL_ BCM_HS SG_ 565 PSPMCA_PsngStPrfMd6Avl 565;
BA_REL_ "GenSigTimeoutTime" BU_SG_REL_ BCM_HS SG_ 565 PSPMCA_PsngStPrfMd6Avl 5000;
BA_REL_ "GenSigSuprvResp" BU_SG_REL_ BCM_HS SG_ 565 PSPMCA_PsngStPrfMd5Avl 1;
BA_REL_ "GenSigTimeoutMsg" BU_SG_REL_ BCM_HS SG_ 565 PSPMCA_PsngStPrfMd5Avl 565;
BA_REL_ "GenSigTimeoutTime" BU_SG_REL_ BCM_HS SG_ 565 PSPMCA_PsngStPrfMd5Avl 5000;
BA_REL_ "GenSigSuprvResp" BU_SG_REL_ BCM_HS SG_ 565 PSPMCA_PsngStPrfMd4Avl 1;
BA_REL_ "GenSigTimeoutMsg" BU_SG_REL_ BCM_HS SG_ 565 PSPMCA_PsngStPrfMd4Avl 565;
BA_REL_ "GenSigTimeoutTime" BU_SG_REL_ BCM_HS SG_ 565 PSPMCA_PsngStPrfMd4Avl 5000;
BA_REL_ "GenSigSuprvResp" BU_SG_REL_ BCM_HS SG_ 565 PSPMCA_PsngStPrfMd3Avl 1;
BA_REL_ "GenSigTimeoutMsg" BU_SG_REL_ BCM_HS SG_ 565 PSPMCA_PsngStPrfMd3Avl 565;
BA_REL_ "GenSigTimeoutTime" BU_SG_REL_ BCM_HS SG_ 565 PSPMCA_PsngStPrfMd3Avl 5000;
BA_REL_ "GenSigSuprvResp" BU_SG_REL_ BCM_HS SG_ 565 PSPMCA_PsngStPrfMd2Avl 1;
BA_REL_ "GenSigTimeoutMsg" BU_SG_REL_ BCM_HS SG_ 565 PSPMCA_PsngStPrfMd2Avl 565;
BA_REL_ "GenSigTimeoutTime" BU_SG_REL_ BCM_HS SG_ 565 PSPMCA_PsngStPrfMd2Avl 5000;
BA_REL_ "GenSigSuprvResp" BU_SG_REL_ BCM_HS SG_ 565 PSPMCA_PsngStPrfMd1Avl 1;
BA_REL_ "GenSigTimeoutMsg" BU_SG_REL_ BCM_HS SG_ 565 PSPMCA_PsngStPrfMd1Avl 565;
BA_REL_ "GenSigTimeoutTime" BU_SG_REL_ BCM_HS SG_ 565 PSPMCA_PsngStPrfMd1Avl 5000;
BA_REL_ "GenSigSuprvResp" BU_SG_REL_ BCM_HS SG_ 565 DSPMCA_DrvStyPrfMd7Avl 1;
BA_REL_ "GenSigTimeoutMsg" BU_SG_REL_ BCM_HS SG_ 565 DSPMCA_DrvStyPrfMd7Avl 565;
BA_REL_ "GenSigTimeoutTime" BU_SG_REL_ BCM_HS SG_ 565 DSPMCA_DrvStyPrfMd7Avl 5000;
BA_REL_ "GenSigSuprvResp" BU_SG_REL_ BCM_HS SG_ 565 DSPMCA_DrvStyPrfMd6Avl 1;
BA_REL_ "GenSigTimeoutMsg" BU_SG_REL_ BCM_HS SG_ 565 DSPMCA_DrvStyPrfMd6Avl 565;
BA_REL_ "GenSigTimeoutTime" BU_SG_REL_ BCM_HS SG_ 565 DSPMCA_DrvStyPrfMd6Avl 5000;
BA_REL_ "GenSigSuprvResp" BU_SG_REL_ BCM_HS SG_ 565 DSPMCA_DrvStyPrfMd5Avl 1;
BA_REL_ "GenSigTimeoutMsg" BU_SG_REL_ BCM_HS SG_ 565 DSPMCA_DrvStyPrfMd5Avl 565;
BA_REL_ "GenSigTimeoutTime" BU_SG_REL_ BCM_HS SG_ 565 DSPMCA_DrvStyPrfMd5Avl 5000;
BA_REL_ "GenSigSuprvResp" BU_SG_REL_ BCM_HS SG_ 565 DSPMCA_DrvStyPrfMd4Avl 1;
BA_REL_ "GenSigTimeoutMsg" BU_SG_REL_ BCM_HS SG_ 565 DSPMCA_DrvStyPrfMd4Avl 565;
BA_REL_ "GenSigTimeoutTime" BU_SG_REL_ BCM_HS SG_ 565 DSPMCA_DrvStyPrfMd4Avl 5000;
BA_REL_ "GenSigSuprvResp" BU_SG_REL_ BCM_HS SG_ 565 DSPMCA_DrvStyPrfMd3Avl 1;
BA_REL_ "GenSigTimeoutMsg" BU_SG_REL_ BCM_HS SG_ 565 DSPMCA_DrvStyPrfMd3Avl 565;
BA_REL_ "GenSigTimeoutTime" BU_SG_REL_ BCM_HS SG_ 565 DSPMCA_DrvStyPrfMd3Avl 5000;
BA_REL_ "GenSigSuprvResp" BU_SG_REL_ BCM_HS SG_ 565 DSPMCA_DrvStyPrfMd2Avl 1;
BA_REL_ "GenSigTimeoutMsg" BU_SG_REL_ BCM_HS SG_ 565 DSPMCA_DrvStyPrfMd2Avl 565;
BA_REL_ "GenSigTimeoutTime" BU_SG_REL_ BCM_HS SG_ 565 DSPMCA_DrvStyPrfMd2Avl 5000;
BA_REL_ "GenSigSuprvResp" BU_SG_REL_ BCM_HS SG_ 565 DSPMCA_DrvStyPrfMd1Avl 1;
BA_REL_ "GenSigTimeoutMsg" BU_SG_REL_ BCM_HS SG_ 565 DSPMCA_DrvStyPrfMd1Avl 565;
BA_REL_ "GenSigTimeoutTime" BU_SG_REL_ BCM_HS SG_ 565 DSPMCA_DrvStyPrfMd1Avl 5000;
BA_REL_ "GenSigSuprvResp" BU_SG_REL_ BCM_HS SG_ 565 DSPMCA_DrvrStPrfMd6Avl 1;
BA_REL_ "GenSigTimeoutMsg" BU_SG_REL_ BCM_HS SG_ 565 DSPMCA_DrvrStPrfMd6Avl 565;
BA_REL_ "GenSigTimeoutTime" BU_SG_REL_ BCM_HS SG_ 565 DSPMCA_DrvrStPrfMd6Avl 5000;
BA_REL_ "GenSigSuprvResp" BU_SG_REL_ BCM_HS SG_ 565 DSPMCA_DrvrStPrfMd5Avl 1;
BA_REL_ "GenSigTimeoutMsg" BU_SG_REL_ BCM_HS SG_ 565 DSPMCA_DrvrStPrfMd5Avl 565;
BA_REL_ "GenSigTimeoutTime" BU_SG_REL_ BCM_HS SG_ 565 DSPMCA_DrvrStPrfMd5Avl 5000;
BA_REL_ "GenSigSuprvResp" BU_SG_REL_ BCM_HS SG_ 565 DSPMCA_DrvrStPrfMd4Avl 1;
BA_REL_ "GenSigTimeoutMsg" BU_SG_REL_ BCM_HS SG_ 565 DSPMCA_DrvrStPrfMd4Avl 565;
BA_REL_ "GenSigTimeoutTime" BU_SG_REL_ BCM_HS SG_ 565 DSPMCA_DrvrStPrfMd4Avl 5000;
BA_REL_ "GenSigSuprvResp" BU_SG_REL_ BCM_HS SG_ 565 DSPMCA_DrvrStPrfMd3Avl 1;
BA_REL_ "GenSigTimeoutMsg" BU_SG_REL_ BCM_HS SG_ 565 DSPMCA_DrvrStPrfMd3Avl 565;
BA_REL_ "GenSigTimeoutTime" BU_SG_REL_ BCM_HS SG_ 565 DSPMCA_DrvrStPrfMd3Avl 5000;
BA_REL_ "GenSigSuprvResp" BU_SG_REL_ BCM_HS SG_ 565 DSPMCA_DrvrStPrfMd2Avl 1;
BA_REL_ "GenSigTimeoutMsg" BU_SG_REL_ BCM_HS SG_ 565 DSPMCA_DrvrStPrfMd2Avl 565;
BA_REL_ "GenSigTimeoutTime" BU_SG_REL_ BCM_HS SG_ 565 DSPMCA_DrvrStPrfMd2Avl 5000;
BA_REL_ "GenSigSuprvResp" BU_SG_REL_ BCM_HS SG_ 565 DSPMCA_DrvrStPrfMd1Avl 1;
BA_REL_ "GenSigTimeoutMsg" BU_SG_REL_ BCM_HS SG_ 565 DSPMCA_DrvrStPrfMd1Avl 565;
BA_REL_ "GenSigTimeoutTime" BU_SG_REL_ BCM_HS SG_ 565 DSPMCA_DrvrStPrfMd1Avl 5000;
BA_REL_ "GenSigSuprvResp" BU_SG_REL_ BCM_HS SG_ 565 ACCPMCA_ACCPrfMd6Avl 1;
BA_REL_ "GenSigTimeoutMsg" BU_SG_REL_ BCM_HS SG_ 565 ACCPMCA_ACCPrfMd6Avl 565;
BA_REL_ "GenSigTimeoutTime" BU_SG_REL_ BCM_HS SG_ 565 ACCPMCA_ACCPrfMd6Avl 5000;
BA_REL_ "GenSigSuprvResp" BU_SG_REL_ BCM_HS SG_ 565 ACCPMCA_ACCPrfMd5Avl 1;
BA_REL_ "GenSigTimeoutMsg" BU_SG_REL_ BCM_HS SG_ 565 ACCPMCA_ACCPrfMd5Avl 565;
BA_REL_ "GenSigTimeoutTime" BU_SG_REL_ BCM_HS SG_ 565 ACCPMCA_ACCPrfMd5Avl 5000;
BA_REL_ "GenSigSuprvResp" BU_SG_REL_ BCM_HS SG_ 565 ACCPMCA_ACCPrfMd4Avl 1;
BA_REL_ "GenSigTimeoutMsg" BU_SG_REL_ BCM_HS SG_ 565 ACCPMCA_ACCPrfMd4Avl 565;
BA_REL_ "GenSigTimeoutTime" BU_SG_REL_ BCM_HS SG_ 565 ACCPMCA_ACCPrfMd4Avl 5000;
BA_REL_ "GenSigSuprvResp" BU_SG_REL_ BCM_HS SG_ 565 ACCPMCA_ACCPrfMd3Avl 1;
BA_REL_ "GenSigTimeoutMsg" BU_SG_REL_ BCM_HS SG_ 565 ACCPMCA_ACCPrfMd3Avl 565;
BA_REL_ "GenSigTimeoutTime" BU_SG_REL_ BCM_HS SG_ 565 ACCPMCA_ACCPrfMd3Avl 5000;
BA_REL_ "GenSigSuprvResp" BU_SG_REL_ BCM_HS SG_ 565 ACCPMCA_ACCPrfMd2Avl 1;
BA_REL_ "GenSigTimeoutMsg" BU_SG_REL_ BCM_HS SG_ 565 ACCPMCA_ACCPrfMd2Avl 565;
BA_REL_ "GenSigTimeoutTime" BU_SG_REL_ BCM_HS SG_ 565 ACCPMCA_ACCPrfMd2Avl 5000;
BA_REL_ "GenSigSuprvResp" BU_SG_REL_ BCM_HS SG_ 565 ACCPMCA_ACCPrfMd1Avl 1;
BA_REL_ "GenSigTimeoutMsg" BU_SG_REL_ BCM_HS SG_ 565 ACCPMCA_ACCPrfMd1Avl 565;
BA_REL_ "GenSigTimeoutTime" BU_SG_REL_ BCM_HS SG_ 565 ACCPMCA_ACCPrfMd1Avl 5000;
BA_REL_ "GenSigSuprvResp" BU_SG_REL_ BCM_HS SG_ 882 AdvFrntLghtSysHiBmIO 1;
BA_REL_ "GenSigTimeoutMsg" BU_SG_REL_ BCM_HS SG_ 882 AdvFrntLghtSysHiBmIO 882;
BA_REL_ "GenSigTimeoutTime" BU_SG_REL_ BCM_HS SG_ 882 AdvFrntLghtSysHiBmIO 250;
BA_REL_ "GenSigSuprvResp" BU_SG_REL_ BCM_HS SG_ 817 RrAxlELSDCplLwRes 1;
BA_REL_ "GenSigTimeoutMsg" BU_SG_REL_ BCM_HS SG_ 817 RrAxlELSDCplLwRes 817;
BA_REL_ "GenSigTimeoutTime" BU_SG_REL_ BCM_HS SG_ 817 RrAxlELSDCplLwRes 250;
BA_REL_ "GenSigSuprvResp" BU_SG_REL_ BCM_HS SG_ 817 RrDrvlnSysVehTpSpdLmVal 2;
BA_REL_ "GenSigSuprvRespSubValue" BU_SG_REL_ BCM_HS SG_ 817 RrDrvlnSysVehTpSpdLmVal 255;
BA_REL_ "GenSigTimeoutMsg" BU_SG_REL_ BCM_HS SG_ 817 RrDrvlnSysVehTpSpdLmVal 817;
BA_REL_ "GenSigTimeoutTime" BU_SG_REL_ BCM_HS SG_ 817 RrDrvlnSysVehTpSpdLmVal 500;
BA_REL_ "GenSigSuprvResp" BU_SG_REL_ BCM_HS SG_ 817 RrAxlMalfIO 1;
BA_REL_ "GenSigTimeoutMsg" BU_SG_REL_ BCM_HS SG_ 817 RrAxlMalfIO 817;
BA_REL_ "GenSigTimeoutTime" BU_SG_REL_ BCM_HS SG_ 817 RrAxlMalfIO 250;
BA_REL_ "GenSigSuprvResp" BU_SG_REL_ BCM_HS SG_ 853 SrvPedtrnProtSysIO 1;
BA_REL_ "GenSigTimeoutMsg" BU_SG_REL_ BCM_HS SG_ 853 SrvPedtrnProtSysIO 853;
BA_REL_ "GenSigTimeoutTime" BU_SG_REL_ BCM_HS SG_ 853 SrvPedtrnProtSysIO 2500;
BA_REL_ "GenSigSuprvResp" BU_SG_REL_ BCM_HS SG_ 869 FwdClnMtgnBrkReqAct 1;
BA_REL_ "GenSigTimeoutMsg" BU_SG_REL_ BCM_HS SG_ 869 FwdClnMtgnBrkReqAct 869;
BA_REL_ "GenSigTimeoutTime" BU_SG_REL_ BCM_HS SG_ 869 FwdClnMtgnBrkReqAct 250;
BA_REL_ "GenSigSuprvResp" BU_SG_REL_ BCM_HS SG_ 869 FCACustStngAvlbl 1;
BA_REL_ "GenSigTimeoutTime" BU_SG_REL_ BCM_HS SG_ 869 FCACustStngAvlbl 250;
BA_REL_ "GenSigSuprvResp" BU_SG_REL_ BCM_HS SG_ 869 FwdClnAlrtCustCrntSetngVal 1;
BA_REL_ "GenSigTimeoutTime" BU_SG_REL_ BCM_HS SG_ 869 FwdClnAlrtCustCrntSetngVal 250;
BA_REL_ "GenSigSuprvResp" BU_SG_REL_ BCM_HS SG_ 869 GNCustSetngAvlbl 1;
BA_REL_ "GenSigTimeoutTime" BU_SG_REL_ BCM_HS SG_ 869 GNCustSetngAvlbl 250;
BA_REL_ "GenSigSuprvResp" BU_SG_REL_ BCM_HS SG_ 869 CPSUnblIO 1;
BA_REL_ "GenSigTimeoutTime" BU_SG_REL_ BCM_HS SG_ 869 CPSUnblIO 250;
BA_REL_ "GenSigSuprvResp" BU_SG_REL_ BCM_HS SG_ 869 ColPrSysStngAvl 1;
BA_REL_ "GenSigTimeoutTime" BU_SG_REL_ BCM_HS SG_ 869 ColPrSysStngAvl 250;
BA_REL_ "GenSigSuprvResp" BU_SG_REL_ BCM_HS SG_ 869 CPSOffIO 1;
BA_REL_ "GenSigTimeoutTime" BU_SG_REL_ BCM_HS SG_ 869 CPSOffIO 250;
BA_REL_ "GenSigSuprvResp" BU_SG_REL_ BCM_HS SG_ 869 CPSFldIO 1;
BA_REL_ "GenSigTimeoutTime" BU_SG_REL_ BCM_HS SG_ 869 CPSFldIO 250;
BA_REL_ "GenSigSuprvResp" BU_SG_REL_ BCM_HS SG_ 869 ColPrSysCrntStng 1;
BA_REL_ "GenSigTimeoutTime" BU_SG_REL_ BCM_HS SG_ 869 ColPrSysCrntStng 250;
BA_REL_ "GenSigSuprvResp" BU_SG_REL_ BCM_HS SG_ 869 CPSAlrtOnlIO 1;
BA_REL_ "GenSigTimeoutTime" BU_SG_REL_ BCM_HS SG_ 869 CPSAlrtOnlIO 250;
BA_REL_ "GenSigSuprvResp" BU_SG_REL_ BCM_HS SG_ 869 GNCustCrntStngVal 1;
BA_REL_ "GenSigTimeoutTime" BU_SG_REL_ BCM_HS SG_ 869 GNCustCrntStngVal 250;
BA_REL_ "GenSigSuprvResp" BU_SG_REL_ BCM_HS SG_ 564 AdptDrvrSeatStng 1;
BA_REL_ "GenSigTimeoutMsg" BU_SG_REL_ BCM_HS SG_ 564 AdptDrvrSeatStng 564;
BA_REL_ "GenSigTimeoutTime" BU_SG_REL_ BCM_HS SG_ 564 AdptDrvrSeatStng 250;
BA_REL_ "GenSigSuprvResp" BU_SG_REL_ BCM_HS SG_ 564 AdptPsngrSeatStng 1;
BA_REL_ "GenSigTimeoutMsg" BU_SG_REL_ BCM_HS SG_ 564 AdptPsngrSeatStng 564;
BA_REL_ "GenSigTimeoutTime" BU_SG_REL_ BCM_HS SG_ 564 AdptPsngrSeatStng 250;
BA_REL_ "GenSigSuprvResp" BU_SG_REL_ BCM_HS SG_ 564 TnDrvTrCtrlOffUnbIO 1;
BA_REL_ "GenSigTimeoutMsg" BU_SG_REL_ BCM_HS SG_ 564 TnDrvTrCtrlOffUnbIO 564;
BA_REL_ "GenSigTimeoutTime" BU_SG_REL_ BCM_HS SG_ 564 TnDrvTrCtrlOffUnbIO 250;
BA_REL_ "GenSigSuprvResp" BU_SG_REL_ BCM_HS SG_ 564 TnDrvStblCtrlOffUnbIO 1;
BA_REL_ "GenSigTimeoutMsg" BU_SG_REL_ BCM_HS SG_ 564 TnDrvStblCtrlOffUnbIO 564;
BA_REL_ "GenSigTimeoutTime" BU_SG_REL_ BCM_HS SG_ 564 TnDrvStblCtrlOffUnbIO 250;
BA_REL_ "GenSigSuprvResp" BU_SG_REL_ BCM_HS SG_ 564 TrlrStabAstActIO 1;
BA_REL_ "GenSigTimeoutMsg" BU_SG_REL_ BCM_HS SG_ 564 TrlrStabAstActIO 564;
BA_REL_ "GenSigTimeoutTime" BU_SG_REL_ BCM_HS SG_ 564 TrlrStabAstActIO 250;
BA_REL_ "GenSigSuprvResp" BU_SG_REL_ BCM_HS SG_ 1296 ACCAutoSetSpdStat 1;
BA_REL_ "GenSigTimeoutMsg" BU_SG_REL_ BCM_HS SG_ 1296 ACCAutoSetSpdStat 1296;
BA_REL_ "GenSigTimeoutTime" BU_SG_REL_ BCM_HS SG_ 1296 ACCAutoSetSpdStat 250;
BA_REL_ "GenSigSuprvResp" BU_SG_REL_ BCM_HS SG_ 536 ACCHptcStVbnRqSeqN 1;
BA_REL_ "GenSigTimeoutMsg" BU_SG_REL_ BCM_HS SG_ 536 ACCHptcStVbnRqSeqN 536;
BA_REL_ "GenSigTimeoutTime" BU_SG_REL_ BCM_HS SG_ 536 ACCHptcStVbnRqSeqN 500;
BA_REL_ "GenSigSuprvResp" BU_SG_REL_ BCM_HS SG_ 536 ACCHptcStVbnReq 1;
BA_REL_ "GenSigTimeoutMsg" BU_SG_REL_ BCM_HS SG_ 536 ACCHptcStVbnReq 536;
BA_REL_ "GenSigTimeoutTime" BU_SG_REL_ BCM_HS SG_ 536 ACCHptcStVbnReq 500;
BA_REL_ "GenSigSuprvResp" BU_SG_REL_ EBCM_OBD_HS SG_ 848 TrlrBrkngGainSet 1;
BA_REL_ "GenSigTimeoutMsg" BU_SG_REL_ EBCM_OBD_HS SG_ 848 TrlrBrkngGainSet 848;
BA_REL_ "GenSigTimeoutTime" BU_SG_REL_ EBCM_OBD_HS SG_ 848 TrlrBrkngGainSet 250;
BA_REL_ "GenSigSuprvResp" BU_SG_REL_ EBCM_HS SG_ 848 TrlrBrkngGainSet 1;
BA_REL_ "GenSigTimeoutMsg" BU_SG_REL_ EBCM_HS SG_ 848 TrlrBrkngGainSet 848;
BA_REL_ "GenSigTimeoutTime" BU_SG_REL_ EBCM_HS SG_ 848 TrlrBrkngGainSet 250;
BA_REL_ "GenSigSuprvResp" BU_SG_REL_ EBCM_OBD_HS SG_ 848 TrlrBrkngFrcOtpt 1;
BA_REL_ "GenSigTimeoutMsg" BU_SG_REL_ EBCM_OBD_HS SG_ 848 TrlrBrkngFrcOtpt 848;
BA_REL_ "GenSigTimeoutTime" BU_SG_REL_ EBCM_OBD_HS SG_ 848 TrlrBrkngFrcOtpt 250;
BA_REL_ "GenSigSuprvResp" BU_SG_REL_ EBCM_HS SG_ 848 TrlrBrkngFrcOtpt 1;
BA_REL_ "GenSigTimeoutMsg" BU_SG_REL_ EBCM_HS SG_ 848 TrlrBrkngFrcOtpt 848;
BA_REL_ "GenSigTimeoutTime" BU_SG_REL_ EBCM_HS SG_ 848 TrlrBrkngFrcOtpt 250;
BA_REL_ "GenSigSuprvResp" BU_SG_REL_ BCM_HS SG_ 848 TrlrHtchSwAtv_ITBC 1;
BA_REL_ "GenSigTimeoutMsg" BU_SG_REL_ BCM_HS SG_ 848 TrlrHtchSwAtv_ITBC 848;
BA_REL_ "GenSigTimeoutTime" BU_SG_REL_ BCM_HS SG_ 848 TrlrHtchSwAtv_ITBC 250;
BA_REL_ "GenSigSuprvResp" BU_SG_REL_ ONSTAR_HS SG_ 993 HybVehHiVltSysDisbld 1;
BA_REL_ "GenSigTimeoutMsg" BU_SG_REL_ ONSTAR_HS SG_ 993 HybVehHiVltSysDisbld 993;
BA_REL_ "GenSigTimeoutTime" BU_SG_REL_ ONSTAR_HS SG_ 993 HybVehHiVltSysDisbld 250;
BA_REL_ "GenSigSuprvResp" BU_SG_REL_ BCM_HS SG_ 993 SvcHybridSysIO 1;
BA_REL_ "GenSigTimeoutMsg" BU_SG_REL_ BCM_HS SG_ 993 SvcHybridSysIO 993;
BA_REL_ "GenSigTimeoutTime" BU_SG_REL_ BCM_HS SG_ 993 SvcHybridSysIO 250;
BA_REL_ "GenSigSuprvResp" BU_SG_REL_ BCM_HS SG_ 1280 TireRRLowTracIO 1;
BA_REL_ "GenSigTimeoutMsg" BU_SG_REL_ BCM_HS SG_ 1280 TireRRLowTracIO 1280;
BA_REL_ "GenSigTimeoutTime" BU_SG_REL_ BCM_HS SG_ 1280 TireRRLowTracIO 2500;
BA_REL_ "GenSigSuprvResp" BU_SG_REL_ BCM_HS SG_ 1280 TireRFLowTracIO 1;
BA_REL_ "GenSigTimeoutMsg" BU_SG_REL_ BCM_HS SG_ 1280 TireRFLowTracIO 1280;
BA_REL_ "GenSigTimeoutTime" BU_SG_REL_ BCM_HS SG_ 1280 TireRFLowTracIO 2500;
BA_REL_ "GenSigSuprvResp" BU_SG_REL_ BCM_HS SG_ 1280 TireLRLowTracIO 1;
BA_REL_ "GenSigTimeoutMsg" BU_SG_REL_ BCM_HS SG_ 1280 TireLRLowTracIO 1280;
BA_REL_ "GenSigTimeoutTime" BU_SG_REL_ BCM_HS SG_ 1280 TireLRLowTracIO 2500;
BA_REL_ "GenSigSuprvResp" BU_SG_REL_ BCM_HS SG_ 1280 TireLFLowTracIO 1;
BA_REL_ "GenSigTimeoutMsg" BU_SG_REL_ BCM_HS SG_ 1280 TireLFLowTracIO 1280;
BA_REL_ "GenSigTimeoutTime" BU_SG_REL_ BCM_HS SG_ 1280 TireLFLowTracIO 2500;
BA_REL_ "GenSigSuprvResp" BU_SG_REL_ ICCM_OBD_HS SG_ 1280 WhlRotStatTmstmpRes 1;
BA_REL_ "GenSigTimeoutMsg" BU_SG_REL_ ICCM_OBD_HS SG_ 1280 WhlRotStatTmstmpRes 1280;
BA_REL_ "GenSigTimeoutTime" BU_SG_REL_ ICCM_OBD_HS SG_ 1280 WhlRotStatTmstmpRes 2500;
BA_REL_ "GenSigSuprvResp" BU_SG_REL_ EPS_HS SG_ 1280 WhlRotStatTmstmpRes 1;
BA_REL_ "GenSigTimeoutMsg" BU_SG_REL_ EPS_HS SG_ 1280 WhlRotStatTmstmpRes 1280;
BA_REL_ "GenSigTimeoutTime" BU_SG_REL_ EPS_HS SG_ 1280 WhlRotStatTmstmpRes 2500;
BA_REL_ "GenSigSuprvResp" BU_SG_REL_ ICCM_HS SG_ 1280 WhlRotStatTmstmpRes 1;
BA_REL_ "GenSigTimeoutMsg" BU_SG_REL_ ICCM_HS SG_ 1280 WhlRotStatTmstmpRes 1280;
BA_REL_ "GenSigTimeoutTime" BU_SG_REL_ ICCM_HS SG_ 1280 WhlRotStatTmstmpRes 2500;
BA_REL_ "GenSigSuprvResp" BU_SG_REL_ TCCM_HS SG_ 1280 WhlPlsPerRevNonDrvn 1;
BA_REL_ "GenSigTimeoutMsg" BU_SG_REL_ TCCM_HS SG_ 1280 WhlPlsPerRevNonDrvn 1280;
BA_REL_ "GenSigTimeoutTime" BU_SG_REL_ TCCM_HS SG_ 1280 WhlPlsPerRevNonDrvn 2500;
BA_REL_ "GenSigSuprvResp" BU_SG_REL_ TCCM_HS SG_ 1280 WhlPlsPerRevDrvn 1;
BA_REL_ "GenSigTimeoutMsg" BU_SG_REL_ TCCM_HS SG_ 1280 WhlPlsPerRevDrvn 1280;
BA_REL_ "GenSigTimeoutTime" BU_SG_REL_ TCCM_HS SG_ 1280 WhlPlsPerRevDrvn 2500;
BA_REL_ "GenSigSuprvResp" BU_SG_REL_ ICCM_OBD_HS SG_ 562 DrvlneMntsPerfMdRq 1;
BA_REL_ "GenSigTimeoutMsg" BU_SG_REL_ ICCM_OBD_HS SG_ 562 DrvlneMntsPerfMdRq 562;
BA_REL_ "GenSigTimeoutTime" BU_SG_REL_ ICCM_OBD_HS SG_ 562 DrvlneMntsPerfMdRq 250;
BA_REL_ "GenSigSuprvResp" BU_SG_REL_ ICCM_HS SG_ 562 DrvlneMntsPerfMdRq 1;
BA_REL_ "GenSigTimeoutMsg" BU_SG_REL_ ICCM_HS SG_ 562 DrvlneMntsPerfMdRq 562;
BA_REL_ "GenSigTimeoutTime" BU_SG_REL_ ICCM_HS SG_ 562 DrvlneMntsPerfMdRq 250;
BA_REL_ "GenSigSuprvResp" BU_SG_REL_ EPS_HS SG_ 562 StgSysPerfMdRq 1;
BA_REL_ "GenSigTimeoutMsg" BU_SG_REL_ EPS_HS SG_ 562 StgSysPerfMdRq 562;
BA_REL_ "GenSigTimeoutTime" BU_SG_REL_ EPS_HS SG_ 562 StgSysPerfMdRq 250;
BA_REL_ "GenSigSuprvResp" BU_SG_REL_ ICCM_OBD_HS SG_ 562 DiffPerfMdRq 1;
BA_REL_ "GenSigTimeoutMsg" BU_SG_REL_ ICCM_OBD_HS SG_ 562 DiffPerfMdRq 562;
BA_REL_ "GenSigTimeoutTime" BU_SG_REL_ ICCM_OBD_HS SG_ 562 DiffPerfMdRq 250;
BA_REL_ "GenSigSuprvResp" BU_SG_REL_ ICCM_HS SG_ 562 DiffPerfMdRq 1;
BA_REL_ "GenSigTimeoutMsg" BU_SG_REL_ ICCM_HS SG_ 562 DiffPerfMdRq 562;
BA_REL_ "GenSigTimeoutTime" BU_SG_REL_ ICCM_HS SG_ 562 DiffPerfMdRq 250;
BA_REL_ "GenSigSuprvResp" BU_SG_REL_ ICCM_OBD_HS SG_ 562 ExhstPerfMdRq 1;
BA_REL_ "GenSigTimeoutMsg" BU_SG_REL_ ICCM_OBD_HS SG_ 562 ExhstPerfMdRq 562;
BA_REL_ "GenSigTimeoutTime" BU_SG_REL_ ICCM_OBD_HS SG_ 562 ExhstPerfMdRq 250;
BA_REL_ "GenSigSuprvResp" BU_SG_REL_ ICCM_HS SG_ 562 ExhstPerfMdRq 1;
BA_REL_ "GenSigTimeoutMsg" BU_SG_REL_ ICCM_HS SG_ 562 ExhstPerfMdRq 562;
BA_REL_ "GenSigTimeoutTime" BU_SG_REL_ ICCM_HS SG_ 562 ExhstPerfMdRq 250;
BA_REL_ "GenSigSuprvResp" BU_SG_REL_ TCCM_HS SG_ 562 AWDPerfMdRq 1;
BA_REL_ "GenSigTimeoutMsg" BU_SG_REL_ TCCM_HS SG_ 562 AWDPerfMdRq 562;
BA_REL_ "GenSigTimeoutTime" BU_SG_REL_ TCCM_HS SG_ 562 AWDPerfMdRq 250;
BA_REL_ "GenSigSuprvResp" BU_SG_REL_ BCM_HS SG_ 562 DispPerfMdCsCrStVal 1;
BA_REL_ "GenSigTimeoutMsg" BU_SG_REL_ BCM_HS SG_ 562 DispPerfMdCsCrStVal 562;
BA_REL_ "GenSigTimeoutTime" BU_SG_REL_ BCM_HS SG_ 562 DispPerfMdCsCrStVal 250;
BA_REL_ "GenSigSuprvResp" BU_SG_REL_ BCM_HS SG_ 562 SndEnhcmtPerfMdRq 1;
BA_REL_ "GenSigTimeoutMsg" BU_SG_REL_ BCM_HS SG_ 562 SndEnhcmtPerfMdRq 562;
BA_REL_ "GenSigTimeoutTime" BU_SG_REL_ BCM_HS SG_ 562 SndEnhcmtPerfMdRq 250;
BA_REL_ "GenSigSuprvResp" BU_SG_REL_ BCM_HS SG_ 562 DsplyPerfMdRq 1;
BA_REL_ "GenSigTimeoutMsg" BU_SG_REL_ BCM_HS SG_ 562 DsplyPerfMdRq 562;
BA_REL_ "GenSigTimeoutTime" BU_SG_REL_ BCM_HS SG_ 562 DsplyPerfMdRq 250;
BA_REL_ "GenSigSuprvResp" BU_SG_REL_ BCM_HS SG_ 562 SndPerfMdCsStAvl 1;
BA_REL_ "GenSigTimeoutMsg" BU_SG_REL_ BCM_HS SG_ 562 SndPerfMdCsStAvl 562;
BA_REL_ "GenSigTimeoutTime" BU_SG_REL_ BCM_HS SG_ 562 SndPerfMdCsStAvl 250;
BA_REL_ "GenSigSuprvResp" BU_SG_REL_ BCM_HS SG_ 562 SndPerfMdCsCrStVal 1;
BA_REL_ "GenSigTimeoutMsg" BU_SG_REL_ BCM_HS SG_ 562 SndPerfMdCsCrStVal 562;
BA_REL_ "GenSigTimeoutTime" BU_SG_REL_ BCM_HS SG_ 562 SndPerfMdCsCrStVal 250;
BA_REL_ "GenSigSuprvResp" BU_SG_REL_ BCM_HS SG_ 562 DispPerfMdCsStAvl 1;
BA_REL_ "GenSigTimeoutMsg" BU_SG_REL_ BCM_HS SG_ 562 DispPerfMdCsStAvl 562;
BA_REL_ "GenSigTimeoutTime" BU_SG_REL_ BCM_HS SG_ 562 DispPerfMdCsStAvl 250;
BA_REL_ "GenSigSuprvResp" BU_SG_REL_ BCM_HS SG_ 386 AHAct 1;
BA_REL_ "GenSigTimeoutMsg" BU_SG_REL_ BCM_HS SG_ 386 AHAct 386;
BA_REL_ "GenSigTimeoutTime" BU_SG_REL_ BCM_HS SG_ 386 AHAct 250;
BA_REL_ "GenSigSuprvResp" BU_SG_REL_ BCM_HS SG_ 386 AHEnbld 1;
BA_REL_ "GenSigTimeoutMsg" BU_SG_REL_ BCM_HS SG_ 386 AHEnbld 386;
BA_REL_ "GenSigTimeoutTime" BU_SG_REL_ BCM_HS SG_ 386 AHEnbld 250;
BA_REL_ "GenSigSuprvResp" BU_SG_REL_ BCM_HS SG_ 386 AHServcIO 1;
BA_REL_ "GenSigTimeoutMsg" BU_SG_REL_ BCM_HS SG_ 386 AHServcIO 386;
BA_REL_ "GenSigTimeoutTime" BU_SG_REL_ BCM_HS SG_ 386 AHServcIO 250;
BA_REL_ "GenSigSuprvResp" BU_SG_REL_ BCM_HS SG_ 386 AHAppBrkPedlIO 1;
BA_REL_ "GenSigTimeoutMsg" BU_SG_REL_ BCM_HS SG_ 386 AHAppBrkPedlIO 386;
BA_REL_ "GenSigTimeoutTime" BU_SG_REL_ BCM_HS SG_ 386 AHAppBrkPedlIO 250;
BA_REL_ "GenSigSuprvResp" BU_SG_REL_ BCM_HS SG_ 386 AHDisbldStbltIO 1;
BA_REL_ "GenSigTimeoutMsg" BU_SG_REL_ BCM_HS SG_ 386 AHDisbldStbltIO 386;
BA_REL_ "GenSigTimeoutTime" BU_SG_REL_ BCM_HS SG_ 386 AHDisbldStbltIO 250;
BA_REL_ "GenSigSuprvResp" BU_SG_REL_ BCM_HS SG_ 386 AHDisbldDrOpnIO 1;
BA_REL_ "GenSigTimeoutMsg" BU_SG_REL_ BCM_HS SG_ 386 AHDisbldDrOpnIO 386;
BA_REL_ "GenSigTimeoutTime" BU_SG_REL_ BCM_HS SG_ 386 AHDisbldDrOpnIO 250;
BA_REL_ "GenSigSuprvResp" BU_SG_REL_ BCM_HS SG_ 386 PMVSS_Disps 1;
BA_REL_ "GenSigTimeoutMsg" BU_SG_REL_ BCM_HS SG_ 386 PMVSS_Disps 386;
BA_REL_ "GenSigTimeoutTime" BU_SG_REL_ BCM_HS SG_ 386 PMVSS_Disps 250;
BA_REL_ "GenSigSuprvResp" BU_SG_REL_ BCM_HS SG_ 386 PMVSS_Exhst 1;
BA_REL_ "GenSigTimeoutMsg" BU_SG_REL_ BCM_HS SG_ 386 PMVSS_Exhst 386;
BA_REL_ "GenSigTimeoutTime" BU_SG_REL_ BCM_HS SG_ 386 PMVSS_Exhst 250;
BA_REL_ "GenSigSuprvResp" BU_SG_REL_ BCM_HS SG_ 386 PMVSS_PsngrSeat 1;
BA_REL_ "GenSigTimeoutMsg" BU_SG_REL_ BCM_HS SG_ 386 PMVSS_PsngrSeat 386;
BA_REL_ "GenSigTimeoutTime" BU_SG_REL_ BCM_HS SG_ 386 PMVSS_PsngrSeat 250;
BA_REL_ "GenSigSuprvResp" BU_SG_REL_ BCM_HS SG_ 386 PMVSS_DrvrSeat 1;
BA_REL_ "GenSigTimeoutMsg" BU_SG_REL_ BCM_HS SG_ 386 PMVSS_DrvrSeat 386;
BA_REL_ "GenSigTimeoutTime" BU_SG_REL_ BCM_HS SG_ 386 PMVSS_DrvrSeat 250;
BA_REL_ "GenSigSuprvResp" BU_SG_REL_ BCM_HS SG_ 386 PMVSS_AdptCrsCnt 1;
BA_REL_ "GenSigTimeoutMsg" BU_SG_REL_ BCM_HS SG_ 386 PMVSS_AdptCrsCnt 386;
BA_REL_ "GenSigTimeoutTime" BU_SG_REL_ BCM_HS SG_ 386 PMVSS_AdptCrsCnt 250;
BA_REL_ "GenSigSuprvResp" BU_SG_REL_ BCM_HS SG_ 386 PMVSS_Drvln 1;
BA_REL_ "GenSigTimeoutMsg" BU_SG_REL_ BCM_HS SG_ 386 PMVSS_Drvln 386;
BA_REL_ "GenSigTimeoutTime" BU_SG_REL_ BCM_HS SG_ 386 PMVSS_Drvln 250;
BA_REL_ "GenSigSuprvResp" BU_SG_REL_ BCM_HS SG_ 386 PMVSS_Susp 1;
BA_REL_ "GenSigTimeoutMsg" BU_SG_REL_ BCM_HS SG_ 386 PMVSS_Susp 386;
BA_REL_ "GenSigTimeoutTime" BU_SG_REL_ BCM_HS SG_ 386 PMVSS_Susp 250;
BA_REL_ "GenSigSuprvResp" BU_SG_REL_ BCM_HS SG_ 386 PMVSS_Strng 1;
BA_REL_ "GenSigTimeoutMsg" BU_SG_REL_ BCM_HS SG_ 386 PMVSS_Strng 386;
BA_REL_ "GenSigTimeoutTime" BU_SG_REL_ BCM_HS SG_ 386 PMVSS_Strng 250;
BA_REL_ "GenSigSuprvResp" BU_SG_REL_ BCM_HS SG_ 386 PMVSS_Trans 1;
BA_REL_ "GenSigTimeoutMsg" BU_SG_REL_ BCM_HS SG_ 386 PMVSS_Trans 386;
BA_REL_ "GenSigTimeoutTime" BU_SG_REL_ BCM_HS SG_ 386 PMVSS_Trans 250;
BA_REL_ "GenSigSuprvResp" BU_SG_REL_ BCM_HS SG_ 386 PMVSS_Eng 1;
BA_REL_ "GenSigTimeoutMsg" BU_SG_REL_ BCM_HS SG_ 386 PMVSS_Eng 386;
BA_REL_ "GenSigTimeoutTime" BU_SG_REL_ BCM_HS SG_ 386 PMVSS_Eng 250;
BA_REL_ "GenSigSuprvResp" BU_SG_REL_ BCM_HS SG_ 386 PMVSS_Snd 1;
BA_REL_ "GenSigTimeoutMsg" BU_SG_REL_ BCM_HS SG_ 386 PMVSS_Snd 386;
BA_REL_ "GenSigTimeoutTime" BU_SG_REL_ BCM_HS SG_ 386 PMVSS_Snd 250;
BA_REL_ "GenSigSuprvResp" BU_SG_REL_ ICCM_OBD_HS SG_ 532 RedntVSEAct 1;
BA_REL_ "GenSigTimeoutMsg" BU_SG_REL_ ICCM_OBD_HS SG_ 532 RedntVSEAct 532;
BA_REL_ "GenSigTimeoutTime" BU_SG_REL_ ICCM_OBD_HS SG_ 532 RedntVSEAct 125;
BA_REL_ "GenSigSuprvResp" BU_SG_REL_ EPS_HS SG_ 532 RedntVSEAct 1;
BA_REL_ "GenSigTimeoutMsg" BU_SG_REL_ EPS_HS SG_ 532 RedntVSEAct 532;
BA_REL_ "GenSigTimeoutTime" BU_SG_REL_ EPS_HS SG_ 532 RedntVSEAct 250;
BA_REL_ "GenSigSuprvResp" BU_SG_REL_ ICCM_HS SG_ 532 RedntVSEAct 1;
BA_REL_ "GenSigTimeoutMsg" BU_SG_REL_ ICCM_HS SG_ 532 RedntVSEAct 532;
BA_REL_ "GenSigTimeoutTime" BU_SG_REL_ ICCM_HS SG_ 532 RedntVSEAct 125;
BA_REL_ "GenSigSuprvResp" BU_SG_REL_ CGM_HS SG_ 532 VehHldDrvrDsblActvFlg 1;
BA_REL_ "GenSigTimeoutMsg" BU_SG_REL_ CGM_HS SG_ 532 VehHldDrvrDsblActvFlg 532;
BA_REL_ "GenSigTimeoutTime" BU_SG_REL_ CGM_HS SG_ 532 VehHldDrvrDsblActvFlg 250;
BA_REL_ "GenSigSuprvResp" BU_SG_REL_ EPB_HS SG_ 532 VehHldDrvrDsblActvFlg 1;
BA_REL_ "GenSigTimeoutMsg" BU_SG_REL_ EPB_HS SG_ 532 VehHldDrvrDsblActvFlg 532;
BA_REL_ "GenSigTimeoutTime" BU_SG_REL_ EPB_HS SG_ 532 VehHldDrvrDsblActvFlg 250;
BA_REL_ "GenSigSuprvResp" BU_SG_REL_ EPS_HS SG_ 532 AutoBrkngAvlbl 1;
BA_REL_ "GenSigTimeoutMsg" BU_SG_REL_ EPS_HS SG_ 532 AutoBrkngAvlbl 532;
BA_REL_ "GenSigTimeoutTime" BU_SG_REL_ EPS_HS SG_ 532 AutoBrkngAvlbl 250;
BA_REL_ "GenSigSuprvResp" BU_SG_REL_ ICCM_OBD_HS SG_ 532 ABSActvProtPVal 1;
BA_REL_ "GenSigTimeoutMsg" BU_SG_REL_ ICCM_OBD_HS SG_ 532 ABSActvProtPVal 532;
BA_REL_ "GenSigTimeoutTime" BU_SG_REL_ ICCM_OBD_HS SG_ 532 ABSActvProtPVal 125;
BA_REL_ "GenSigSuprvResp" BU_SG_REL_ ICCM_HS SG_ 532 ABSActvProtPVal 1;
BA_REL_ "GenSigTimeoutMsg" BU_SG_REL_ ICCM_HS SG_ 532 ABSActvProtPVal 532;
BA_REL_ "GenSigTimeoutTime" BU_SG_REL_ ICCM_HS SG_ 532 ABSActvProtPVal 125;
BA_REL_ "GenSigSuprvResp" BU_SG_REL_ ICCM_OBD_HS SG_ 532 ABSActvProtARC 1;
BA_REL_ "GenSigTimeoutMsg" BU_SG_REL_ ICCM_OBD_HS SG_ 532 ABSActvProtARC 532;
BA_REL_ "GenSigTimeoutTime" BU_SG_REL_ ICCM_OBD_HS SG_ 532 ABSActvProtARC 125;
BA_REL_ "GenSigSuprvResp" BU_SG_REL_ ICCM_HS SG_ 532 ABSActvProtARC 1;
BA_REL_ "GenSigTimeoutMsg" BU_SG_REL_ ICCM_HS SG_ 532 ABSActvProtARC 532;
BA_REL_ "GenSigTimeoutTime" BU_SG_REL_ ICCM_HS SG_ 532 ABSActvProtARC 125;
BA_REL_ "GenSigSuprvResp" BU_SG_REL_ ICCM_OBD_HS SG_ 532 ABSActvProt 1;
BA_REL_ "GenSigTimeoutMsg" BU_SG_REL_ ICCM_OBD_HS SG_ 532 ABSActvProt 532;
BA_REL_ "GenSigTimeoutTime" BU_SG_REL_ ICCM_OBD_HS SG_ 532 ABSActvProt 125;
BA_REL_ "GenSigSuprvResp" BU_SG_REL_ EPS_HS SG_ 532 ABSActvProt 1;
BA_REL_ "GenSigTimeoutMsg" BU_SG_REL_ EPS_HS SG_ 532 ABSActvProt 532;
BA_REL_ "GenSigTimeoutTime" BU_SG_REL_ EPS_HS SG_ 532 ABSActvProt 250;
BA_REL_ "GenSigSuprvResp" BU_SG_REL_ ICCM_HS SG_ 532 ABSActvProt 1;
BA_REL_ "GenSigTimeoutMsg" BU_SG_REL_ ICCM_HS SG_ 532 ABSActvProt 532;
BA_REL_ "GenSigTimeoutTime" BU_SG_REL_ ICCM_HS SG_ 532 ABSActvProt 125;
BA_REL_ "GenSigSuprvResp" BU_SG_REL_ BCM_HS SG_ 532 HilRlbkCtrlActIO 1;
BA_REL_ "GenSigTimeoutMsg" BU_SG_REL_ BCM_HS SG_ 532 HilRlbkCtrlActIO 532;
BA_REL_ "GenSigTimeoutTime" BU_SG_REL_ BCM_HS SG_ 532 HilRlbkCtrlActIO 250;
BA_REL_ "GenSigSuprvResp" BU_SG_REL_ EPB_HS SG_ 532 BrkSysAutBrkFld 1;
BA_REL_ "GenSigTimeoutMsg" BU_SG_REL_ EPB_HS SG_ 532 BrkSysAutBrkFld 532;
BA_REL_ "GenSigTimeoutTime" BU_SG_REL_ EPB_HS SG_ 532 BrkSysAutBrkFld 250;
BA_REL_ "GenSigSuprvResp" BU_SG_REL_ BCM_HS SG_ 532 BrkSysMalFuncIndOn 1;
BA_REL_ "GenSigTimeoutMsg" BU_SG_REL_ BCM_HS SG_ 532 BrkSysMalFuncIndOn 532;
BA_REL_ "GenSigTimeoutTime" BU_SG_REL_ BCM_HS SG_ 532 BrkSysMalFuncIndOn 300;
BA_REL_ "GenSigSuprvResp" BU_SG_REL_ ICCM_OBD_HS SG_ 532 BPDAPS_BkPDrvApPV 1;
BA_REL_ "GenSigTimeoutMsg" BU_SG_REL_ ICCM_OBD_HS SG_ 532 BPDAPS_BkPDrvApPV 532;
BA_REL_ "GenSigTimeoutTime" BU_SG_REL_ ICCM_OBD_HS SG_ 532 BPDAPS_BkPDrvApPV 250;
BA_REL_ "GenSigSuprvResp" BU_SG_REL_ ICCM_HS SG_ 532 BPDAPS_BkPDrvApPV 1;
BA_REL_ "GenSigTimeoutMsg" BU_SG_REL_ ICCM_HS SG_ 532 BPDAPS_BkPDrvApPV 532;
BA_REL_ "GenSigTimeoutTime" BU_SG_REL_ ICCM_HS SG_ 532 BPDAPS_BkPDrvApPV 250;
BA_REL_ "GenSigSuprvResp" BU_SG_REL_ EPB_HS SG_ 532 BPDAPS_BkPDrvApPV 1;
BA_REL_ "GenSigTimeoutMsg" BU_SG_REL_ EPB_HS SG_ 532 BPDAPS_BkPDrvApPV 532;
BA_REL_ "GenSigTimeoutTime" BU_SG_REL_ EPB_HS SG_ 532 BPDAPS_BkPDrvApPV 250;
BA_REL_ "GenSigSuprvResp" BU_SG_REL_ ICCM_OBD_HS SG_ 532 BPDAPS_BkPDrvApP 1;
BA_REL_ "GenSigTimeoutMsg" BU_SG_REL_ ICCM_OBD_HS SG_ 532 BPDAPS_BkPDrvApP 532;
BA_REL_ "GenSigTimeoutTime" BU_SG_REL_ ICCM_OBD_HS SG_ 532 BPDAPS_BkPDrvApP 250;
BA_REL_ "GenSigSuprvResp" BU_SG_REL_ ICCM_HS SG_ 532 BPDAPS_BkPDrvApP 1;
BA_REL_ "GenSigTimeoutMsg" BU_SG_REL_ ICCM_HS SG_ 532 BPDAPS_BkPDrvApP 532;
BA_REL_ "GenSigTimeoutTime" BU_SG_REL_ ICCM_HS SG_ 532 BPDAPS_BkPDrvApP 250;
BA_REL_ "GenSigSuprvResp" BU_SG_REL_ EPB_HS SG_ 532 BPDAPS_BkPDrvApP 1;
BA_REL_ "GenSigTimeoutMsg" BU_SG_REL_ EPB_HS SG_ 532 BPDAPS_BkPDrvApP 532;
BA_REL_ "GenSigTimeoutTime" BU_SG_REL_ EPB_HS SG_ 532 BPDAPS_BkPDrvApP 250;
BA_REL_ "GenSigSuprvResp" BU_SG_REL_ BCM_HS SG_ 532 BrkFldLvlLw 1;
BA_REL_ "GenSigVBitResp" BU_SG_REL_ BCM_HS SG_ 532 BrkFldLvlLw 1;
BA_REL_ "GenSigTimeoutMsg" BU_SG_REL_ BCM_HS SG_ 532 BrkFldLvlLw 532;
BA_REL_ "GenSigTimeoutTime" BU_SG_REL_ BCM_HS SG_ 532 BrkFldLvlLw 300;
BA_REL_ "GenSigSuprvResp" BU_SG_REL_ ICCM_OBD_HS SG_ 532 BrkPdDrvAPrsStaPVal 1;
BA_REL_ "GenSigTimeoutMsg" BU_SG_REL_ ICCM_OBD_HS SG_ 532 BrkPdDrvAPrsStaPVal 532;
BA_REL_ "GenSigTimeoutTime" BU_SG_REL_ ICCM_OBD_HS SG_ 532 BrkPdDrvAPrsStaPVal 250;
BA_REL_ "GenSigSuprvResp" BU_SG_REL_ ICCM_HS SG_ 532 BrkPdDrvAPrsStaPVal 1;
BA_REL_ "GenSigTimeoutMsg" BU_SG_REL_ ICCM_HS SG_ 532 BrkPdDrvAPrsStaPVal 532;
BA_REL_ "GenSigTimeoutTime" BU_SG_REL_ ICCM_HS SG_ 532 BrkPdDrvAPrsStaPVal 250;
BA_REL_ "GenSigSuprvResp" BU_SG_REL_ ICCM_OBD_HS SG_ 532 BrkPdDrvAppPrsAlRC 1;
BA_REL_ "GenSigTimeoutMsg" BU_SG_REL_ ICCM_OBD_HS SG_ 532 BrkPdDrvAppPrsAlRC 532;
BA_REL_ "GenSigTimeoutTime" BU_SG_REL_ ICCM_OBD_HS SG_ 532 BrkPdDrvAppPrsAlRC 250;
BA_REL_ "GenSigSuprvResp" BU_SG_REL_ ICCM_HS SG_ 532 BrkPdDrvAppPrsAlRC 1;
BA_REL_ "GenSigTimeoutMsg" BU_SG_REL_ ICCM_HS SG_ 532 BrkPdDrvAppPrsAlRC 532;
BA_REL_ "GenSigTimeoutTime" BU_SG_REL_ ICCM_HS SG_ 532 BrkPdDrvAppPrsAlRC 250;
BA_REL_ "GenSigSuprvResp" BU_SG_REL_ ICCM_OBD_HS SG_ 532 AutoBrkngAct 1;
BA_REL_ "GenSigTimeoutMsg" BU_SG_REL_ ICCM_OBD_HS SG_ 532 AutoBrkngAct 532;
BA_REL_ "GenSigTimeoutTime" BU_SG_REL_ ICCM_OBD_HS SG_ 532 AutoBrkngAct 125;
BA_REL_ "GenSigSuprvResp" BU_SG_REL_ ICCM_HS SG_ 532 AutoBrkngAct 1;
BA_REL_ "GenSigTimeoutMsg" BU_SG_REL_ ICCM_HS SG_ 532 AutoBrkngAct 532;
BA_REL_ "GenSigTimeoutTime" BU_SG_REL_ ICCM_HS SG_ 532 AutoBrkngAct 125;
BA_REL_ "GenSigSuprvResp" BU_SG_REL_ EPB_HS SG_ 532 AutoBrkngAct 1;
BA_REL_ "GenSigTimeoutMsg" BU_SG_REL_ EPB_HS SG_ 532 AutoBrkngAct 532;
BA_REL_ "GenSigTimeoutTime" BU_SG_REL_ EPB_HS SG_ 532 AutoBrkngAct 250;
BA_REL_ "GenSigSuprvResp" BU_SG_REL_ BCM_HS SG_ 328 StrngAsstRdcdIO 1;
BA_REL_ "GenSigTimeoutMsg" BU_SG_REL_ BCM_HS SG_ 328 StrngAsstRdcdIO 328;
BA_REL_ "GenSigTimeoutTime" BU_SG_REL_ BCM_HS SG_ 328 StrngAsstRdcdIO 2500;
BA_REL_ "GenSigSuprvResp" BU_SG_REL_ BCM_HS SG_ 328 PwrStrIO 1;
BA_REL_ "GenSigTimeoutMsg" BU_SG_REL_ BCM_HS SG_ 328 PwrStrIO 328;
BA_REL_ "GenSigTimeoutTime" BU_SG_REL_ BCM_HS SG_ 328 PwrStrIO 2500;
BA_REL_ "GenSigSuprvResp" BU_SG_REL_ BCM_HS SG_ 560 AllNodesVNA 1;
BA_REL_ "GenSigTimeoutMsg" BU_SG_REL_ BCM_HS SG_ 560 AllNodesVNA 560;
BA_REL_ "GenSigTimeoutTime" BU_SG_REL_ BCM_HS SG_ 560 AllNodesVNA 250;
BA_REL_ "GenSigSuprvResp" BU_SG_REL_ BCM_HS SG_ 560 StpOnBrkToRelPBIndOn 1;
BA_REL_ "GenSigTimeoutMsg" BU_SG_REL_ BCM_HS SG_ 560 StpOnBrkToRelPBIndOn 560;
BA_REL_ "GenSigTimeoutTime" BU_SG_REL_ BCM_HS SG_ 560 StpOnBrkToRelPBIndOn 250;
BA_REL_ "GenSigSuprvResp" BU_SG_REL_ BCM_HS SG_ 560 EPBSysDspMsgReq 1;
BA_REL_ "GenSigTimeoutMsg" BU_SG_REL_ BCM_HS SG_ 560 EPBSysDspMsgReq 560;
BA_REL_ "GenSigTimeoutTime" BU_SG_REL_ BCM_HS SG_ 560 EPBSysDspMsgReq 250;
BA_REL_ "GenSigSuprvResp" BU_SG_REL_ BCM_HS SG_ 560 EPBSysAudWarnReq 1;
BA_REL_ "GenSigTimeoutMsg" BU_SG_REL_ BCM_HS SG_ 560 EPBSysAudWarnReq 560;
BA_REL_ "GenSigTimeoutTime" BU_SG_REL_ BCM_HS SG_ 560 EPBSysAudWarnReq 250;
BA_REL_ "GenSigSuprvResp" BU_SG_REL_ BCM_HS SG_ 560 ElecPrkBrkStat 1;
BA_REL_ "GenSigTimeoutMsg" BU_SG_REL_ BCM_HS SG_ 560 ElecPrkBrkStat 560;
BA_REL_ "GenSigTimeoutTime" BU_SG_REL_ BCM_HS SG_ 560 ElecPrkBrkStat 250;
BA_REL_ "GenSigSuprvResp" BU_SG_REL_ BCM_HS SG_ 560 EPBSysBrkLtsReq 1;
BA_REL_ "GenSigTimeoutMsg" BU_SG_REL_ BCM_HS SG_ 560 EPBSysBrkLtsReq 560;
BA_REL_ "GenSigTimeoutTime" BU_SG_REL_ BCM_HS SG_ 560 EPBSysBrkLtsReq 250;
BA_REL_ "GenSigSuprvResp" BU_SG_REL_ BCM_HS SG_ 1219 DslExhFldDiagWrnIdRq 1;
BA_REL_ "GenSigTimeoutMsg" BU_SG_REL_ BCM_HS SG_ 1219 DslExhFldDiagWrnIdRq 1219;
BA_REL_ "GenSigTimeoutTime" BU_SG_REL_ BCM_HS SG_ 1219 DslExhFldDiagWrnIdRq 2500;
BA_REL_ "GenSigSuprvResp" BU_SG_REL_ BCM_HS SG_ 1219 DslEmnsOBDMrkt 1;
BA_REL_ "GenSigTimeoutMsg" BU_SG_REL_ BCM_HS SG_ 1219 DslEmnsOBDMrkt 1219;
BA_REL_ "GenSigTimeoutTime" BU_SG_REL_ BCM_HS SG_ 1219 DslEmnsOBDMrkt 2500;
BA_REL_ "GenSigSuprvResp" BU_SG_REL_ TCM_HS SG_ 442 CrksftTqMinImCap 1;
BA_REL_ "GenSigTimeoutMsg" BU_SG_REL_ TCM_HS SG_ 442 CrksftTqMinImCap 442;
BA_REL_ "GenSigTimeoutTime" BU_SG_REL_ TCM_HS SG_ 442 CrksftTqMinImCap 250;
BA_REL_ "GenSigSuprvResp" BU_SG_REL_ EBCM_OBD_HS SG_ 500 EnhDrvMdSwChUseAct 1;
BA_REL_ "GenSigTimeoutMsg" BU_SG_REL_ EBCM_OBD_HS SG_ 500 EnhDrvMdSwChUseAct 500;
BA_REL_ "GenSigTimeoutTime" BU_SG_REL_ EBCM_OBD_HS SG_ 500 EnhDrvMdSwChUseAct 250;
BA_REL_ "GenSigSuprvResp" BU_SG_REL_ EBCM_HS SG_ 500 EnhDrvMdSwChUseAct 1;
BA_REL_ "GenSigTimeoutMsg" BU_SG_REL_ EBCM_HS SG_ 500 EnhDrvMdSwChUseAct 500;
BA_REL_ "GenSigTimeoutTime" BU_SG_REL_ EBCM_HS SG_ 500 EnhDrvMdSwChUseAct 250;
BA_REL_ "GenSigSuprvResp" BU_SG_REL_ EBCM_OBD_HS SG_ 500 EnhDrvSelMdSwStat 1;
BA_REL_ "GenSigTimeoutMsg" BU_SG_REL_ EBCM_OBD_HS SG_ 500 EnhDrvSelMdSwStat 500;
BA_REL_ "GenSigTimeoutTime" BU_SG_REL_ EBCM_OBD_HS SG_ 500 EnhDrvSelMdSwStat 250;
BA_REL_ "GenSigSuprvResp" BU_SG_REL_ EBCM_HS SG_ 500 EnhDrvSelMdSwStat 1;
BA_REL_ "GenSigTimeoutMsg" BU_SG_REL_ EBCM_HS SG_ 500 EnhDrvSelMdSwStat 500;
BA_REL_ "GenSigTimeoutTime" BU_SG_REL_ EBCM_HS SG_ 500 EnhDrvSelMdSwStat 250;
BA_REL_ "GenSigSuprvResp" BU_SG_REL_ EBCM_OBD_HS SG_ 500 DrvSelMd7Stat 1;
BA_REL_ "GenSigTimeoutMsg" BU_SG_REL_ EBCM_OBD_HS SG_ 500 DrvSelMd7Stat 500;
BA_REL_ "GenSigTimeoutTime" BU_SG_REL_ EBCM_OBD_HS SG_ 500 DrvSelMd7Stat 250;
BA_REL_ "GenSigSuprvResp" BU_SG_REL_ EBCM_HS SG_ 500 DrvSelMd7Stat 1;
BA_REL_ "GenSigTimeoutMsg" BU_SG_REL_ EBCM_HS SG_ 500 DrvSelMd7Stat 500;
BA_REL_ "GenSigTimeoutTime" BU_SG_REL_ EBCM_HS SG_ 500 DrvSelMd7Stat 250;
BA_REL_ "GenSigSuprvResp" BU_SG_REL_ EBCM_OBD_HS SG_ 500 DrvSelMd6Stat 1;
BA_REL_ "GenSigTimeoutMsg" BU_SG_REL_ EBCM_OBD_HS SG_ 500 DrvSelMd6Stat 500;
BA_REL_ "GenSigTimeoutTime" BU_SG_REL_ EBCM_OBD_HS SG_ 500 DrvSelMd6Stat 250;
BA_REL_ "GenSigSuprvResp" BU_SG_REL_ EBCM_HS SG_ 500 DrvSelMd6Stat 1;
BA_REL_ "GenSigTimeoutMsg" BU_SG_REL_ EBCM_HS SG_ 500 DrvSelMd6Stat 500;
BA_REL_ "GenSigTimeoutTime" BU_SG_REL_ EBCM_HS SG_ 500 DrvSelMd6Stat 250;
BA_REL_ "GenSigSuprvResp" BU_SG_REL_ EBCM_OBD_HS SG_ 500 DrvSelMd5Stat 1;
BA_REL_ "GenSigTimeoutMsg" BU_SG_REL_ EBCM_OBD_HS SG_ 500 DrvSelMd5Stat 500;
BA_REL_ "GenSigTimeoutTime" BU_SG_REL_ EBCM_OBD_HS SG_ 500 DrvSelMd5Stat 250;
BA_REL_ "GenSigSuprvResp" BU_SG_REL_ EBCM_HS SG_ 500 DrvSelMd5Stat 1;
BA_REL_ "GenSigTimeoutMsg" BU_SG_REL_ EBCM_HS SG_ 500 DrvSelMd5Stat 500;
BA_REL_ "GenSigTimeoutTime" BU_SG_REL_ EBCM_HS SG_ 500 DrvSelMd5Stat 250;
BA_REL_ "GenSigSuprvResp" BU_SG_REL_ EBCM_OBD_HS SG_ 500 DrvSelMd4Stat 1;
BA_REL_ "GenSigTimeoutMsg" BU_SG_REL_ EBCM_OBD_HS SG_ 500 DrvSelMd4Stat 500;
BA_REL_ "GenSigTimeoutTime" BU_SG_REL_ EBCM_OBD_HS SG_ 500 DrvSelMd4Stat 250;
BA_REL_ "GenSigSuprvResp" BU_SG_REL_ EBCM_HS SG_ 500 DrvSelMd4Stat 1;
BA_REL_ "GenSigTimeoutMsg" BU_SG_REL_ EBCM_HS SG_ 500 DrvSelMd4Stat 500;
BA_REL_ "GenSigTimeoutTime" BU_SG_REL_ EBCM_HS SG_ 500 DrvSelMd4Stat 250;
BA_REL_ "GenSigSuprvResp" BU_SG_REL_ EBCM_OBD_HS SG_ 500 DrvSelMd3Stat 1;
BA_REL_ "GenSigTimeoutMsg" BU_SG_REL_ EBCM_OBD_HS SG_ 500 DrvSelMd3Stat 500;
BA_REL_ "GenSigTimeoutTime" BU_SG_REL_ EBCM_OBD_HS SG_ 500 DrvSelMd3Stat 250;
BA_REL_ "GenSigSuprvResp" BU_SG_REL_ EBCM_HS SG_ 500 DrvSelMd3Stat 1;
BA_REL_ "GenSigTimeoutMsg" BU_SG_REL_ EBCM_HS SG_ 500 DrvSelMd3Stat 500;
BA_REL_ "GenSigTimeoutTime" BU_SG_REL_ EBCM_HS SG_ 500 DrvSelMd3Stat 250;
BA_REL_ "GenSigSuprvResp" BU_SG_REL_ EBCM_OBD_HS SG_ 500 DrvSelMd2Stat 1;
BA_REL_ "GenSigTimeoutMsg" BU_SG_REL_ EBCM_OBD_HS SG_ 500 DrvSelMd2Stat 500;
BA_REL_ "GenSigTimeoutTime" BU_SG_REL_ EBCM_OBD_HS SG_ 500 DrvSelMd2Stat 250;
BA_REL_ "GenSigSuprvResp" BU_SG_REL_ EBCM_HS SG_ 500 DrvSelMd2Stat 1;
BA_REL_ "GenSigTimeoutMsg" BU_SG_REL_ EBCM_HS SG_ 500 DrvSelMd2Stat 500;
BA_REL_ "GenSigTimeoutTime" BU_SG_REL_ EBCM_HS SG_ 500 DrvSelMd2Stat 250;
BA_REL_ "GenSigSuprvResp" BU_SG_REL_ EBCM_OBD_HS SG_ 500 DSMSS_DrvSelMd0Pn 1;
BA_REL_ "GenSigTimeoutMsg" BU_SG_REL_ EBCM_OBD_HS SG_ 500 DSMSS_DrvSelMd0Pn 500;
BA_REL_ "GenSigTimeoutTime" BU_SG_REL_ EBCM_OBD_HS SG_ 500 DSMSS_DrvSelMd0Pn 250;
BA_REL_ "GenSigSuprvResp" BU_SG_REL_ EBCM_HS SG_ 500 DSMSS_DrvSelMd0Pn 1;
BA_REL_ "GenSigTimeoutMsg" BU_SG_REL_ EBCM_HS SG_ 500 DSMSS_DrvSelMd0Pn 500;
BA_REL_ "GenSigTimeoutTime" BU_SG_REL_ EBCM_HS SG_ 500 DSMSS_DrvSelMd0Pn 250;
BA_REL_ "GenSigSuprvResp" BU_SG_REL_ EBCM_OBD_HS SG_ 500 DSMSS_DrvSelMd8Pn 1;
BA_REL_ "GenSigTimeoutMsg" BU_SG_REL_ EBCM_OBD_HS SG_ 500 DSMSS_DrvSelMd8Pn 500;
BA_REL_ "GenSigTimeoutTime" BU_SG_REL_ EBCM_OBD_HS SG_ 500 DSMSS_DrvSelMd8Pn 250;
BA_REL_ "GenSigSuprvResp" BU_SG_REL_ EBCM_HS SG_ 500 DSMSS_DrvSelMd8Pn 1;
BA_REL_ "GenSigTimeoutMsg" BU_SG_REL_ EBCM_HS SG_ 500 DSMSS_DrvSelMd8Pn 500;
BA_REL_ "GenSigTimeoutTime" BU_SG_REL_ EBCM_HS SG_ 500 DSMSS_DrvSelMd8Pn 250;
BA_REL_ "GenSigSuprvResp" BU_SG_REL_ EBCM_OBD_HS SG_ 500 DSMSS_DrvSelMd7Pn 1;
BA_REL_ "GenSigTimeoutMsg" BU_SG_REL_ EBCM_OBD_HS SG_ 500 DSMSS_DrvSelMd7Pn 500;
BA_REL_ "GenSigTimeoutTime" BU_SG_REL_ EBCM_OBD_HS SG_ 500 DSMSS_DrvSelMd7Pn 250;
BA_REL_ "GenSigSuprvResp" BU_SG_REL_ EBCM_HS SG_ 500 DSMSS_DrvSelMd7Pn 1;
BA_REL_ "GenSigTimeoutMsg" BU_SG_REL_ EBCM_HS SG_ 500 DSMSS_DrvSelMd7Pn 500;
BA_REL_ "GenSigTimeoutTime" BU_SG_REL_ EBCM_HS SG_ 500 DSMSS_DrvSelMd7Pn 250;
BA_REL_ "GenSigSuprvResp" BU_SG_REL_ EBCM_OBD_HS SG_ 500 DSMSS_DrvSelMd6Pn 1;
BA_REL_ "GenSigTimeoutMsg" BU_SG_REL_ EBCM_OBD_HS SG_ 500 DSMSS_DrvSelMd6Pn 500;
BA_REL_ "GenSigTimeoutTime" BU_SG_REL_ EBCM_OBD_HS SG_ 500 DSMSS_DrvSelMd6Pn 250;
BA_REL_ "GenSigSuprvResp" BU_SG_REL_ EBCM_HS SG_ 500 DSMSS_DrvSelMd6Pn 1;
BA_REL_ "GenSigTimeoutMsg" BU_SG_REL_ EBCM_HS SG_ 500 DSMSS_DrvSelMd6Pn 500;
BA_REL_ "GenSigTimeoutTime" BU_SG_REL_ EBCM_HS SG_ 500 DSMSS_DrvSelMd6Pn 250;
BA_REL_ "GenSigSuprvResp" BU_SG_REL_ EBCM_OBD_HS SG_ 500 DSMSS_DrvSelMd5Pn 1;
BA_REL_ "GenSigTimeoutMsg" BU_SG_REL_ EBCM_OBD_HS SG_ 500 DSMSS_DrvSelMd5Pn 500;
BA_REL_ "GenSigTimeoutTime" BU_SG_REL_ EBCM_OBD_HS SG_ 500 DSMSS_DrvSelMd5Pn 250;
BA_REL_ "GenSigSuprvResp" BU_SG_REL_ EBCM_HS SG_ 500 DSMSS_DrvSelMd5Pn 1;
BA_REL_ "GenSigTimeoutMsg" BU_SG_REL_ EBCM_HS SG_ 500 DSMSS_DrvSelMd5Pn 500;
BA_REL_ "GenSigTimeoutTime" BU_SG_REL_ EBCM_HS SG_ 500 DSMSS_DrvSelMd5Pn 250;
BA_REL_ "GenSigSuprvResp" BU_SG_REL_ EBCM_OBD_HS SG_ 500 DSMSS_DrvSelMd4Pn 1;
BA_REL_ "GenSigTimeoutMsg" BU_SG_REL_ EBCM_OBD_HS SG_ 500 DSMSS_DrvSelMd4Pn 500;
BA_REL_ "GenSigTimeoutTime" BU_SG_REL_ EBCM_OBD_HS SG_ 500 DSMSS_DrvSelMd4Pn 250;
BA_REL_ "GenSigSuprvResp" BU_SG_REL_ EBCM_HS SG_ 500 DSMSS_DrvSelMd4Pn 1;
BA_REL_ "GenSigTimeoutMsg" BU_SG_REL_ EBCM_HS SG_ 500 DSMSS_DrvSelMd4Pn 500;
BA_REL_ "GenSigTimeoutTime" BU_SG_REL_ EBCM_HS SG_ 500 DSMSS_DrvSelMd4Pn 250;
BA_REL_ "GenSigSuprvResp" BU_SG_REL_ EBCM_OBD_HS SG_ 500 DSMSS_DrvSelMd3Pn 1;
BA_REL_ "GenSigTimeoutMsg" BU_SG_REL_ EBCM_OBD_HS SG_ 500 DSMSS_DrvSelMd3Pn 500;
BA_REL_ "GenSigTimeoutTime" BU_SG_REL_ EBCM_OBD_HS SG_ 500 DSMSS_DrvSelMd3Pn 250;
BA_REL_ "GenSigSuprvResp" BU_SG_REL_ EBCM_HS SG_ 500 DSMSS_DrvSelMd3Pn 1;
BA_REL_ "GenSigTimeoutMsg" BU_SG_REL_ EBCM_HS SG_ 500 DSMSS_DrvSelMd3Pn 500;
BA_REL_ "GenSigTimeoutTime" BU_SG_REL_ EBCM_HS SG_ 500 DSMSS_DrvSelMd3Pn 250;
BA_REL_ "GenSigSuprvResp" BU_SG_REL_ EBCM_OBD_HS SG_ 500 DSMSS_DrvSelMd2Pn 1;
BA_REL_ "GenSigTimeoutMsg" BU_SG_REL_ EBCM_OBD_HS SG_ 500 DSMSS_DrvSelMd2Pn 500;
BA_REL_ "GenSigTimeoutTime" BU_SG_REL_ EBCM_OBD_HS SG_ 500 DSMSS_DrvSelMd2Pn 250;
BA_REL_ "GenSigSuprvResp" BU_SG_REL_ EBCM_HS SG_ 500 DSMSS_DrvSelMd2Pn 1;
BA_REL_ "GenSigTimeoutMsg" BU_SG_REL_ EBCM_HS SG_ 500 DSMSS_DrvSelMd2Pn 500;
BA_REL_ "GenSigTimeoutTime" BU_SG_REL_ EBCM_HS SG_ 500 DSMSS_DrvSelMd2Pn 250;
BA_REL_ "GenSigSuprvResp" BU_SG_REL_ EBCM_OBD_HS SG_ 500 DSMSS_DrvSelMd1Pn 1;
BA_REL_ "GenSigTimeoutMsg" BU_SG_REL_ EBCM_OBD_HS SG_ 500 DSMSS_DrvSelMd1Pn 500;
BA_REL_ "GenSigTimeoutTime" BU_SG_REL_ EBCM_OBD_HS SG_ 500 DSMSS_DrvSelMd1Pn 250;
BA_REL_ "GenSigSuprvResp" BU_SG_REL_ EBCM_HS SG_ 500 DSMSS_DrvSelMd1Pn 1;
BA_REL_ "GenSigTimeoutMsg" BU_SG_REL_ EBCM_HS SG_ 500 DSMSS_DrvSelMd1Pn 500;
BA_REL_ "GenSigTimeoutTime" BU_SG_REL_ EBCM_HS SG_ 500 DSMSS_DrvSelMd1Pn 250;
BA_REL_ "GenSigSuprvResp" BU_SG_REL_ EBCM_OBD_HS SG_ 500 DSMSS_DrvSelMd8Un 1;
BA_REL_ "GenSigTimeoutMsg" BU_SG_REL_ EBCM_OBD_HS SG_ 500 DSMSS_DrvSelMd8Un 500;
BA_REL_ "GenSigTimeoutTime" BU_SG_REL_ EBCM_OBD_HS SG_ 500 DSMSS_DrvSelMd8Un 250;
BA_REL_ "GenSigSuprvResp" BU_SG_REL_ EBCM_HS SG_ 500 DSMSS_DrvSelMd8Un 1;
BA_REL_ "GenSigTimeoutMsg" BU_SG_REL_ EBCM_HS SG_ 500 DSMSS_DrvSelMd8Un 500;
BA_REL_ "GenSigTimeoutTime" BU_SG_REL_ EBCM_HS SG_ 500 DSMSS_DrvSelMd8Un 250;
BA_REL_ "GenSigSuprvResp" BU_SG_REL_ EBCM_OBD_HS SG_ 500 DSMSS_DrvSelMd7Un 1;
BA_REL_ "GenSigTimeoutMsg" BU_SG_REL_ EBCM_OBD_HS SG_ 500 DSMSS_DrvSelMd7Un 500;
BA_REL_ "GenSigTimeoutTime" BU_SG_REL_ EBCM_OBD_HS SG_ 500 DSMSS_DrvSelMd7Un 250;
BA_REL_ "GenSigSuprvResp" BU_SG_REL_ EBCM_HS SG_ 500 DSMSS_DrvSelMd7Un 1;
BA_REL_ "GenSigTimeoutMsg" BU_SG_REL_ EBCM_HS SG_ 500 DSMSS_DrvSelMd7Un 500;
BA_REL_ "GenSigTimeoutTime" BU_SG_REL_ EBCM_HS SG_ 500 DSMSS_DrvSelMd7Un 250;
BA_REL_ "GenSigSuprvResp" BU_SG_REL_ EBCM_OBD_HS SG_ 500 DSMSS_DrvSelMd6Un 1;
BA_REL_ "GenSigTimeoutMsg" BU_SG_REL_ EBCM_OBD_HS SG_ 500 DSMSS_DrvSelMd6Un 500;
BA_REL_ "GenSigTimeoutTime" BU_SG_REL_ EBCM_OBD_HS SG_ 500 DSMSS_DrvSelMd6Un 250;
BA_REL_ "GenSigSuprvResp" BU_SG_REL_ EBCM_HS SG_ 500 DSMSS_DrvSelMd6Un 1;
BA_REL_ "GenSigTimeoutMsg" BU_SG_REL_ EBCM_HS SG_ 500 DSMSS_DrvSelMd6Un 500;
BA_REL_ "GenSigTimeoutTime" BU_SG_REL_ EBCM_HS SG_ 500 DSMSS_DrvSelMd6Un 250;
BA_REL_ "GenSigSuprvResp" BU_SG_REL_ EBCM_OBD_HS SG_ 500 DSMSS_DrvSelMd5Un 1;
BA_REL_ "GenSigTimeoutMsg" BU_SG_REL_ EBCM_OBD_HS SG_ 500 DSMSS_DrvSelMd5Un 500;
BA_REL_ "GenSigTimeoutTime" BU_SG_REL_ EBCM_OBD_HS SG_ 500 DSMSS_DrvSelMd5Un 250;
BA_REL_ "GenSigSuprvResp" BU_SG_REL_ EBCM_HS SG_ 500 DSMSS_DrvSelMd5Un 1;
BA_REL_ "GenSigTimeoutMsg" BU_SG_REL_ EBCM_HS SG_ 500 DSMSS_DrvSelMd5Un 500;
BA_REL_ "GenSigTimeoutTime" BU_SG_REL_ EBCM_HS SG_ 500 DSMSS_DrvSelMd5Un 250;
BA_REL_ "GenSigSuprvResp" BU_SG_REL_ EBCM_OBD_HS SG_ 500 DSMSS_DrvSelMd4Un 1;
BA_REL_ "GenSigTimeoutMsg" BU_SG_REL_ EBCM_OBD_HS SG_ 500 DSMSS_DrvSelMd4Un 500;
BA_REL_ "GenSigTimeoutTime" BU_SG_REL_ EBCM_OBD_HS SG_ 500 DSMSS_DrvSelMd4Un 250;
BA_REL_ "GenSigSuprvResp" BU_SG_REL_ EBCM_HS SG_ 500 DSMSS_DrvSelMd4Un 1;
BA_REL_ "GenSigTimeoutMsg" BU_SG_REL_ EBCM_HS SG_ 500 DSMSS_DrvSelMd4Un 500;
BA_REL_ "GenSigTimeoutTime" BU_SG_REL_ EBCM_HS SG_ 500 DSMSS_DrvSelMd4Un 250;
BA_REL_ "GenSigSuprvResp" BU_SG_REL_ EBCM_OBD_HS SG_ 500 DSMSS_DrvSelMd3Un 1;
BA_REL_ "GenSigTimeoutMsg" BU_SG_REL_ EBCM_OBD_HS SG_ 500 DSMSS_DrvSelMd3Un 500;
BA_REL_ "GenSigTimeoutTime" BU_SG_REL_ EBCM_OBD_HS SG_ 500 DSMSS_DrvSelMd3Un 250;
BA_REL_ "GenSigSuprvResp" BU_SG_REL_ EBCM_HS SG_ 500 DSMSS_DrvSelMd3Un 1;
BA_REL_ "GenSigTimeoutMsg" BU_SG_REL_ EBCM_HS SG_ 500 DSMSS_DrvSelMd3Un 500;
BA_REL_ "GenSigTimeoutTime" BU_SG_REL_ EBCM_HS SG_ 500 DSMSS_DrvSelMd3Un 250;
BA_REL_ "GenSigSuprvResp" BU_SG_REL_ EBCM_OBD_HS SG_ 500 DSMSS_DrvSelMd2Un 1;
BA_REL_ "GenSigTimeoutMsg" BU_SG_REL_ EBCM_OBD_HS SG_ 500 DSMSS_DrvSelMd2Un 500;
BA_REL_ "GenSigTimeoutTime" BU_SG_REL_ EBCM_OBD_HS SG_ 500 DSMSS_DrvSelMd2Un 250;
BA_REL_ "GenSigSuprvResp" BU_SG_REL_ EBCM_HS SG_ 500 DSMSS_DrvSelMd2Un 1;
BA_REL_ "GenSigTimeoutMsg" BU_SG_REL_ EBCM_HS SG_ 500 DSMSS_DrvSelMd2Un 500;
BA_REL_ "GenSigTimeoutTime" BU_SG_REL_ EBCM_HS SG_ 500 DSMSS_DrvSelMd2Un 250;
BA_REL_ "GenSigSuprvResp" BU_SG_REL_ EBCM_OBD_HS SG_ 500 DSMSS_DrvSelMd1Un 1;
BA_REL_ "GenSigTimeoutMsg" BU_SG_REL_ EBCM_OBD_HS SG_ 500 DSMSS_DrvSelMd1Un 500;
BA_REL_ "GenSigTimeoutTime" BU_SG_REL_ EBCM_OBD_HS SG_ 500 DSMSS_DrvSelMd1Un 250;
BA_REL_ "GenSigSuprvResp" BU_SG_REL_ EBCM_HS SG_ 500 DSMSS_DrvSelMd1Un 1;
BA_REL_ "GenSigTimeoutMsg" BU_SG_REL_ EBCM_HS SG_ 500 DSMSS_DrvSelMd1Un 500;
BA_REL_ "GenSigTimeoutTime" BU_SG_REL_ EBCM_HS SG_ 500 DSMSS_DrvSelMd1Un 250;
BA_REL_ "GenSigSuprvResp" BU_SG_REL_ EBCM_OBD_HS SG_ 500 DrvSelMd1Stat 1;
BA_REL_ "GenSigTimeoutMsg" BU_SG_REL_ EBCM_OBD_HS SG_ 500 DrvSelMd1Stat 500;
BA_REL_ "GenSigTimeoutTime" BU_SG_REL_ EBCM_OBD_HS SG_ 500 DrvSelMd1Stat 250;
BA_REL_ "GenSigSuprvResp" BU_SG_REL_ EBCM_HS SG_ 500 DrvSelMd1Stat 1;
BA_REL_ "GenSigTimeoutMsg" BU_SG_REL_ EBCM_HS SG_ 500 DrvSelMd1Stat 500;
BA_REL_ "GenSigTimeoutTime" BU_SG_REL_ EBCM_HS SG_ 500 DrvSelMd1Stat 250;
BA_REL_ "GenSigSuprvResp" BU_SG_REL_ TCM_HS SG_ 1417 PrplsnTrqRelCap 1;
BA_REL_ "GenSigTimeoutMsg" BU_SG_REL_ TCM_HS SG_ 1417 PrplsnTrqRelCap 1417;
BA_REL_ "GenSigTimeoutTime" BU_SG_REL_ TCM_HS SG_ 1417 PrplsnTrqRelCap 1250;
BA_REL_ "GenSigSuprvResp" BU_SG_REL_ TCM_HS SG_ 170 AccPos 1;
BA_REL_ "GenSigTimeoutMsg" BU_SG_REL_ TCM_HS SG_ 170 AccPos 170;
BA_REL_ "GenSigTimeoutTime" BU_SG_REL_ TCM_HS SG_ 170 AccPos 250;
BA_REL_ "GenSigSuprvResp" BU_SG_REL_ BCM_HS SG_ 979 SpdLmtrSttngTypAct 1;
BA_REL_ "GenSigTimeoutMsg" BU_SG_REL_ BCM_HS SG_ 979 SpdLmtrSttngTypAct 979;
BA_REL_ "GenSigTimeoutTime" BU_SG_REL_ BCM_HS SG_ 979 SpdLmtrSttngTypAct 250;
BA_REL_ "GenSigSuprvResp" BU_SG_REL_ BCM_HS SG_ 979 SetSpdLmtRchd 1;
BA_REL_ "GenSigTimeoutMsg" BU_SG_REL_ BCM_HS SG_ 979 SetSpdLmtRchd 979;
BA_REL_ "GenSigTimeoutTime" BU_SG_REL_ BCM_HS SG_ 979 SetSpdLmtRchd 250;
BA_REL_ "GenSigSuprvResp" BU_SG_REL_ BCM_HS SG_ 979 ElvtdIdlCstCrStVal 1;
BA_REL_ "GenSigTimeoutMsg" BU_SG_REL_ BCM_HS SG_ 979 ElvtdIdlCstCrStVal 979;
BA_REL_ "GenSigTimeoutTime" BU_SG_REL_ BCM_HS SG_ 979 ElvtdIdlCstCrStVal 250;
BA_REL_ "GenSigSuprvResp" BU_SG_REL_ BCM_HS SG_ 979 ElvtdIdlCstStAvl 1;
BA_REL_ "GenSigTimeoutMsg" BU_SG_REL_ BCM_HS SG_ 979 ElvtdIdlCstStAvl 979;
BA_REL_ "GenSigTimeoutTime" BU_SG_REL_ BCM_HS SG_ 979 ElvtdIdlCstStAvl 250;
BA_REL_ "GenSigSuprvResp" BU_SG_REL_ BCM_HS SG_ 979 EngManfldAirTempCrtd 1;
BA_REL_ "GenSigTimeoutMsg" BU_SG_REL_ BCM_HS SG_ 979 EngManfldAirTempCrtd 979;
BA_REL_ "GenSigTimeoutTime" BU_SG_REL_ BCM_HS SG_ 979 EngManfldAirTempCrtd 250;
BA_REL_ "GenSigSuprvResp" BU_SG_REL_ TCM_HS SG_ 647 CrnksftTqModRspMxCap 1;
BA_REL_ "GenSigTimeoutMsg" BU_SG_REL_ TCM_HS SG_ 647 CrnksftTqModRspMxCap 647;
BA_REL_ "GenSigTimeoutTime" BU_SG_REL_ TCM_HS SG_ 647 CrnksftTqModRspMxCap 250;
BA_REL_ "GenSigSuprvResp" BU_SG_REL_ TCM_HS SG_ 647 EngDetPndTrnCsRngShf 1;
BA_REL_ "GenSigTimeoutMsg" BU_SG_REL_ TCM_HS SG_ 647 EngDetPndTrnCsRngShf 647;
BA_REL_ "GenSigTimeoutTime" BU_SG_REL_ TCM_HS SG_ 647 EngDetPndTrnCsRngShf 250;
BA_REL_ "GenSigSuprvResp" BU_SG_REL_ TCM_HS SG_ 647 CrpCstCrvCmd 1;
BA_REL_ "GenSigTimeoutMsg" BU_SG_REL_ TCM_HS SG_ 647 CrpCstCrvCmd 647;
BA_REL_ "GenSigTimeoutTime" BU_SG_REL_ TCM_HS SG_ 647 CrpCstCrvCmd 250;
BA_REL_ "GenSigSuprvResp" BU_SG_REL_ TCM_HS SG_ 647 DrPTGrdBrkDsbMdCmd 1;
BA_REL_ "GenSigTimeoutMsg" BU_SG_REL_ TCM_HS SG_ 647 DrPTGrdBrkDsbMdCmd 647;
BA_REL_ "GenSigTimeoutTime" BU_SG_REL_ TCM_HS SG_ 647 DrPTGrdBrkDsbMdCmd 62;
BA_REL_ "GenSigSuprvResp" BU_SG_REL_ TCM_HS SG_ 647 DrvWntrMdCmd 1;
BA_REL_ "GenSigTimeoutMsg" BU_SG_REL_ TCM_HS SG_ 647 DrvWntrMdCmd 647;
BA_REL_ "GenSigTimeoutTime" BU_SG_REL_ TCM_HS SG_ 647 DrvWntrMdCmd 62;
BA_REL_ "GenSigSuprvResp" BU_SG_REL_ TCM_HS SG_ 647 DrvTwHaulMdCmd 1;
BA_REL_ "GenSigTimeoutMsg" BU_SG_REL_ TCM_HS SG_ 647 DrvTwHaulMdCmd 647;
BA_REL_ "GenSigTimeoutTime" BU_SG_REL_ TCM_HS SG_ 647 DrvTwHaulMdCmd 62;
BA_REL_ "GenSigSuprvResp" BU_SG_REL_ TCM_HS SG_ 647 DrvSprtMdCmd 1;
BA_REL_ "GenSigTimeoutMsg" BU_SG_REL_ TCM_HS SG_ 647 DrvSprtMdCmd 647;
BA_REL_ "GenSigTimeoutTime" BU_SG_REL_ TCM_HS SG_ 647 DrvSprtMdCmd 62;
BA_REL_ "GenSigSuprvResp" BU_SG_REL_ TCM_HS SG_ 647 DrvEconMdCmd 1;
BA_REL_ "GenSigTimeoutMsg" BU_SG_REL_ TCM_HS SG_ 647 DrvEconMdCmd 647;
BA_REL_ "GenSigTimeoutTime" BU_SG_REL_ TCM_HS SG_ 647 DrvEconMdCmd 62;
BA_REL_ "GenSigSuprvResp" BU_SG_REL_ ICCM_OBD_HS SG_ 647 EngCntrlDtrmdTrfCRng 1;
BA_REL_ "GenSigTimeoutMsg" BU_SG_REL_ ICCM_OBD_HS SG_ 647 EngCntrlDtrmdTrfCRng 647;
BA_REL_ "GenSigTimeoutTime" BU_SG_REL_ ICCM_OBD_HS SG_ 647 EngCntrlDtrmdTrfCRng 250;
BA_REL_ "GenSigSuprvResp" BU_SG_REL_ ICCM_HS SG_ 647 EngCntrlDtrmdTrfCRng 1;
BA_REL_ "GenSigTimeoutMsg" BU_SG_REL_ ICCM_HS SG_ 647 EngCntrlDtrmdTrfCRng 647;
BA_REL_ "GenSigTimeoutTime" BU_SG_REL_ ICCM_HS SG_ 647 EngCntrlDtrmdTrfCRng 250;
BA_REL_ "GenSigSuprvResp" BU_SG_REL_ EBCM_OBD_HS SG_ 647 EngCtrlUtldTrnCRgPVal 1;
BA_REL_ "GenSigTimeoutMsg" BU_SG_REL_ EBCM_OBD_HS SG_ 647 EngCtrlUtldTrnCRgPVal 647;
BA_REL_ "GenSigTimeoutTime" BU_SG_REL_ EBCM_OBD_HS SG_ 647 EngCtrlUtldTrnCRgPVal 250;
BA_REL_ "GenSigSuprvResp" BU_SG_REL_ EBCM_HS SG_ 647 EngCtrlUtldTrnCRgPVal 1;
BA_REL_ "GenSigTimeoutMsg" BU_SG_REL_ EBCM_HS SG_ 647 EngCtrlUtldTrnCRgPVal 647;
BA_REL_ "GenSigTimeoutTime" BU_SG_REL_ EBCM_HS SG_ 647 EngCtrlUtldTrnCRgPVal 250;
BA_REL_ "GenSigSuprvResp" BU_SG_REL_ EBCM_OBD_HS SG_ 647 EngCntrlUtldTrnCsRng 1;
BA_REL_ "GenSigTimeoutMsg" BU_SG_REL_ EBCM_OBD_HS SG_ 647 EngCntrlUtldTrnCsRng 647;
BA_REL_ "GenSigTimeoutTime" BU_SG_REL_ EBCM_OBD_HS SG_ 647 EngCntrlUtldTrnCsRng 250;
BA_REL_ "GenSigSuprvResp" BU_SG_REL_ EBCM_HS SG_ 647 EngCntrlUtldTrnCsRng 1;
BA_REL_ "GenSigTimeoutMsg" BU_SG_REL_ EBCM_HS SG_ 647 EngCntrlUtldTrnCsRng 647;
BA_REL_ "GenSigTimeoutTime" BU_SG_REL_ EBCM_HS SG_ 647 EngCntrlUtldTrnCsRng 250;
BA_REL_ "GenSigSuprvResp" BU_SG_REL_ EBCM_OBD_HS SG_ 647 EngCntrlUtldTrnCsRgIn 1;
BA_REL_ "GenSigTimeoutMsg" BU_SG_REL_ EBCM_OBD_HS SG_ 647 EngCntrlUtldTrnCsRgIn 647;
BA_REL_ "GenSigTimeoutTime" BU_SG_REL_ EBCM_OBD_HS SG_ 647 EngCntrlUtldTrnCsRgIn 250;
BA_REL_ "GenSigSuprvResp" BU_SG_REL_ EBCM_HS SG_ 647 EngCntrlUtldTrnCsRgIn 1;
BA_REL_ "GenSigTimeoutMsg" BU_SG_REL_ EBCM_HS SG_ 647 EngCntrlUtldTrnCsRgIn 647;
BA_REL_ "GenSigTimeoutTime" BU_SG_REL_ EBCM_HS SG_ 647 EngCntrlUtldTrnCsRgIn 250;
BA_REL_ "GenSigSuprvResp" BU_SG_REL_ EBCM_OBD_HS SG_ 647 EngCtrlUtldTrnCRgARC 1;
BA_REL_ "GenSigTimeoutMsg" BU_SG_REL_ EBCM_OBD_HS SG_ 647 EngCtrlUtldTrnCRgARC 647;
BA_REL_ "GenSigTimeoutTime" BU_SG_REL_ EBCM_OBD_HS SG_ 647 EngCtrlUtldTrnCRgARC 250;
BA_REL_ "GenSigSuprvResp" BU_SG_REL_ EBCM_HS SG_ 647 EngCtrlUtldTrnCRgARC 1;
BA_REL_ "GenSigTimeoutMsg" BU_SG_REL_ EBCM_HS SG_ 647 EngCtrlUtldTrnCRgARC 647;
BA_REL_ "GenSigTimeoutTime" BU_SG_REL_ EBCM_HS SG_ 647 EngCtrlUtldTrnCRgARC 250;
BA_REL_ "GenSigSuprvResp" BU_SG_REL_ TCM_HS SG_ 1187 UndrHdAirFlwCap 1;
BA_REL_ "GenSigTimeoutMsg" BU_SG_REL_ TCM_HS SG_ 1187 UndrHdAirFlwCap 1187;
BA_REL_ "GenSigTimeoutTime" BU_SG_REL_ TCM_HS SG_ 1187 UndrHdAirFlwCap 2500;
BA_REL_ "GenSigSuprvResp" BU_SG_REL_ TCM_HS SG_ 1187 UndrHdAirFlwActPrcnt 1;
BA_REL_ "GenSigTimeoutMsg" BU_SG_REL_ TCM_HS SG_ 1187 UndrHdAirFlwActPrcnt 1187;
BA_REL_ "GenSigTimeoutTime" BU_SG_REL_ TCM_HS SG_ 1187 UndrHdAirFlwActPrcnt 2500;
BA_REL_ "GenSigSuprvResp" BU_SG_REL_ TCM_HS SG_ 1187 VehGrdSnsrBsd 1;
BA_REL_ "GenSigTimeoutMsg" BU_SG_REL_ TCM_HS SG_ 1187 VehGrdSnsrBsd 1187;
BA_REL_ "GenSigTimeoutTime" BU_SG_REL_ TCM_HS SG_ 1187 VehGrdSnsrBsd 2500;
BA_REL_ "GenSigSuprvResp" BU_SG_REL_ ICCM_OBD_HS SG_ 487 CmmndAirFuelRatio 1;
BA_REL_ "GenSigTimeoutMsg" BU_SG_REL_ ICCM_OBD_HS SG_ 487 CmmndAirFuelRatio 487;
BA_REL_ "GenSigTimeoutTime" BU_SG_REL_ ICCM_OBD_HS SG_ 487 CmmndAirFuelRatio 250;
BA_REL_ "GenSigSuprvResp" BU_SG_REL_ ICCM_HS SG_ 487 CmmndAirFuelRatio 1;
BA_REL_ "GenSigTimeoutMsg" BU_SG_REL_ ICCM_HS SG_ 487 CmmndAirFuelRatio 487;
BA_REL_ "GenSigTimeoutTime" BU_SG_REL_ ICCM_HS SG_ 487 CmmndAirFuelRatio 250;
BA_REL_ "GenSigSuprvResp" BU_SG_REL_ ICCM_OBD_HS SG_ 487 InstFuelFlowEst 1;
BA_REL_ "GenSigTimeoutMsg" BU_SG_REL_ ICCM_OBD_HS SG_ 487 InstFuelFlowEst 487;
BA_REL_ "GenSigTimeoutTime" BU_SG_REL_ ICCM_OBD_HS SG_ 487 InstFuelFlowEst 250;
BA_REL_ "GenSigSuprvResp" BU_SG_REL_ ICCM_HS SG_ 487 InstFuelFlowEst 1;
BA_REL_ "GenSigTimeoutMsg" BU_SG_REL_ ICCM_HS SG_ 487 InstFuelFlowEst 487;
BA_REL_ "GenSigTimeoutTime" BU_SG_REL_ ICCM_HS SG_ 487 InstFuelFlowEst 250;
BA_REL_ "GenSigSuprvResp" BU_SG_REL_ ICCM_OBD_HS SG_ 487 FuelDelPressRqd 1;
BA_REL_ "GenSigTimeoutMsg" BU_SG_REL_ ICCM_OBD_HS SG_ 487 FuelDelPressRqd 487;
BA_REL_ "GenSigTimeoutTime" BU_SG_REL_ ICCM_OBD_HS SG_ 487 FuelDelPressRqd 250;
BA_REL_ "GenSigSuprvResp" BU_SG_REL_ ICCM_HS SG_ 487 FuelDelPressRqd 1;
BA_REL_ "GenSigTimeoutMsg" BU_SG_REL_ ICCM_HS SG_ 487 FuelDelPressRqd 487;
BA_REL_ "GenSigTimeoutTime" BU_SG_REL_ ICCM_HS SG_ 487 FuelDelPressRqd 250;
BA_REL_ "GenSigSuprvResp" BU_SG_REL_ ICCM_OBD_HS SG_ 487 EngRunng 1;
BA_REL_ "GenSigTimeoutMsg" BU_SG_REL_ ICCM_OBD_HS SG_ 487 EngRunng 487;
BA_REL_ "GenSigTimeoutTime" BU_SG_REL_ ICCM_OBD_HS SG_ 487 EngRunng 250;
BA_REL_ "GenSigSuprvResp" BU_SG_REL_ ICCM_HS SG_ 487 EngRunng 1;
BA_REL_ "GenSigTimeoutMsg" BU_SG_REL_ ICCM_HS SG_ 487 EngRunng 487;
BA_REL_ "GenSigTimeoutTime" BU_SG_REL_ ICCM_HS SG_ 487 EngRunng 250;
BA_REL_ "GenSigSuprvResp" BU_SG_REL_ ICCM_OBD_HS SG_ 487 FlPmpEDscOtptCmdSta 1;
BA_REL_ "GenSigTimeoutMsg" BU_SG_REL_ ICCM_OBD_HS SG_ 487 FlPmpEDscOtptCmdSta 487;
BA_REL_ "GenSigTimeoutTime" BU_SG_REL_ ICCM_OBD_HS SG_ 487 FlPmpEDscOtptCmdSta 250;
BA_REL_ "GenSigSuprvResp" BU_SG_REL_ ICCM_HS SG_ 487 FlPmpEDscOtptCmdSta 1;
BA_REL_ "GenSigTimeoutMsg" BU_SG_REL_ ICCM_HS SG_ 487 FlPmpEDscOtptCmdSta 487;
BA_REL_ "GenSigTimeoutTime" BU_SG_REL_ ICCM_HS SG_ 487 FlPmpEDscOtptCmdSta 250;
BA_REL_ "GenSigSuprvResp" BU_SG_REL_ ICCM_OBD_HS SG_ 487 FuelCntlSysFltPrsnt 1;
BA_REL_ "GenSigTimeoutMsg" BU_SG_REL_ ICCM_OBD_HS SG_ 487 FuelCntlSysFltPrsnt 487;
BA_REL_ "GenSigTimeoutTime" BU_SG_REL_ ICCM_OBD_HS SG_ 487 FuelCntlSysFltPrsnt 250;
BA_REL_ "GenSigSuprvResp" BU_SG_REL_ ICCM_HS SG_ 487 FuelCntlSysFltPrsnt 1;
BA_REL_ "GenSigTimeoutMsg" BU_SG_REL_ ICCM_HS SG_ 487 FuelCntlSysFltPrsnt 487;
BA_REL_ "GenSigTimeoutTime" BU_SG_REL_ ICCM_HS SG_ 487 FuelCntlSysFltPrsnt 250;
BA_REL_ "GenSigSuprvResp" BU_SG_REL_ ICCM_OBD_HS SG_ 487 HiPresFuelPmpDelDur 1;
BA_REL_ "GenSigTimeoutMsg" BU_SG_REL_ ICCM_OBD_HS SG_ 487 HiPresFuelPmpDelDur 487;
BA_REL_ "GenSigTimeoutTime" BU_SG_REL_ ICCM_OBD_HS SG_ 487 HiPresFuelPmpDelDur 250;
BA_REL_ "GenSigSuprvResp" BU_SG_REL_ ICCM_HS SG_ 487 HiPresFuelPmpDelDur 1;
BA_REL_ "GenSigTimeoutMsg" BU_SG_REL_ ICCM_HS SG_ 487 HiPresFuelPmpDelDur 487;
BA_REL_ "GenSigTimeoutTime" BU_SG_REL_ ICCM_HS SG_ 487 HiPresFuelPmpDelDur 250;
BA_REL_ "GenSigSuprvResp" BU_SG_REL_ ICCM_OBD_HS SG_ 487 HiPresFuelPmpCntMd 1;
BA_REL_ "GenSigTimeoutMsg" BU_SG_REL_ ICCM_OBD_HS SG_ 487 HiPresFuelPmpCntMd 487;
BA_REL_ "GenSigTimeoutTime" BU_SG_REL_ ICCM_OBD_HS SG_ 487 HiPresFuelPmpCntMd 250;
BA_REL_ "GenSigSuprvResp" BU_SG_REL_ ICCM_HS SG_ 487 HiPresFuelPmpCntMd 1;
BA_REL_ "GenSigTimeoutMsg" BU_SG_REL_ ICCM_HS SG_ 487 HiPresFuelPmpCntMd 487;
BA_REL_ "GenSigTimeoutTime" BU_SG_REL_ ICCM_HS SG_ 487 HiPresFuelPmpCntMd 250;
BA_REL_ "GenSigSuprvResp" BU_SG_REL_ TCCM_HS SG_ 398 EngActStdyStTorq 1;
BA_REL_ "GenSigTimeoutMsg" BU_SG_REL_ TCCM_HS SG_ 398 EngActStdyStTorq 398;
BA_REL_ "GenSigTimeoutTime" BU_SG_REL_ TCCM_HS SG_ 398 EngActStdyStTorq 250;
BA_REL_ "GenSigSuprvResp" BU_SG_REL_ TCM_HS SG_ 398 EngActStdyStTorq 1;
BA_REL_ "GenSigTimeoutMsg" BU_SG_REL_ TCM_HS SG_ 398 EngActStdyStTorq 398;
BA_REL_ "GenSigTimeoutTime" BU_SG_REL_ TCM_HS SG_ 398 EngActStdyStTorq 250;
BA_REL_ "GenSigSuprvResp" BU_SG_REL_ TCCM_HS SG_ 398 AccKdwnAtv 1;
BA_REL_ "GenSigTimeoutMsg" BU_SG_REL_ TCCM_HS SG_ 398 AccKdwnAtv 398;
BA_REL_ "GenSigTimeoutTime" BU_SG_REL_ TCCM_HS SG_ 398 AccKdwnAtv 250;
BA_REL_ "GenSigSuprvResp" BU_SG_REL_ TCM_HS SG_ 398 AccKdwnAtv 1;
BA_REL_ "GenSigTimeoutMsg" BU_SG_REL_ TCM_HS SG_ 398 AccKdwnAtv 398;
BA_REL_ "GenSigTimeoutTime" BU_SG_REL_ TCM_HS SG_ 398 AccKdwnAtv 250;
BA_REL_ "GenSigSuprvResp" BU_SG_REL_ TCCM_HS SG_ 398 TrnsEngSpdReqFld 1;
BA_REL_ "GenSigTimeoutMsg" BU_SG_REL_ TCCM_HS SG_ 398 TrnsEngSpdReqFld 398;
BA_REL_ "GenSigTimeoutTime" BU_SG_REL_ TCCM_HS SG_ 398 TrnsEngSpdReqFld 250;
BA_REL_ "GenSigSuprvResp" BU_SG_REL_ TCM_HS SG_ 398 TrnsEngSpdReqFld 1;
BA_REL_ "GenSigTimeoutMsg" BU_SG_REL_ TCM_HS SG_ 398 TrnsEngSpdReqFld 398;
BA_REL_ "GenSigTimeoutTime" BU_SG_REL_ TCM_HS SG_ 398 TrnsEngSpdReqFld 250;
VAL_ 565 PerfMdMainMenuType 7 "Reserved" 6 "Reserved" 5 "Reserved" 4 "Reserved" 3 "Main Menu Type 3" 2 "Main Menu Type 2" 1 "Main Menu Type 1" 0 "No Action" ;
VAL_ 565 PSPMCA_PsngStPrfMd6Avl 1 "true" 0 "false" ;
VAL_ 565 PSPMCA_PsngStPrfMd5Avl 1 "true" 0 "false" ;
VAL_ 565 PSPMCA_PsngStPrfMd4Avl 1 "true" 0 "false" ;
VAL_ 565 PSPMCA_PsngStPrfMd3Avl 1 "true" 0 "false" ;
VAL_ 565 PSPMCA_PsngStPrfMd2Avl 1 "true" 0 "false" ;
VAL_ 565 PSPMCA_PsngStPrfMd1Avl 1 "true" 0 "false" ;
VAL_ 565 DSPMCA_DrvStyPrfMd7Avl 1 "true" 0 "false" ;
VAL_ 565 DSPMCA_DrvStyPrfMd6Avl 1 "true" 0 "false" ;
VAL_ 565 DSPMCA_DrvStyPrfMd5Avl 1 "true" 0 "false" ;
VAL_ 565 DSPMCA_DrvStyPrfMd4Avl 1 "true" 0 "false" ;
VAL_ 565 DSPMCA_DrvStyPrfMd3Avl 1 "true" 0 "false" ;
VAL_ 565 DSPMCA_DrvStyPrfMd2Avl 1 "true" 0 "false" ;
VAL_ 565 DSPMCA_DrvStyPrfMd1Avl 1 "true" 0 "false" ;
VAL_ 565 DSPMCA_DrvrStPrfMd6Avl 1 "true" 0 "false" ;
VAL_ 565 DSPMCA_DrvrStPrfMd5Avl 1 "true" 0 "false" ;
VAL_ 565 DSPMCA_DrvrStPrfMd4Avl 1 "true" 0 "false" ;
VAL_ 565 DSPMCA_DrvrStPrfMd3Avl 1 "true" 0 "false" ;
VAL_ 565 DSPMCA_DrvrStPrfMd2Avl 1 "true" 0 "false" ;
VAL_ 565 DSPMCA_DrvrStPrfMd1Avl 1 "true" 0 "false" ;
VAL_ 565 ACCPMCA_ACCPrfMd6Avl 1 "true" 0 "false" ;
VAL_ 565 ACCPMCA_ACCPrfMd5Avl 1 "true" 0 "false" ;
VAL_ 565 ACCPMCA_ACCPrfMd4Avl 1 "true" 0 "false" ;
VAL_ 565 ACCPMCA_ACCPrfMd3Avl 1 "true" 0 "false" ;
VAL_ 565 ACCPMCA_ACCPrfMd2Avl 1 "true" 0 "false" ;
VAL_ 565 ACCPMCA_ACCPrfMd1Avl 1 "true" 0 "false" ;
VAL_ 530 RstVTDTmprDtctd 1 "Reset" 0 "No Action" ;
VAL_ 530 RstIllDrIdDevDtctd 1 "Reset" 0 "No Action" ;
VAL_ 530 RstDrIdDevLrnd 1 "Reset" 0 "No Action" ;
VAL_ 368 EnvIdRspSt5 0 "No info" 1 "Info valid" 2 "Incorrect immo id" 3 "Environment id request" ;
VAL_ 882 RghtHndLftHndTrffc 0 "Left Hand Traffic" 1 "Right Hand Traffic" ;
VAL_ 882 AdvFrntLghtSysHiBmIO 1 "true" 0 "false" ;
VAL_ 817 RrAxlELSDCplLwResV 1 "Invalid" 0 "Valid" ;
VAL_ 817 RrAxlTmpInhIO 1 "true" 0 "false" ;
VAL_ 817 RrAxlMalfIO 1 "true" 0 "false" ;
VAL_ 853 SrvPedtrnProtSysIO 1 "true" 0 "false" ;
VAL_ 853 PedtrnProtSysDisbld 1 "true" 0 "false" ;
VAL_ 853 PedtrnProtSysDpl 1 "true" 0 "false" ;
VAL_ 869 FwdClnMtgnBrkReqAct 1 "true" 0 "false" ;
VAL_ 869 FCACustStngAvlbl 1 "true" 0 "false" ;
VAL_ 869 FwdClnAlrtCustCrntSetngVal 0 "No Action" 1 "Off" 2 "On" ;
VAL_ 869 GNCustSetngAvlbl 1 "true" 0 "false" ;
VAL_ 869 CPSUnblIO 1 "true" 0 "false" ;
VAL_ 869 ColPrSysStngAvl 1 "true" 0 "false" ;
VAL_ 869 CPSOffIO 1 "true" 0 "false" ;
VAL_ 869 CPSFldIO 1 "true" 0 "false" ;
VAL_ 869 ColPrSysCrntStng 0 "No Action" 1 "Off" 2 "Alert" 3 "Alert and Brake" ;
VAL_ 869 CPSAlrtOnlIO 1 "true" 0 "false" ;
VAL_ 869 GNCustCrntStngVal 0 "No Action" 1 "Off" 2 "On" ;
VAL_ 564 AdptDrvrSeatStng 7 "Performance Mode 7" 6 "Performance Mode 6" 5 "Performance Mode 5" 4 "Performance Mode 4" 3 "Performance Mode 3" 2 "Performance Mode 2" 1 "Performance Mode 1" 0 "No Action" ;
VAL_ 564 AdptPsngrSeatStng 7 "Performance Mode 7" 6 "Performance Mode 6" 5 "Performance Mode 5" 4 "Performance Mode 4" 3 "Performance Mode 3" 2 "Performance Mode 2" 1 "Performance Mode 1" 0 "No Action" ;
VAL_ 564 TnDrvTrCtrlOffUnbIO 1 "true" 0 "false" ;
VAL_ 564 TnDrvStblCtrlOffUnbIO 1 "true" 0 "false" ;
VAL_ 564 VehRollAngleV 1 "Invalid" 0 "Valid" ;
VAL_ 564 VehPitchAngleV 1 "Invalid" 0 "Valid" ;
VAL_ 564 RdWhlAngV 1 "Invalid" 0 "Valid" ;
VAL_ 564 TrlrStabAstActIO 1 "true" 0 "false" ;
VAL_ 564 PerfTrcCrnExStngVal 0 "No Action" 1 "Off" 2 "Setting 1" 3 "Setting 2" 4 "Setting 3" 5 "Setting 4" 6 "Setting 5" 7 "Setting 6" 8 "Setting 7" 9 "Setting 8" 10 "Setting 9" 11 "Setting 10" 12 "Setting 11" 13 "Setting 12" 14 "Setting 13" 15 "Setting 14" 16 "Setting 15" ;
VAL_ 1296 ACCAutoSetSpdStat 0 "No Set Speed Change" 1 "Proposed Speed Limit Change" 2 "Accepted Speed Limit Change" 3 "Declined Speed Limit Change" ;
VAL_ 1296 FwdClnAlrtOffIO 1 "true" 0 "false" ;
VAL_ 1296 VADIR_IndLvl 0 "No indication" 1 "Indication level 1" 2 "Indication Level 2" 3 "Indication Level 3" 4 "Indication Level 4" 5 "Indication Level 5" 6 "Indication Level 6" 7 "Indication Level 7" 8 "Indication Level 8" ;
VAL_ 536 ShtToPrkBfExtngVehIO 1 "true" 0 "false" ;
VAL_ 536 AutoBrkRlsIO 1 "true" 0 "false" ;
VAL_ 536 HdUpDsplyUnblIO 1 "true" 0 "false" ;
VAL_ 536 FSRACCFrstRsmPrssIO 1 "true" 0 "false" ;
VAL_ 536 FrtRdrBlckdIO 1 "true" 0 "false" ;
VAL_ 848 TrlrBrkStat 6 "Integration Calibrated Off" 0 "Normal Operation" 1 "Brake Control Interactive" 2 "Temporary Inhibit" 3 "Temporarily Limited" 4 "Permanently Failed" 5 "Communication Failed" ;
VAL_ 848 TrlrBrkngSysBrkLtsReq 1 "true" 0 "false" ;
VAL_ 848 SrvTrlrBrkngSysIO 1 "true" 0 "false" ;
VAL_ 848 TrlrWiringFltIO 1 "true" 0 "false" ;
VAL_ 848 TrlrCnctdIO 1 "true" 0 "false" ;
VAL_ 848 TrlrBrkngGainSetIO 1 "true" 0 "false" ;
VAL_ 848 ChkTrlrIO 1 "true" 0 "false" ;
VAL_ 848 TrlrHtchSwAtv_ITBC 1 "true" 0 "false" ;
VAL_ 993 HybVehHiVltSysDisbld 1 "true" 0 "false" ;
VAL_ 993 CstmrUsblSOCV 1 "Invalid" 0 "Valid" ;
VAL_ 993 JmpStrtStat 0 "Inactive" 1 "In Progress" 2 "Complete" 3 "Power Mode" 4 "Disabled" ;
VAL_ 993 SvcHybridSysIO 1 "true" 0 "false" ;
VAL_ 993 HybMdDisp 15 "Engine Charging Battery While Idle" 14 "Engine Charging Battery Moving" 13 "Engine Power Load Sharing" 12 "Battery Power Load Sharing" 11 "Undetermined" 10 "Charging With Engine On" 9 "Charging With Engine Off" 8 "Hybrid Power 4WD" 7 "Hybrid Power 2WD" 6 "Engine Power 4WD" 5 "Engine Power 2WD" 4 "Battery Power 4WD" 3 "Battery Power 2WD" 2 "Auto Stop" 1 "Engine Idle" 0 "Default / Accessory" ;
VAL_ 1280 TireRRLowTracIO 1 "true" 0 "false" ;
VAL_ 1280 TireRFLowTracIO 1 "true" 0 "false" ;
VAL_ 1280 TireLRLowTracIO 1 "true" 0 "false" ;
VAL_ 1280 TireLFLowTracIO 1 "true" 0 "false" ;
VAL_ 562 DrvlneMntsPerfMdRq 0 "No Action" 1 "Performance Mode 1" 2 "Performance Mode 2" 3 "Performance Mode 3" 4 "Performance Mode 4" 5 "Performance Mode 5" 6 "Performance Mode 6" 7 "Performance Mode 7" ;
VAL_ 562 RideCntrlPerfMdRq 7 "Performance Mode 7" 6 "Performance Mode 6" 5 "Performance Mode 5" 4 "Performance Mode 4" 3 "Performance Mode 3" 2 "Performance Mode 2" 1 "Performance Mode 1" 0 "No Action" ;
VAL_ 562 StgSysPerfMdRq 7 "Performance Mode 7" 6 "Performance Mode 6" 5 "Performance Mode 5" 4 "Performance Mode 4" 3 "Performance Mode 3" 2 "Performance Mode 2" 1 "Performance Mode 1" 0 "No Action" ;
VAL_ 562 DiffPerfMdRq 7 "Performance Mode 7" 6 "Performance Mode 6" 5 "Performance Mode 5" 4 "Performance Mode 4" 3 "Performance Mode 3" 2 "Performance Mode 2" 1 "Performance Mode 1" 0 "No Action" ;
VAL_ 562 ExhstPerfMdRq 7 "Performance Mode 7" 6 "Performance Mode 6" 5 "Performance Mode 5" 4 "Performance Mode 4" 3 "Performance Mode 3" 2 "Performance Mode 2" 1 "Performance Mode 1" 0 "No Action" ;
VAL_ 562 AWDPerfMdRq 7 "Performance Mode 7" 6 "Performance Mode 6" 5 "Performance Mode 5" 4 "Performance Mode 4" 3 "Performance Mode 3" 2 "Performance Mode 2" 1 "Performance Mode 1" 0 "No Action" ;
VAL_ 562 DispPerfMdCsCrStVal 0 "No Action" 1 "Performance Mode 1" 2 "Performance Mode 2" 3 "Performance Mode 3" 4 "Performance Mode 4" 5 "Performance Mode 5" 6 "Performance Mode 6" 7 "Auto" ;
VAL_ 562 SndEnhcmtPerfMdRq 7 "Performance Mode 7" 6 "Performance Mode 6" 5 "Performance Mode 5" 4 "Performance Mode 4" 3 "Performance Mode 3" 2 "Performance Mode 2" 1 "Performance Mode 1" 0 "No Action" ;
VAL_ 562 DsplyPerfMdRq 7 "Performance Mode 7" 6 "Performance Mode 6" 5 "Performance Mode 5" 4 "Performance Mode 4" 3 "Performance Mode 3" 2 "Performance Mode 2" 1 "Performance Mode 1" 0 "No Action" ;
VAL_ 562 HillDscntCntlSysStat 4 "Temporarily Inhibited" 3 "Failed" 2 "Active" 1 "Enabled" 0 "Normal" ;
VAL_ 562 SusCustStngAvlbl 1 "true" 0 "false" ;
VAL_ 562 SusCustCurrStngVal 7 "Auto" 6 "Performance Mode 6" 5 "Performance Mode 5" 4 "Performance Mode 4" 3 "Performance Mode 3" 0 "No Action" 1 "Performance Mode 1" 2 "Performance Mode 2" ;
VAL_ 562 StrCustStngAvlbl 1 "true" 0 "false" ;
VAL_ 562 StrCustCurrStngVal 7 "Auto" 6 "Performance Mode 6" 5 "Performance Mode 5" 4 "Performance Mode 4" 3 "Performance Mode 3" 0 "No Action" 1 "Performance Mode 1" 2 "Performance Mode 2" ;
VAL_ 562 DrvlnCustStngAvlbl 1 "true" 0 "false" ;
VAL_ 562 DrvlnCustCurrStngVal 7 "Auto" 6 "Performance Mode 6" 5 "Performance Mode 5" 4 "Performance Mode 4" 3 "Performance Mode 3" 0 "No Action" 1 "Performance Mode 1" 2 "Performance Mode 2" ;
VAL_ 562 SndPerfMdCsStAvl 1 "true" 0 "false" ;
VAL_ 562 SndPerfMdCsCrStVal 0 "No Action" 1 "Performance Mode 1" 2 "Performance Mode 2" 3 "Performance Mode 3" 4 "Performance Mode 4" 5 "Performance Mode 5" 6 "Performance Mode 6" 7 "Auto" ;
VAL_ 562 DispPerfMdCsStAvl 1 "true" 0 "false" ;
VAL_ 893 AFLMnu3CstStAvl 1 "true" 0 "false" ;
VAL_ 893 AFLMnu2CstStAvl 1 "true" 0 "false" ;
VAL_ 893 AFLGPSMnu2CstStAvl 1 "true" 0 "false" ;
VAL_ 893 AFLGPSCstStAvl 1 "true" 0 "false" ;
VAL_ 893 AFLGPSCstCrStVal 0 "No Value" 1 "Corner And Curve Lighting Only" 2 "Intelligent Light Distribution" 3 "GPS Assistance" 4 "Reserved1" 5 "Reserved2" 6 "Reserved3" 7 "Off" ;
VAL_ 893 AFLCstStAvl 1 "true" 0 "false" ;
VAL_ 893 AFLCstCrStVal 0 "No Value" 1 "Corner And Curve Lighting Only" 2 "Intelligent Light Distribution" 3 "Reserved1" 4 "Reserved2" 5 "Reserved3" 6 "Reserved4" 7 "Off" ;
VAL_ 892 AdpHgBmAsSnCsCrStVal 0 "No Value" 1 "Off" 2 "On Normal Sensitivity" 3 "On Reduced Sensitivity" 4 "Reserved1" 5 "Reserved2" 6 "Reserved3" 7 "Reserved4" ;
VAL_ 892 AdpHgBmAsSnCsStAvl 1 "true" 0 "false" ;
VAL_ 892 AdpHgBmAsCsCrStVal 0 "No Value" 1 "Off" 2 "On" 3 "Reserved1" 4 "Reserved2" 5 "Reserved3" 6 "Reserved4" 7 "Reserved5" ;
VAL_ 892 AdpHgBmAsCsStAvl 1 "true" 0 "false" ;
VAL_ 892 AutHgBmAsCsCrStVal 0 "No Value" 1 "Off" 2 "On" 3 "Reserved1" 4 "Reserved2" 5 "Reserved3" 6 "Reserved4" 7 "Reserved5" ;
VAL_ 892 AutHgBmAsSnCsStAvl 1 "true" 0 "false" ;
VAL_ 892 AutHgBmAsSnCsCrStVa 0 "No Value" 1 "Off" 2 "On Normal Sensitivity" 3 "On Reduced Sensitivity" 4 "Reserved1" 5 "Reserved2" 6 "Reserved3" 7 "Reserved4" ;
VAL_ 892 AutHgBmAsCsStAvl 1 "true" 0 "false" ;
VAL_ 386 AHAct 1 "true" 0 "false" ;
VAL_ 386 AHEnbld 1 "true" 0 "false" ;
VAL_ 386 ShfToPrkBfExtngIO 1 "true" 0 "false" ;
VAL_ 386 AHServcIO 1 "true" 0 "false" ;
VAL_ 386 AHAppBrkPedlIO 1 "true" 0 "false" ;
VAL_ 386 AHDisbldStbltIO 1 "true" 0 "false" ;
VAL_ 386 AHDisbldDrOpnIO 1 "true" 0 "false" ;
VAL_ 386 PMVSS_Disps 7 "Visualization Type 7" 6 "Visualization Type 6" 5 "Visualization Type 5" 4 "Visualization Type 4" 3 "Visualization Type 3" 2 "Visualization Type 2" 1 "Visualization Type 1" 0 "No Action" ;
VAL_ 386 PMVSS_Exhst 7 "Visualization Type 7" 6 "Visualization Type 6" 5 "Visualization Type 5" 4 "Visualization Type 4" 3 "Visualization Type 3" 2 "Visualization Type 2" 1 "Visualization Type 1" 0 "No Action" ;
VAL_ 386 PMVSS_PsngrSeat 7 "Visualization Type 7" 6 "Visualization Type 6" 5 "Visualization Type 5" 4 "Visualization Type 4" 3 "Visualization Type 3" 2 "Visualization Type 2" 1 "Visualization Type 1" 0 "No Action" ;
VAL_ 386 PMVSS_DrvrSeat 7 "Visualization Type 7" 6 "Visualization Type 6" 5 "Visualization Type 5" 4 "Visualization Type 4" 3 "Visualization Type 3" 2 "Visualization Type 2" 1 "Visualization Type 1" 0 "No Action" ;
VAL_ 386 PMVSS_AdptCrsCnt 7 "Visualization Type 7" 6 "Visualization Type 6" 5 "Visualization Type 5" 4 "Visualization Type 4" 3 "Visualization Type 3" 2 "Visualization Type 2" 1 "Visualization Type 1" 0 "No Action" ;
VAL_ 386 PMVSS_Drvln 7 "Visualization Type 7" 6 "Visualization Type 6" 5 "Visualization Type 5" 4 "Visualization Type 4" 3 "Visualization Type 3" 2 "Visualization Type 2" 1 "Visualization Type 1" 0 "No Action" ;
VAL_ 386 PMVSS_Susp 7 "Visualization Type 7" 6 "Visualization Type 6" 5 "Visualization Type 5" 4 "Visualization Type 4" 3 "Visualization Type 3" 2 "Visualization Type 2" 1 "Visualization Type 1" 0 "No Action" ;
VAL_ 386 PMVSS_Strng 7 "Visualization Type 7" 6 "Visualization Type 6" 5 "Visualization Type 5" 4 "Visualization Type 4" 3 "Visualization Type 3" 2 "Visualization Type 2" 1 "Visualization Type 1" 0 "No Action" ;
VAL_ 386 PMVSS_Trans 7 "Visualization Type 7" 6 "Visualization Type 6" 5 "Visualization Type 5" 4 "Visualization Type 4" 3 "Visualization Type 3" 2 "Visualization Type 2" 1 "Visualization Type 1" 0 "No Action" ;
VAL_ 386 PMVSS_Eng 7 "Visualization Type 7" 6 "Visualization Type 6" 5 "Visualization Type 5" 4 "Visualization Type 4" 3 "Visualization Type 3" 2 "Visualization Type 2" 1 "Visualization Type 1" 0 "No Action" ;
VAL_ 386 PMVSS_Snd 7 "Visualization Type 7" 6 "Visualization Type 6" 5 "Visualization Type 5" 4 "Visualization Type 4" 3 "Visualization Type 3" 2 "Visualization Type 2" 1 "Visualization Type 1" 0 "No Action" ;
VAL_ 386 EnvIdRspSt4 3 "Environment_id_request" 2 "Incorrect_immo_id" 1 "Info_valid" 0 "No_info" ;
VAL_ 386 AdptCruzCtrlStg 7 "Performance Mode 7" 6 "Performance Mode 6" 5 "Performance Mode 5" 4 "Performance Mode 4" 3 "Performance Mode 3" 2 "Performance Mode 2" 1 "Performance Mode 1" 0 "No Action" ;
VAL_ 532 RedntVSEAct 1 "true" 0 "false" ;
VAL_ 532 VehHldDrvrDsblActvFlg 1 "true" 0 "false" ;
VAL_ 532 AutoBrkngAvlbl 1 "true" 0 "false" ;
VAL_ 532 ABSAutnmsBrkReq 1 "true" 0 "false" ;
VAL_ 532 ABSActvProt 1 "true" 0 "false" ;
VAL_ 532 HilRlbkCtrlActIO 1 "true" 0 "false" ;
VAL_ 532 HlStrAssActIO 1 "true" 0 "false" ;
VAL_ 532 BrkSysAutBrkFld 1 "true" 0 "false" ;
VAL_ 532 IntBrkAssPreFilReq 1 "true" 0 "false" ;
VAL_ 532 BrkSysMalFuncIndOn 1 "true" 0 "false" ;
VAL_ 532 BPDAPS_BkPDrvApPV 1 "Invalid" 0 "Valid" ;
VAL_ 532 BrkFldLvlLwV 1 "Invalid" 0 "Valid" ;
VAL_ 532 BrkFldLvlLw 1 "true" 0 "false" ;
VAL_ 532 AutoBrkngAct 1 "true" 0 "false" ;
VAL_ 890 LtRtHnTrGPCsCrStVal 0 "No Value" 1 "Left Hand Traffic" 2 "Right Hand Traffic" 3 "Automatic" 4 "Reserved1" 5 "Reserved2" 6 "Reserved3" 7 "Reserved4" ;
VAL_ 890 LtRtHnTrGPSCsStAvl 1 "true" 0 "false" ;
VAL_ 890 LtRtHnTrCstStVal 0 "No Value" 1 "Left Hand Drive" 2 "Right Hand Drive" ;
VAL_ 890 LtRtHnTrCstStAvail 0 "Not Available" 1 "Present" ;
VAL_ 328 StrngAsstRdcdIO 1 "true" 0 "false" ;
VAL_ 328 PwrStrIO 1 "true" 0 "false" ;
VAL_ 560 ElecPrkBrkSwStatV 1 "Invalid" 0 "Valid" ;
VAL_ 560 ElecPrkBrkSwStat 3 "Active" 2 "Apply" 1 "state0800" 0 "NotActive" ;
VAL_ 560 EPBC_EPBrkAutBrkRq 1 "true" 0 "false" ;
VAL_ 560 AllNodesVNA 1 "Activate Virtual Network" 0 "No Activation" ;
VAL_ 560 StpOnBrkToRelPBIndOn 1 "true" 0 "false" ;
VAL_ 560 EPBSysDspMsgReq 7 "Message #7" 6 "Message #6" 5 "Message #5" 4 "Message #4" 3 "Message #3" 2 "Message #2" 1 "Message #1" 0 "Off" ;
VAL_ 560 EPBSysAudWarnReq 2 "Warning #2" 1 "Warning #1" 0 "Off" ;
VAL_ 560 ElecPrkBrkStat 2 "Fault" 1 "Applied" 0 "state0800d" ;
VAL_ 560 EPBCrsCanRq 1 "true" 0 "false" ;
VAL_ 560 EPBSysStatIndReq 3 "Flash Rate 2 Indication" 2 "Flash Rate 1 Indication" 1 "Continuous Indication" 0 "No Indication" ;
VAL_ 560 EPBSysWrnIndReq 3 "Flash Rate #2 Indication" 2 "Flash Rate #1 Indication" 1 "Continuous Indication" 0 "No Indication" ;
VAL_ 560 EPBSysBrkLtsReq 1 "true" 0 "false" ;
VAL_ 1282 TireTrdTmpStat 0 "No Action (unknown)" 1 "Frozen" 2 "Cold" 3 "Warm" 4 "Hot" 5 "Overheated" ;
VAL_ 1282 AllNodesVNA_502 1 "Activate Virtual Network" 0 "No Activation" ;
VAL_ 1282 A3ERRAlrmReq 0 "No Action" 1 "Set Alarm" 2 "Cancel Alarm" ;
VAL_ 1219 DslExhFldDiagWrnIdRq 0 "No Indication" 1 "Warning Level 1" 2 "Warning Level 2" 3 "Warning Level 3" 4 "Warning Level 4" 5 "Warning Level 5" 6 "Warning Level 6" 7 "Warning Level 7" ;
VAL_ 1219 DslEmnsOBDMrkt 0 "USEPA TIER 2 / CALIFORNIA LEV II" 1 "EURO5/6" ;
VAL_ 1219 DslExNxEmWrngIndRq 15 "Warning Level 15" 14 "Warning Level 14" 13 "Warning Level 13" 12 "Warning Level 12" 11 "Warning Level 11" 10 "Warning Level 10" 9 "Warning Level 9" 8 "Warning Level 8" 7 "Warning Level 7" 6 "Warning Level 6" 5 "Warning Level 5" 4 "Warning Level 4" 3 "Warning Level 3" 2 "Warning Level 2" 1 "Warning Level 1" 0 "No Indication" ;
VAL_ 1219 DslExFldTpWrngIndRq 15 "Warning Level 15" 14 "Warning Level 14" 13 "Warning Level 13" 12 "Warning Level 12" 11 "Warning Level 11" 10 "Warning Level 10" 9 "Warning Level 9" 8 "Warning Level 8" 7 "Warning Level 7" 6 "Warning Level 6" 5 "Warning Level 5" 4 "Warning Level 4" 3 "Warning Level 3" 2 "Warning Level 2" 1 "Warning Level 1" 0 "No Indication" ;
VAL_ 1219 DslExhFldQlyWrngIReq 15 "Warning Level 15" 14 "Warning Level 14" 13 "Warning Level 13" 12 "Warning Level 12" 11 "Warning Level 11" 10 "Warning Level 10" 9 "Warning Level 9" 8 "Warning Level 8" 7 "Warning Level 7" 6 "Warning Level 6" 5 "Warning Level 5" 4 "Warning Level 4" 3 "Warning Level 3" 2 "Warning Level 2" 1 "Warning Level 1" 0 "No Indication" ;
VAL_ 1219 DslExhFldWrngIdRqER 15 "Warning Level 15" 14 "Warning Level 14" 13 "Warning Level 13" 12 "Warning Level 12" 11 "Warning Level 11" 10 "Warning Level 10" 9 "Warning Level 9" 8 "Warning Level 8" 7 "Warning Level 7" 6 "Warning Level 6" 5 "Warning Level 5" 4 "Warning Level 4" 3 "Warning Level 3" 2 "Warning Level 2" 1 "Warning Level 1" 0 "No Indication" ;
VAL_ 1219 DslExFldCnWrngIndRq 15 "Warning Level 15" 14 "Warning Level 14" 13 "Warning Level 13" 12 "Warning Level 12" 11 "Warning Level 11" 10 "Warning Level 10" 9 "Warning Level 9" 8 "Warning Level 8" 7 "Warning Level 7" 6 "Warning Level 6" 5 "Warning Level 5" 4 "Warning Level 4" 3 "Warning Level 3" 2 "Warning Level 2" 1 "Warning Level 1" 0 "No Indication" ;
VAL_ 442 CrksftTqMinImCapV 1 "Invalid" 0 "Valid" ;
VAL_ 442 CrksftMaxTrqLmtV 1 "Invalid" 0 "Valid" ;
VAL_ 988 EGHRInhbtRqstd 1 "true" 0 "false" ;
VAL_ 988 AccPwrModMinCoolRq 0 "None" 1 "Minimum" 2 "Low" 3 "Medium" 4 "High" ;
VAL_ 988 A6ERRAlrmReq 2 "Cancel Alarm" 1 "Set Alarm" 0 "No Action" ;
VAL_ 988 MntnceMdDsplyRq 15 "Unused and Reserved" 14 "Continue FM" 13 "Force FM" 12 "FM 1 Day Warning" 11 "FM 2 Day Warning" 10 "FM 3 Day Warning" 9 "FM 4 Day Warning" 8 "FM 5 Day Warning" 7 "Continue EM" 6 "Force EM" 5 "EM 1 Day Warning" 4 "EM 2 Day Warning" 3 "EM 3 Day Warning" 2 "EM 4 Day Warning" 1 "EM 5 Day Warning" 0 "No Request" ;
VAL_ 988 EngMntnceMdAct 1 "true" 0 "false" ;
VAL_ 988 HVPropChgrUnbl 1 "true" 0 "false" ;
VAL_ 988 EngHtrValvBpasCmd 0 "Bypass Commanded" 1 "Normal Operation Allowed" ;
VAL_ 500 EnhDrvMdSwChUseAct 1 "true" 0 "false" ;
VAL_ 500 EnhDrvSelMdSwStat 0 "No Activation" 1 "Increment" 2 "Decrement" 3 "Faulted" ;
VAL_ 500 DrvSelMd8Stat 1 "Active" 0 "Inactive" ;
VAL_ 500 DrvSelMd8ReqDnd 1 "true" 0 "false" ;
VAL_ 500 DrvSelMd7Stat 1 "Active" 0 "Inactive" ;
VAL_ 500 DrvSelMd7ReqDnd 1 "true" 0 "false" ;
VAL_ 500 DrvSelMd6Stat 1 "Active" 0 "Inactive" ;
VAL_ 500 DrvSelMd6ReqDnd 1 "true" 0 "false" ;
VAL_ 500 DrvSelMd5Stat 1 "Active" 0 "Inactive" ;
VAL_ 500 DrvSelMd5ReqDnd 1 "true" 0 "false" ;
VAL_ 500 DrvSelMd4Stat 1 "Active" 0 "Inactive" ;
VAL_ 500 DrvSelMd4ReqDnd 1 "true" 0 "false" ;
VAL_ 500 DrvSelMd3Stat 1 "Active" 0 "Inactive" ;
VAL_ 500 DrvSelMd3ReqDnd 1 "true" 0 "false" ;
VAL_ 500 DrvSelMd2Stat 1 "Active" 0 "Inactive" ;
VAL_ 500 DrvSelMd2ReqDnd 1 "true" 0 "false" ;
VAL_ 500 DSMSS_DrvSelMd0Pn 1 "true" 0 "false" ;
VAL_ 500 DSMSS_DrvSelMd8Pn 1 "true" 0 "false" ;
VAL_ 500 DSMSS_DrvSelMd7Pn 1 "true" 0 "false" ;
VAL_ 500 DSMSS_DrvSelMd6Pn 1 "true" 0 "false" ;
VAL_ 500 DSMSS_DrvSelMd5Pn 1 "true" 0 "false" ;
VAL_ 500 DSMSS_DrvSelMd4Pn 1 "true" 0 "false" ;
VAL_ 500 DSMSS_DrvSelMd3Pn 1 "true" 0 "false" ;
VAL_ 500 DSMSS_DrvSelMd2Pn 1 "true" 0 "false" ;
VAL_ 500 DSMSS_DrvSelMd1Pn 1 "true" 0 "false" ;
VAL_ 500 DSMSS_DrvSelMd8Un 1 "true" 0 "false" ;
VAL_ 500 DSMSS_DrvSelMd7Un 1 "true" 0 "false" ;
VAL_ 500 DSMSS_DrvSelMd6Un 1 "true" 0 "false" ;
VAL_ 500 DSMSS_DrvSelMd5Un 1 "true" 0 "false" ;
VAL_ 500 DSMSS_DrvSelMd4Un 1 "true" 0 "false" ;
VAL_ 500 DSMSS_DrvSelMd3Un 1 "true" 0 "false" ;
VAL_ 500 DSMSS_DrvSelMd2Un 1 "true" 0 "false" ;
VAL_ 500 DSMSS_DrvSelMd1Un 1 "true" 0 "false" ;
VAL_ 500 DrvSelMd1ReqDnd 1 "true" 0 "false" ;
VAL_ 500 DrvSelMd1Stat 1 "Active" 0 "Inactive" ;
VAL_ 1417 ETC_EngOpMd 1 "Half Cylinders" 0 "All cylinders" ;
VAL_ 170 EngCommFlrRedPwrCm 1 "true" 0 "false" ;
VAL_ 170 CmndAxlTrqRespTyp 0 "Inactive" 1 "Pleasability Limit" 2 "Maximum Range" 3 "Automatic Actuator Selection" ;
VAL_ 979 SpdLmtrSttngTypAct 3 "Reserved" 2 "Auto" 1 "Manual" 0 "Off" ;
VAL_ 979 SetSpdLmtRchd 3 "Reserved" 2 "Low limit reached" 1 "High limit reached" 0 "No limit reached" ;
VAL_ 979 ElvtdIdlCstCrStVal 0 "No Action" 1 "Off" 2 "On" ;
VAL_ 979 ElvtdIdlCstStAvl 1 "true" 0 "false" ;
VAL_ 979 PTABR_PTBrkRqAct 1 "true" 0 "false" ;
VAL_ 979 BrkBstVacV 1 "Invalid" 0 "Valid" ;
VAL_ 979 EngManfldAirTempCrtdV 1 "Invalid" 0 "Valid" ;
VAL_ 979 PltfrmEngSpdCmmndSt 3 "Request Denied" 2 "Lost Arbitration" 1 "Request Honored" 0 "No Request" ;
VAL_ 647 CrnksftTqModRspMxCapV 1 "Invalid" 0 "Valid" ;
VAL_ 647 EngDetPndTrnCsRngShfV 1 "Invalid" 0 "Valid" ;
VAL_ 647 EngDetPndTrnCsRngShf 3 "Shift Out of Neutral Range" 2 "Shift Out of Low Range" 1 "Shift Out of High Range" 0 "None" ;
VAL_ 647 CrpCstCrvCmd 7 "Creep Coast Curve 7" 6 "Creep Coast Curve 6" 5 "Creep Coast Curve 5" 4 "Creep Coast Curve 4" 3 "Creep Coast Curve 3" 2 "Creep Coast Curve 2" 1 "Creep Coast Curve 1" 0 "Creep Coast Curve 0" ;
VAL_ 647 DrvMntnMdCmnd 1 "true" 0 "false" ;
VAL_ 647 DrvHldMdCmnd 1 "true" 0 "false" ;
VAL_ 647 DrPTGrdBrkDsbMdCmd 1 "true" 0 "false" ;
VAL_ 647 DrvWntrMdCmd 1 "true" 0 "false" ;
VAL_ 647 DrvTwHaulMdCmd 1 "true" 0 "false" ;
VAL_ 647 DrvSprtMdCmd 1 "true" 0 "false" ;
VAL_ 647 DrvEconMdCmd 1 "true" 0 "false" ;
VAL_ 647 EngCntrlDtrmdTrfCRngV 1 "Invalid" 0 "Valid" ;
VAL_ 647 EngCntrlDtrmdTrfCRng 3 "Neutral" 2 "Unused and Reserved" 1 "Low" 0 "High" ;
VAL_ 647 EngCntrlUtldTrnCsRng 3 "Neutral" 2 "Unused and Reserved" 1 "Low" 0 "High" ;
VAL_ 647 EngCntrlUtldTrnCsRgIn 1 "true" 0 "false" ;
VAL_ 1187 VehGrdSnsrBsdV 1 "Invalid" 0 "Valid" ;
VAL_ 487 EngRunng 1 "true" 0 "false" ;
VAL_ 487 FlPmpEDscOtptCmdSta 1 "Fuel Pump Enabled" 0 "Fuel Pump Disabled" ;
VAL_ 487 FuelCntlSysFltPrsnt 1 "true" 0 "false" ;
VAL_ 487 HiPresFuelPmpCntMd 6 "Zero Flow Mode" 5 "Noise Control Max Mode" 4 "Noise Control Disable Mode" 3 "Start Mode" 2 "Normal Mode" 1 "DFCO Mode" 0 "Disable Mode" ;
VAL_ 398 EngNTrnsRegStdyStTqV 1 "Invalid" 0 "Valid" ;
VAL_ 398 AccKdwnAtv 1 "true" 0 "false" ;
VAL_ 398 EngActStdyStTorqV 1 "Invalid" 0 "Valid" ;
VAL_ 398 TrnsEngSpdReqFld 1 "true" 0 "false" ;
VAL_ 398 PTACCAct 1 "true" 0 "false" ;
VAL_ 398 CTSS_StbltyLvl 7 "Level 7" 6 "Level 6" 5 "Level 5" 4 "Level 4" 3 "Level 3" 2 "Level 2" 1 "Level 1" 0 "Level 0" ;
VAL_ 398 CTSS_StbltyTyp 7 "Unused and Reserved 4" 6 "Unused and Reserved 3" 5 "Unused and Reserved 2" 4 "Unused and Reserved 1" 3 "Torque Increase Pending" 2 "Torque Decrease Pending" 1 "Torque High Pulsation" 0 "Normal Stability" ;
VAL_ 398 EngImmTrqTnsRqStat 0 "No Request" 7 "Unused and Reserved" 6 "Control System Failure Permanent" 5 "Control System Failure Temporary" 4 "Serial Data Failure Permanent" 3 "Serial Data Failure Temporary" 2 "Lost Arbitration" 1 "Request Honored" ;
VAL_ 398 EngImmTrqTnsRqLmSt 7 "Unused and Reserved 4" 6 "Unused and Reserved 3" 5 "Unused and Reserved 2" 4 "Unused and Reserved 1" 3 "Value Limited High" 2 "Value Limited Low" 1 "Rate Limited" 0 "Not Limited" ;
VAL_ 398 EngPrdctTrqTnsRqStat 7 "Unused and Reserved" 6 "Control System Failure Permanent" 5 "Control System Failure Temporary" 4 "Serial Data Failure Permanent" 3 "Serial Data Failure Temporary" 2 "Lost Arbitration" 1 "Request Honored" 0 "No Request" ;
VAL_ 398 EngPrdctTrqTnsRqLmS 7 "Unused and Reserved 4" 6 "Unused and Reserved 3" 5 "Unused and Reserved 2" 4 "Unused and Reserved 1" 3 "Value Limited High" 2 "Value Limited Low" 1 "Rate Limited" 0 "Not Limited" ;
SIG_GROUP_ 565 PsngStPerfMdCustAvl 1 : PSPMCA_PsngStPrfMd6Avl PSPMCA_PsngStPrfMd5Avl PSPMCA_PsngStPrfMd4Avl PSPMCA_PsngStPrfMd3Avl PSPMCA_PsngStPrfMd2Avl PSPMCA_PsngStPrfMd1Avl;
SIG_GROUP_ 565 DrvStyPerfMdCustAvl 1 : DSPMCA_DrvStyPrfMd7Avl DSPMCA_DrvStyPrfMd6Avl DSPMCA_DrvStyPrfMd5Avl DSPMCA_DrvStyPrfMd4Avl DSPMCA_DrvStyPrfMd3Avl DSPMCA_DrvStyPrfMd2Avl DSPMCA_DrvStyPrfMd1Avl;
SIG_GROUP_ 565 DrvrStPerfMdCustAvl 1 : DSPMCA_DrvrStPrfMd6Avl DSPMCA_DrvrStPrfMd5Avl DSPMCA_DrvrStPrfMd4Avl DSPMCA_DrvrStPrfMd3Avl DSPMCA_DrvrStPrfMd2Avl DSPMCA_DrvrStPrfMd1Avl;
SIG_GROUP_ 565 ACCPerfMdCustAvl 1 : ACCPMCA_ACCPrfMd6Avl ACCPMCA_ACCPrfMd5Avl ACCPMCA_ACCPrfMd4Avl ACCPMCA_ACCPrfMd3Avl ACCPMCA_ACCPrfMd2Avl ACCPMCA_ACCPrfMd1Avl;
SIG_GROUP_ 1296 VhlAhdDstIndReq 1 : VADIR_IndLvl VADIR_FlwTme VADIR_FlwDst;
SIG_GROUP_ 386 PerfMdVislztnScrnStat 1 : PMVSS_Disps PMVSS_Exhst PMVSS_PsngrSeat PMVSS_DrvrSeat PMVSS_AdptCrsCnt PMVSS_Drvln PMVSS_Susp PMVSS_Strng PMVSS_Trans PMVSS_Eng PMVSS_Snd;
SIG_GROUP_ 532 BrkPdDrvAppPrsStat 1 : BPDAPS_BkPDrvApPV BPDAPS_BkPDrvApP;
SIG_GROUP_ 560 ElecPrkBrkCmd 1 : EPBC_EPBAccRq EPBC_EPBrkAutBrkRq;
SIG_GROUP_ 1282 Alrm3ExtRngReq 1 : A3ERRAlrmTime A3ERRAlrmReq;
SIG_GROUP_ 1219 DslExFldWrngVSpdLmt 1 : DEFWVSL_S3SpdLmt DEFWVSL_S2SpdLmt DEFWVSL_S1SpdLmt;
SIG_GROUP_ 988 Alrm6ExtRngReq 1 : A6ERRAlrmTime A6ERRAlrmReq;
SIG_GROUP_ 500 DrvSelMdSelnStat 1 : DSMSS_DrvSelMd0Pn DSMSS_DrvSelMd8Pn DSMSS_DrvSelMd7Pn DSMSS_DrvSelMd6Pn DSMSS_DrvSelMd5Pn DSMSS_DrvSelMd4Pn DSMSS_DrvSelMd3Pn DSMSS_DrvSelMd2Pn DSMSS_DrvSelMd1Pn DSMSS_DrvSelMd8Un DSMSS_DrvSelMd7Un DSMSS_DrvSelMd6Un DSMSS_DrvSelMd5Un DSMSS_DrvSelMd4Un DSMSS_DrvSelMd3Un DSMSS_DrvSelMd2Un DSMSS_DrvSelMd1Un;
SIG_GROUP_ 1417 EngTorqCapblty 1 : ETC_MinTorq ETC_MinRunTorq ETC_MaxTorq ETC_RefEngSpd ETC_UnsdRsrvd ETC_FrmCntr ETC_EngOpMd;
SIG_GROUP_ 979 PTAutoBrkReq 1 : PTABR_AccReq PTABR_PTBrkRqAct;
SIG_GROUP_ 398 CrksftTrqStbStat 1 : CTSS_StbltyLvl CTSS_StbltyTyp;
